VERSION ""

NS_ :

BS_:

BU_: AuxInput VT TECU TC Sprayer GPS

BO_ 2362179326 PD: 8 Vector__XXX
 SG_ ErrorElementNumber m13 : 4|12@1+ (1,0) [0|4095] "" Vector__XXX
 SG_ ErrorDDI m13 : 16|16@1+ (1,0) [0|65535] "" Vector__XXX
 SG_ ErrorCodeProcessData6 m13 : 37|1@1+ (1,0) [0|1] "" Vector__XXX
 SG_ ErrorCodeProcessData5 m13 : 36|1@1+ (1,0) [0|1] "" Vector__XXX
 SG_ ErrorCodeProcessData4 m13 : 35|1@1+ (1,0) [0|1] "" Vector__XXX
 SG_ ErrorCodeProcessData3 m13 : 34|1@1+ (1,0) [0|1] "" Vector__XXX
 SG_ ErrorCodeProcessData2 m13 : 33|1@1+ (1,0) [0|1] "" Vector__XXX
 SG_ ErrorCodeProcessData1 m13 : 32|1@1+ (1,0) [0|1] "" Vector__XXX
 SG_ Status_TotalsActive m15 : 32|1@1+ (1,0) [0|1] "" Vector__XXX
 SG_ ExecutedCommand m14 : 48|8@1+ (1,0) [0|65535] "" Vector__XXX
 SG_ SourceAddressWSM m14 : 40|8@1+ (1,0) [0|65535] "" Vector__XXX
 SG_ StatusBusyExecuting m14 : 35|1@1+ (1,0) [0|1] "" Vector__XXX
 SG_ StatusBusyReading m14 : 34|1@1+ (1,0) [0|1] "" Vector__XXX
 SG_ StatusBusySaving m14 : 33|1@1+ (1,0) [0|1] "" Vector__XXX
 SG_ StatusTotalsActive m14 : 32|1@1+ (1,0) [0|1] "" Vector__XXX
 SG_ ObjectIdChanged m13 : 8|16@1+ (1,0) [0|65535] "" Vector__XXX
 SG_ DesignatorLength m12 : 24|8@1+ (1,0) [0|255] "bytes" Vector__XXX
 SG_ ObjectIdToChange m12 : 8|16@1+ (1,0) [0|65535] "" Vector__XXX
 SG_ ErrorCodeChangeDesignator m13 : 24|8@1+ (1,0) [0|0] "" Vector__XXX
 SG_ ErrorCodeObjectPoolDelete m11 : 8|8@1+ (1,0) [0|0] "" Vector__XXX
 SG_ ErrorCodeObjPool4 m9 : 51|1@1+ (1,0) [0|0] "" Vector__XXX
 SG_ ErrorCodeObjPool3 m9 : 50|1@1+ (1,0) [0|0] "" Vector__XXX
 SG_ ErrorCodeObjPool2 m9 : 49|1@1+ (1,0) [0|0] "" Vector__XXX
 SG_ ErrorCodeObjPool1 m9 : 48|1@1+ (1,0) [0|0] "" Vector__XXX
 SG_ ErrorCodeObjPoolActiveResp3 m9 : 10|1@1+ (1,0) [0|0] "" Vector__XXX
 SG_ ErrorCodeObjPoolActiveResp2 m9 : 9|1@1+ (1,0) [0|0] "" Vector__XXX
 SG_ ErrorCodeObjPoolActiveResp1 m9 : 8|1@1+ (1,0) [0|0] "" Vector__XXX
 SG_ ObjectIdOfFaultyObject m9 : 32|16@1+ (1,0) [0|65535] "" Vector__XXX
 SG_ ParentObjectIdOfFaultyObject m9 : 16|16@1+ (1,0) [0|65535] "" Vector__XXX
 SG_ ReceivedDataSize m7 : 16|32@1+ (1,0) [0|4294967295] "bytes" Vector__XXX
 SG_ ErrorCodeObjPoolTransfer m7 : 8|8@1+ (1,0) [0|3] "" Vector__XXX
 SG_ Status m5 : 8|8@1+ (1,0) [0|1] "" Vector__XXX
 SG_ RequestTransferDataSize m4 : 8|32@1+ (1,0) [0|4294967295] "bytes" Vector__XXX
 SG_ TemperatureUnits m2 : 54|2@1+ (1,0) [0|3] "" Vector__XXX
 SG_ PressureUnits m2 : 52|2@1+ (1,0) [0|3] "" Vector__XXX
 SG_ ForceUnits m2 : 50|2@1+ (1,0) [0|3] "" Vector__XXX
 SG_ UnitsSystem m2 : 48|2@1+ (1,0) [0|3] "" Vector__XXX
 SG_ DistanceUnitCmd m2 : 46|2@1+ (1,0) [0|3] "" Vector__XXX
 SG_ AreaUnitCmd m2 : 44|2@1+ (1,0) [0|3] "" Vector__XXX
 SG_ VolumeUnitCmd m2 : 42|2@1+ (1,0) [0|3] "" Vector__XXX
 SG_ MassUnitCmd m2 : 40|2@1+ (1,0) [0|3] "" Vector__XXX
 SG_ DateFormatCmd m2 : 32|8@1+ (1,0) [0|255] "" Vector__XXX
 SG_ DecimalSymbolCmd m2 : 30|2@1+ (1,0) [0|3] "" Vector__XXX
 SG_ TimeFormatCmd m2 : 28|2@1+ (1,0) [0|3] "" Vector__XXX
 SG_ LanguageCodeCmd m2 : 8|16@1+ (1,0) [0|16383] "" Vector__XXX
 SG_ StructureLabel m1 : 8|56@1+ (1,0) [0|0] "" Vector__XXX
 SG_ DeviceDescriptionMsgType m1M : 4|4@1+ (1,0) [0|15] "" Vector__XXX
 SG_ VersionNumberISO11783Part10 m1 : 8|8@1- (1,0) [0|255] "" Vector__XXX
 SG_ TechnicalDataMsgType m0M : 4|4@1+ (1,0) [0|15] "" Vector__XXX
 SG_ Command M : 0|4@1+ (1,0) [0|15] "" Vector__XXX
 SG_ ElementNumber m2 : 4|12@1+ (1,0) [0|4095] "" Vector__XXX
 SG_ DDI m2M : 16|16@1+ (1,0) [0|65535] "" Vector__XXX
 SG_ MinMassPerAreaAppRate m152 : 32|32@1- (0.01,0) [0|2147480000] "mm³/m³" Vector__XXX
 SG_ DataDictionaryVersion m0 : 32|32@1- (1,0) [0|21474800] "" Vector__XXX
 SG_ RequestDefaultProcessData m57343 : 32|32@1- (1,0) [0|0] "" Vector__XXX
 SG_ AreaPerTimeCapacity m151 : 32|32@1- (1,0) [0|2147483647] "mm²/s" Vector__XXX
 SG_ FuelConsumptionPerArea m150 : 32|32@1- (1,0) [0|2147483647] "mm³/ m²" Vector__XXX
 SG_ FuelConsumptionPerTime m149 : 32|32@1- (1,0) [0|2147483647] "mm³/s" Vector__XXX
 SG_ TotalFuelConsumption m148 : 32|32@1- (1,0) [0|2147483647] "ml" Vector__XXX
 SG_ LogCount m147 : 32|32@1- (1,0) [0|2147483647] "" Vector__XXX
 SG_ PitchAngle m146 : 32|32@1- (0.001,0) [-180|180] "°" Vector__XXX
 SG_ RollAngle m145 : 32|32@1- (0.001,0) [-180|180] "°" Vector__XXX
 SG_ YawAngle m144 : 32|32@1- (0.001,0) [-180|180] "°" Vector__XXX
 SG_ ActualValueTimeLatency m143 : 32|32@1- (1,0) [-2147483647|2147483647] "ms" Vector__XXX
 SG_ SetpointTimeLatency m142 : 32|32@1- (1,0) [-2147483647|2147483647] "ms" Vector__XXX
 SG_ WorkState m141 : 32|32@1- (1,0) [0|3] "" Vector__XXX
 SG_ PercentageAppRateSetpoint m140 : 32|32@1- (1,0) [0|2147483647] "ppm" Vector__XXX
 SG_ DeviceCountCapacity m139 : 32|32@1- (1,0) [0|2147483647] "" Vector__XXX
 SG_ DeviceMassCapacity m138 : 32|32@1- (1,0) [0|2147483647] "g" Vector__XXX
 SG_ DeviceVolumeCapacity m137 : 32|32@1- (1,0) [0|2147483647] "ml" Vector__XXX
 SG_ DeviceElementOffsetZ m136 : 32|32@1- (1,0) [-2147483647|2147483647] "mm" Vector__XXX
 SG_ DeviceElementOffsetY m135 : 32|32@1- (1,0) [-2147483647|2147483647] "mm" Vector__XXX
 SG_ DeviceElementOffsetX m134 : 32|32@1- (1,0) [-2147483647|2147483647] "mm" Vector__XXX
 SG_ AuxiliaryValveInvertPorts m133 : 32|32@1- (1,0) [-2147480000|2147480000] "" Vector__XXX
 SG_ AuxiliaryValveProgressivRetract m132 : 32|32@1- (1,0) [-2147480000|2147480000] "" Vector__XXX
 SG_ AuxiliaryValveProgressivExtend m131 : 32|32@1- (1,0) [-2147483647|2147483647] "" Vector__XXX
 SG_ AuxiliaryValveFloatThreshold m130 : 32|32@1- (0.1,0) [-214748367.9|214748367.9] "%" Vector__XXX
 SG_ AuxiliaryValveRampRetractDown m129 : 32|32@1- (1,0) [-2147483647|2147483647] "ms" Vector__XXX
 SG_ AuxiliaryValveRampRetractUp m128 : 32|32@1- (1,0) [-2147483647|2147483647] "ms" Vector__XXX
 SG_ AuxiliaryValveRampExtendDown m127 : 32|32@1- (1,0) [-2147483647|2147483647] "ms" Vector__XXX
 SG_ AuxiliaryValveScalingRetract m125 : 32|32@1- (0.1,0) [-214748367.9|214748367.9] "%" Vector__XXX
 SG_ AuxiliaryValveScalingExtend m124 : 32|32@1- (0.1,0) [-214748367.9|214748367.9] "%" Vector__XXX
 SG_ AuxiliaryRampExtendUp m126 : 32|32@1- (1,0) [-2147483647|2147483647] "ms" Vector__XXX
 SG_ AppRateVolumePerArea_Set m1 : 32|32@1- (0.01,0) [0|21474836.47] "mm³/m²" Vector__XXX
 SG_ AppRateVolumePerArea_Act m2 : 32|32@1- (0.01,0) [0|21474836.47] "mm³/m²" Vector__XXX
 SG_ AppRateVolumePerArea_Def m3 : 32|32@1- (0.01,0) [0|21474836.47] "mm³/m²" Vector__XXX
 SG_ AppRateVolumePerArea_Min m4 : 32|32@1- (0.01,0) [0|21474836.47] "mm³/m²" Vector__XXX
 SG_ AppRateVolumePerArea_Max m5 : 32|32@1- (0.01,0) [0|21474836.47] "mm³/m²" Vector__XXX
 SG_ AppRateMassPerArea_Set m6 : 32|32@1- (1,0) [0|2147483647] "mg/m²" Vector__XXX
 SG_ AppRateMassPerArea_Act m7 : 32|32@1- (1,0) [0|2147483647] "mg/m²" Vector__XXX
 SG_ AppRateMassPerArea_Def m8 : 32|32@1- (1,0) [0|2147483647] "mg/m²" Vector__XXX
 SG_ AppRateMassPerArea_Min m9 : 32|32@1- (1,0) [0|2147483647] "mg/m²" Vector__XXX
 SG_ AppRateMassPerArea_Max m10 : 32|32@1- (1,0) [0|2147483647] "mg/m²" Vector__XXX
 SG_ AppRateCountPerArea_Set m11 : 32|32@1- (0.001,0) [0|2147483.647] "1/m²" Vector__XXX
 SG_ AppRateCountPerArea_Act m12 : 32|32@1- (0.001,0) [0|2147483.647] "1/m²" Vector__XXX
 SG_ AppRateCountPerArea_Def m13 : 32|32@1- (0.001,0) [0|2147483.647] "1/m²" Vector__XXX
 SG_ AppRateCountPerArea_Min m14 : 32|32@1- (0.001,0) [0|2147483.647] "1/m²" Vector__XXX
 SG_ AppRateCountPerArea_Max m15 : 32|32@1- (0.001,0) [0|2147483.647] "1/m²" Vector__XXX
 SG_ SetAppRateDistance_Set m16 : 32|32@1- (1,0) [0|2147483647] "mm" Vector__XXX
 SG_ AppRateDistance_Act m17 : 32|32@1- (1,0) [0|2147483647] "mm" Vector__XXX
 SG_ AppRateDistance_Def m18 : 32|32@1- (1,0) [0|2147483647] "mm" Vector__XXX
 SG_ AppRateDistance_Min m19 : 32|32@1- (1,0) [0|2147483647] "mm" Vector__XXX
 SG_ AppRateDistance_Max m20 : 32|32@1- (1,0) [0|2147483647] "mm" Vector__XXX
 SG_ AppRateVolumePerVolume_Set m21 : 32|32@1- (1,0) [0|2147483647] "mm³/m³" Vector__XXX
 SG_ AppRateVolumePerVolume_Act m22 : 32|32@1- (1,0) [0|2147483647] "mm³/m³" Vector__XXX
 SG_ AppRateVolumePerVolume_Def m23 : 32|32@1- (1,0) [0|2147483647] "mm³/m³" Vector__XXX
 SG_ AppRateVolumePerVolume_Min m24 : 32|32@1- (1,0) [0|2147483647] "mm³/m³" Vector__XXX
 SG_ AppRateVolumePerVolume_Max m25 : 32|32@1- (1,0) [0|2147483647] "mm³/m³" Vector__XXX
 SG_ AppRateMassPerMass_Set m26 : 32|32@1- (1,0) [0|2147483647] "mg/kg" Vector__XXX
 SG_ AppRateMassPerMass_Act m27 : 32|32@1- (1,0) [0|2147483647] "mg/kg" Vector__XXX
 SG_ AppRateMassPerMass_Def m28 : 32|32@1- (1,0) [0|2147483647] "mg/kg" Vector__XXX
 SG_ AppRateMassPerMass_Min m29 : 32|32@1- (1,0) [0|2147483647] "mg/kg" Vector__XXX
 SG_ AppRateMassPerMass_Max m30 : 32|32@1- (1,0) [0|2147483647] "mg/kg" Vector__XXX
 SG_ AppRateVolumePerMass_Set m31 : 32|32@1- (1,0) [0|2147483647] "mm³/kg" Vector__XXX
 SG_ AppRateVolumePerMass_Act m32 : 32|32@1- (1,0) [0|2147483647] "mm³/kg" Vector__XXX
 SG_ AppRateVolumePerMass_Def m33 : 32|32@1- (1,0) [0|2147483647] "mm³/kg" Vector__XXX
 SG_ AppRateVolumePerMass_Min m34 : 32|32@1- (1,0) [0|2147483647] "mm³/kg" Vector__XXX
 SG_ AppRateVolumePerMass_Max m35 : 32|32@1- (1,0) [0|2147483647] "mm³/kg" Vector__XXX
 SG_ AppRateVolumePerTime_Set m36 : 32|32@1- (1,0) [0|2147483647] "mm³/s" Vector__XXX
 SG_ AppRateVolumePerTime_Act m37 : 32|32@1- (1,0) [0|2147483647] "mm³/s" Vector__XXX
 SG_ AppRateVolumePerTime_Def m38 : 32|32@1- (1,0) [0|2147483647] "mm³/s" Vector__XXX
 SG_ AppRateVolumePerTime_Min m39 : 32|32@1- (1,0) [0|2147483647] "mm³/s" Vector__XXX
 SG_ AppRateVolumePerTime_Max m40 : 32|32@1- (1,0) [0|2147483647] "mm³/s" Vector__XXX
 SG_ AppRateMassPerTime_Set m41 : 32|32@1- (1,0) [0|2147483647] "mg/s" Vector__XXX
 SG_ AppRateMassPerTime_Act m42 : 32|32@1- (1,0) [0|2147483647] "mg/s" Vector__XXX
 SG_ AppRateMassPerTime_Def m43 : 32|32@1- (1,0) [0|2147483647] "mg/s" Vector__XXX
 SG_ AppRateMassPerTime_Min m44 : 32|32@1- (1,0) [0|2147483647] "mg/s" Vector__XXX
 SG_ AppRateMassPerTime_Max m45 : 32|32@1- (1,0) [0|2147483647] "mg/s" Vector__XXX
 SG_ AppRateCountPerTime_Set m46 : 32|32@1- (0.001,0) [0|2147483.647] "1/s" Vector__XXX
 SG_ AppRateCountPerTime_Act m47 : 32|32@1- (0.001,0) [0|2147483.647] "1/s" Vector__XXX
 SG_ AppRateCountPerTime_Def m48 : 32|32@1- (0.001,0) [0|2147483.647] "1/s" Vector__XXX
 SG_ AppRateCountPerTime_Min m49 : 32|32@1- (0.001,0) [0|2147483.647] "1/s" Vector__XXX
 SG_ AppRateCountPerTime_Max m50 : 32|32@1- (0.001,0) [0|2147483.647] "1/s" Vector__XXX
 SG_ SetTillageDepth_Set m51 : 32|32@1- (1,0) [0|2147483647] "mm" Vector__XXX
 SG_ TillageDepth_Act m52 : 32|32@1- (1,0) [0|2147483647] "mm" Vector__XXX
 SG_ TillageDepth_Def m53 : 32|32@1- (1,0) [0|2147483647] "mm" Vector__XXX
 SG_ TillageDepth_Min m54 : 32|32@1- (1,0) [0|2147483647] "mm" Vector__XXX
 SG_ TillageDepth_Max m55 : 32|32@1- (1,0) [0|2147483647] "mm" Vector__XXX
 SG_ SeedingDeph_Set m56 : 32|32@1- (1,0) [0|2147483647] "mm" Vector__XXX
 SG_ SeedingDeph_Act m57 : 32|32@1- (1,0) [0|2147483647] "mm" Vector__XXX
 SG_ SeedingDeph_Def m58 : 32|32@1- (1,0) [0|2147483647] "mm" Vector__XXX
 SG_ SeedingDeph_Min m59 : 32|32@1- (1,0) [0|2147483647] "mm" Vector__XXX
 SG_ SeedingDeph_Max m60 : 32|32@1- (1,0) [0|2147483647] "mm" Vector__XXX
 SG_ WorkingHeight_Set m61 : 32|32@1- (1,0) [0|2147483647] "mm" Vector__XXX
 SG_ WorkingHeight_Act m62 : 32|32@1- (1,0) [0|2147483647] "mm" Vector__XXX
 SG_ WorkingHeight_Def m63 : 32|32@1- (1,0) [0|2147483647] "mm" Vector__XXX
 SG_ WorkingHeight_Min m64 : 32|32@1- (1,0) [0|2147483647] "mm" Vector__XXX
 SG_ WorkingHeight_Max m65 : 32|32@1- (1,0) [0|2147483647] "mm" Vector__XXX
 SG_ WorkingWidth_Set m66 : 32|32@1- (1,0) [0|2147483647] "mm" Vector__XXX
 SG_ WorkingWidth_Act m67 : 32|32@1- (1,0) [0|2147483647] "mm" Vector__XXX
 SG_ WorkingWidth_Def m68 : 32|32@1- (1,0) [0|2147483647] "mm" Vector__XXX
 SG_ WorkingWidth_Min m69 : 32|32@1- (1,0) [0|2147483647] "mm" Vector__XXX
 SG_ WorkingWidth_Max m70 : 32|32@1- (1,0) [0|2147483647] "mm" Vector__XXX
 SG_ ContentAsVolume_Set m71 : 32|32@1- (1,0) [0|2147483647] "ml" Vector__XXX
 SG_ ContentAsVolume_Act m72 : 32|32@1- (1,0) [0|2147483647] "ml" Vector__XXX
 SG_ ContentAsVolume_Max m73 : 32|32@1- (1,0) [0|2147483647] "ml" Vector__XXX
 SG_ ContentAsMass_Set m74 : 32|32@1- (1,0) [0|2147483647] "g" Vector__XXX
 SG_ ContentAsMass_Act m75 : 32|32@1- (1,0) [0|2147483647] "g" Vector__XXX
 SG_ ContentAsMass_Max m76 : 32|32@1- (1,0) [0|2147483647] "g" Vector__XXX
 SG_ ContentAsCount_Set m77 : 32|32@1- (1,0) [0|2147483647] "" Vector__XXX
 SG_ ContentAsCount_Act m78 : 32|32@1- (1,0) [0|2147483647] "" Vector__XXX
 SG_ ContentAsCount_Max m79 : 32|32@1- (1,0) [0|2147483647] "" Vector__XXX
 SG_ AccumulatedAppAsVolume m80 : 32|32@1- (1,0) [0|2147483647] "l" Vector__XXX
 SG_ AccumulatedAppAsMass m81 : 32|32@1- (1,0) [0|2147483647] "kg" Vector__XXX
 SG_ AccumulatedAppAsCount m82 : 32|32@1- (1,0) [0|2147483647] "" Vector__XXX
 SG_ YieldVolumePerArea m83 : 32|32@1- (1,0) [0|2147483647] "ml/m²" Vector__XXX
 SG_ YieldMassPerArea m84 : 32|32@1- (1,0) [0|2147483647] "mg/m²" Vector__XXX
 SG_ YieldCountPerArea m85 : 32|32@1- (0.001,0) [0|2147483.647] "1/m²" Vector__XXX
 SG_ YieldVolumePerTime m86 : 32|32@1- (1,0) [0|2147483647] "ml/s" Vector__XXX
 SG_ YieldMassPerTime m87 : 32|32@1- (1,0) [0|2147483647] "mg/s" Vector__XXX
 SG_ YieldCountPerTime m88 : 32|32@1- (0.001,0) [0|2147483.647] "1/s" Vector__XXX
 SG_ AccumulatedYieldAsVolume m89 : 32|32@1- (1,0) [0|2147483647] "ml" Vector__XXX
 SG_ AccumulatedYieldAsMass m90 : 32|32@1- (1,0) [0|2147483647] "g" Vector__XXX
 SG_ AccumulatedYieldAsCount m91 : 32|32@1- (1,0) [0|2147483647] "" Vector__XXX
 SG_ CropYieldLossVolumePerArea m92 : 32|32@1- (1,0) [0|2147483647] "ml/m²" Vector__XXX
 SG_ CropYieldLossMassPerArea m93 : 32|32@1- (1,0) [0|2147483647] "mg/m²" Vector__XXX
 SG_ CropYieldLossCountPerArea m94 : 32|32@1- (0.001,0) [0|2147483.647] "1/m²" Vector__XXX
 SG_ CropYieldLossVolumePerTime m95 : 32|32@1- (1,0) [0|2147483647] "ml/s" Vector__XXX
 SG_ CropYieldLossMassPerTime m96 : 32|32@1- (1,0) [0|2147483647] "mg/s" Vector__XXX
 SG_ CropYieldLossCountPerTime m97 : 32|32@1- (0.001,0) [0|2147483.647] "1/s" Vector__XXX
 SG_ CropYieldLoss m98 : 32|32@1- (1,0) [0|2147483647] "ppm" Vector__XXX
 SG_ MoistureInCropYield m99 : 32|32@1- (1,0) [0|2147483647] "ppm" Vector__XXX
 SG_ DirtMaterialInCropYield m100 : 32|32@1- (1,0) [0|2147483647] "ppm" Vector__XXX
 SG_ BaleWidth_Set m101 : 32|32@1- (1,0) [0|2147483647] "mm" Vector__XXX
 SG_ BaleWidth_Act m102 : 32|32@1- (1,0) [0|2147483647] "mm" Vector__XXX
 SG_ BaleWidth_Def m103 : 32|32@1- (1,0) [0|2147483647] "mm" Vector__XXX
 SG_ BaleWidth_Min m104 : 32|32@1- (1,0) [0|2147483647] "mm" Vector__XXX
 SG_ BaleWidth_Max m105 : 32|32@1- (1,0) [0|2147483647] "mm" Vector__XXX
 SG_ BaleHeight_Set m106 : 32|32@1- (1,0) [0|2147483647] "mm" Vector__XXX
 SG_ BaleHeight_Act m107 : 32|32@1- (1,0) [0|2147483647] "mm" Vector__XXX
 SG_ BaleHeight_Def m108 : 32|32@1- (1,0) [0|2147483647] "mm" Vector__XXX
 SG_ BaleHeight_Min m109 : 32|32@1- (1,0) [0|2147483647] "mm" Vector__XXX
 SG_ BaleHeight_Max m110 : 32|32@1- (1,0) [0|2147483647] "mm" Vector__XXX
 SG_ BaleSize_Set m111 : 32|32@1- (1,0) [0|2147483647] "mm" Vector__XXX
 SG_ BaleSize_Act m112 : 32|32@1- (1,0) [0|2147483647] "mm" Vector__XXX
 SG_ BaleSize_Def m113 : 32|32@1- (1,0) [0|2147483647] "mm" Vector__XXX
 SG_ BaleSize_Min m114 : 32|32@1- (1,0) [0|2147483647] "mm" Vector__XXX
 SG_ BaleSize_Max m115 : 32|32@1- (1,0) [0|2147483647] "mm" Vector__XXX
 SG_ AccumulatedArea m116 : 32|32@1- (1,0) [0|2147483647] "m²" Vector__XXX
 SG_ AccumulatedDistanceInWork m117 : 32|32@1- (1,0) [0|2147483647] "mm" Vector__XXX
 SG_ AccumulatedDistanceOutWork m118 : 32|32@1- (1,0) [0|2147483647] "mm" Vector__XXX
 SG_ AccumulatedTimeInWork m119 : 32|32@1- (1,0) [0|2147483647] "s" Vector__XXX
 SG_ AccumulatedTimeOutWork m120 : 32|32@1- (1,0) [0|2147483647] "s" Vector__XXX
 SG_ PrdoucDensityMassPerArea m121 : 32|32@1- (1,0) [0|2147483647] "g/l" Vector__XXX
 SG_ PrdoucDensityMassPerCount m122 : 32|32@1- (1,0) [0|2147483647] "mg/1000" Vector__XXX
 SG_ PrdoucDensityVolumePerCount m123 : 32|32@1- (1,0) [0|2147483647] "ml/1000" Vector__XXX

BO_ 2565406462 ACKM: 8 Vector__XXX
 SG_ ParameterGroupNumber : 40|24@1+ (1,0) [0|0] "" Vector__XXX
 SG_ AddressBusy m3 : 32|8@1+ (1,0) [0|0] "" Vector__XXX
 SG_ AddressAccessDenied m2 : 32|8@1+ (1,0) [0|0] "" Vector__XXX
 SG_ AddressNegativeAcknowledgement m1 : 32|8@1+ (1,0) [0|0] "" Vector__XXX
 SG_ AddressAcknowledged m0 : 32|8@1+ (1,0) [0|0] "" Vector__XXX
 SG_ GroupFunctionValue : 8|8@1+ (1,0) [0|0] "" Vector__XXX
 SG_ ControlByte M : 0|8@1+ (1,0) [0|0] "" Vector__XXX

BO_ 2147483648 CAPL_IDS: 1785 Vector__XXX

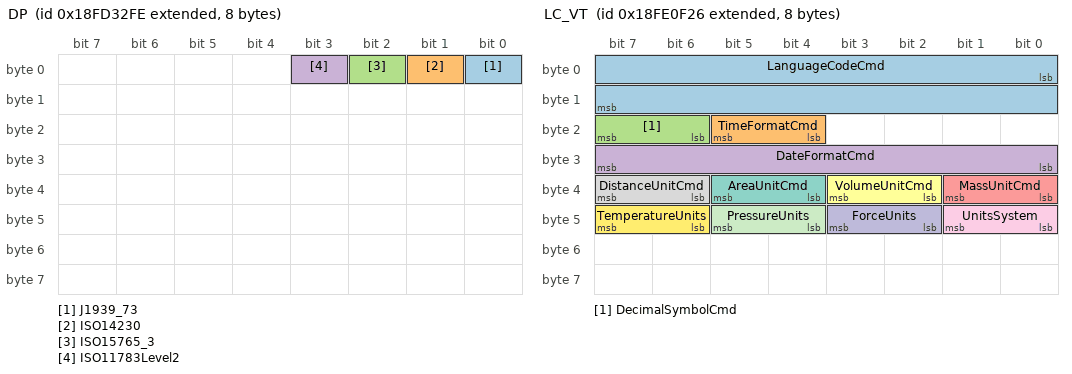
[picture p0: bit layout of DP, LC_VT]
BO_ 2566730494 DP: 8 Vector__XXX
 SG_ J1939_73 : 0|1@1+ (1,0) [0|1] "" Vector__XXX
 SG_ ISO14230 : 1|1@1+ (1,0) [0|1] "" Vector__XXX
 SG_ ISO15765_3 : 2|1@1+ (1,0) [0|1] "" Vector__XXX
 SG_ ISO11783Level2 : 3|1@1+ (1,0) [0|1] "" Vector__XXX

BO_ 2566734590 ICC: 8 Vector__XXX
 SG_ CertLaboratoryType_FirstDef m0 : 9|3@1+ (1,0) [0|7] "" Vector__XXX
 SG_ TestProtocolRevision_MSBits m1 : 11|2@1+ (1,0) [0|0] "" Vector__XXX
 SG_ MessageRevision M : 47|1@1+ (1,0) [0|0] "" Vector__XXX
 SG_ CertLaboratoryType_SecondDef m1 : 9|2@1+ (1,0) [0|3] "" Vector__XXX
 SG_ TestProtocolRevision : 6|3@1+ (1,0) [0|7] "" Vector__XXX
 SG_ TestProtocolPublicationYear : 0|6@1+ (1,2000) [2000|2061] "year" Vector__XXX
 SG_ CertificationLaboratoryID : 13|11@1+ (1,0) [0|2047] "" Vector__XXX
 SG_ CertTypeVTWorkingSetMember m0 : 24|1@1+ (1,0) [0|1] "" Vector__XXX
 SG_ CertTypeVTWorkingSetMaster m0 : 25|1@1+ (1,0) [0|1] "" Vector__XXX
 SG_ CertTypeVirtualTerminal m0 : 26|1@1+ (1,0) [0|1] "" Vector__XXX
 SG_ CertTypeClass3ECU m0 : 27|1@1+ (1,0) [0|1] "" Vector__XXX
 SG_ CertTypeTECUClass3 m0 : 28|1@1+ (1,0) [0|1] "" Vector__XXX
 SG_ CertTypeTECUClass2 m0 : 29|1@1+ (1,0) [0|1] "" Vector__XXX
 SG_ CertTypeTECUClass1 m0 : 30|1@1+ (1,0) [0|1] "" Vector__XXX
 SG_ CertTypeMinimumECU m0 : 31|1@1+ (1,0) [0|1] "" Vector__XXX
 SG_ CertTypeGPSReceiver m0 : 35|1@1+ (1,0) [0|1] "" Vector__XXX
 SG_ CertTypeFileServer m0 : 36|1@1+ (1,0) [0|1] "" Vector__XXX
 SG_ CertTypeTCWorkingSetMember m0 : 37|1@1+ (1,0) [0|1] "" Vector__XXX
 SG_ CertTypeTCWorkingSetMaster m0 : 38|1@1+ (1,0) [0|1] "" Vector__XXX
 SG_ CertTypeTaskController m0 : 39|1@1+ (1,0) [0|1] "" Vector__XXX
 SG_ CertificationReferenceNumber : 48|16@1+ (1,0) [0|65535] "" Vector__XXX

BO_ 2566835454 DM3: 0 Vector__XXX

BO_ 2633895296 WSMSTR_Sprayer: 8 Sprayer
 SG_ NumberOfMembersInWorkingSet : 0|8@1+ (1,0) [1|250] "" Vector__XXX

BO_ 2566786854 LC_VT: 8 VT
 SG_ LanguageCodeCmd : 0|16@1+ (1,0) [0|16383] ""  Sprayer
 SG_ TimeFormatCmd : 20|2@1+ (1,0) [0|3] "" Vector__XXX
 SG_ DecimalSymbolCmd : 22|2@1+ (1,0) [0|3] "" Vector__XXX
 SG_ DateFormatCmd : 24|8@1+ (1,0) [0|255] "" Vector__XXX
 SG_ MassUnitCmd : 32|2@1+ (1,0) [0|3] "" Vector__XXX
 SG_ VolumeUnitCmd : 34|2@1+ (1,0) [0|3] "" Vector__XXX
 SG_ AreaUnitCmd : 36|2@1+ (1,0) [0|3] "" Vector__XXX
 SG_ DistanceUnitCmd : 38|2@1+ (1,0) [0|3] "" Vector__XXX
 SG_ UnitsSystem : 40|2@1+ (1,0) [0|3] "" Vector__XXX
 SG_ ForceUnits : 42|2@1+ (1,0) [0|3] "" Vector__XXX
 SG_ PressureUnits : 44|2@1+ (1,0) [0|3] "" Vector__XXX
 SG_ TemperatureUnits : 46|2@1+ (1,0) [0|3] "" Vector__XXX

BO_ 2565799462 ACL_VT: 8 VT
 SG_ ArbitraryAddressCapable : 63|1@1+ (1,0) [0|1] "" Vector__XXX
 SG_ IndustryGroup M : 60|3@1+ (1,0) [0|7] "" Vector__XXX
 SG_ VehicleSystemInstance : 56|4@1+ (1,0) [0|15] "" Vector__XXX
 SG_ Function : 40|8@1+ (1,0) [0|255] "" Vector__XXX
 SG_ FunctionInstance : 35|5@1+ (1,0) [0|31] "" Vector__XXX
 SG_ ECUInstance : 32|3@1+ (1,0) [0|7] "" Vector__XXX
 SG_ ManufacturerCode : 21|11@1+ (1,0) [0|2047] "" Vector__XXX
 SG_ IdentityNumber : 0|21@1+ (1,0) [0|2097150] "" Vector__XXX
 SG_ VehicleSystem m0 : 49|7@1+ (1,0) [0|127] "" Vector__XXX
 SG_ VehicleSystem5 m5 : 49|7@1+ (1,0) [0|127] "" Vector__XXX
 SG_ VehicleSystem4 m4 : 49|7@1+ (1,0) [0|127] "" Vector__XXX
 SG_ VehicleSystem3 m3 : 49|7@1+ (1,0) [0|127] "" Vector__XXX
 SG_ VehicleSystem2 m2 : 49|7@1+ (1,0) [0|127] "" Vector__XXX
 SG_ VehicleSystem1 m1 : 49|7@1+ (1,0) [0|127] "" Vector__XXX

BO_ 2565799664 ACL_TECU: 8 TECU
 SG_ ArbitraryAddressCapable : 63|1@1+ (1,0) [0|1] "" Vector__XXX
 SG_ IndustryGroup M : 60|3@1+ (1,0) [0|7] "" Vector__XXX
 SG_ VehicleSystemInstance : 56|4@1+ (1,0) [0|15] "" Vector__XXX
 SG_ Function : 40|8@1+ (1,0) [0|255] "" Vector__XXX
 SG_ FunctionInstance : 35|5@1+ (1,0) [0|31] "" Vector__XXX
 SG_ ECUInstance : 32|3@1+ (1,0) [0|7] "" Vector__XXX
 SG_ ManufacturerCode : 21|11@1+ (1,0) [0|2047] "" Vector__XXX
 SG_ IdentityNumber : 0|21@1+ (1,0) [0|2097150] "" Vector__XXX
 SG_ VehicleSystem m0 : 49|7@1+ (1,0) [0|127] "" Vector__XXX
 SG_ VehicleSystem5 m5 : 49|7@1+ (1,0) [0|127] "" Vector__XXX
 SG_ VehicleSystem4 m4 : 49|7@1+ (1,0) [0|127] "" Vector__XXX
 SG_ VehicleSystem3 m3 : 49|7@1+ (1,0) [0|127] "" Vector__XXX
 SG_ VehicleSystem2 m2 : 49|7@1+ (1,0) [0|127] "" Vector__XXX
 SG_ VehicleSystem1 m1 : 49|7@1+ (1,0) [0|127] "" Vector__XXX

BO_ 2565799671 ACL_TC: 8 TC
 SG_ ArbitraryAddressCapable : 63|1@1+ (1,0) [0|1] "" Vector__XXX
 SG_ IndustryGroup M : 60|3@1+ (1,0) [0|7] "" Vector__XXX
 SG_ VehicleSystemInstance : 56|4@1+ (1,0) [0|15] "" Vector__XXX
 SG_ Function : 40|8@1+ (1,0) [0|255] "" Vector__XXX
 SG_ FunctionInstance : 35|5@1+ (1,0) [0|31] "" Vector__XXX
 SG_ ECUInstance : 32|3@1+ (1,0) [0|7] "" Vector__XXX
 SG_ ManufacturerCode : 21|11@1+ (1,0) [0|2047] "" Vector__XXX
 SG_ IdentityNumber : 0|21@1+ (1,0) [0|2097150] "" Vector__XXX
 SG_ VehicleSystem m0 : 49|7@1+ (1,0) [0|127] "" Vector__XXX
 SG_ VehicleSystem5 m5 : 49|7@1+ (1,0) [0|127] "" Vector__XXX
 SG_ VehicleSystem4 m4 : 49|7@1+ (1,0) [0|127] "" Vector__XXX
 SG_ VehicleSystem3 m3 : 49|7@1+ (1,0) [0|127] "" Vector__XXX
 SG_ VehicleSystem2 m2 : 49|7@1+ (1,0) [0|127] "" Vector__XXX
 SG_ VehicleSystem1 m1 : 49|7@1+ (1,0) [0|127] "" Vector__XXX

BO_ 2565799552 ACL_Sprayer: 8 Sprayer
 SG_ ArbitraryAddressCapable : 63|1@1+ (1,0) [0|1] "" Vector__XXX
 SG_ IndustryGroup M : 60|3@1+ (1,0) [0|7] "" Vector__XXX
 SG_ VehicleSystemInstance : 56|4@1+ (1,0) [0|15] "" Vector__XXX
 SG_ Function : 40|8@1+ (1,0) [0|255] "" Vector__XXX
 SG_ FunctionInstance : 35|5@1+ (1,0) [0|31] "" Vector__XXX
 SG_ ECUInstance : 32|3@1+ (1,0) [0|7] "" Vector__XXX
 SG_ ManufacturerCode : 21|11@1+ (1,0) [0|2047] "" Vector__XXX
 SG_ IdentityNumber : 0|21@1+ (1,0) [0|2097150] "" Vector__XXX
 SG_ VehicleSystem m0 : 49|7@1+ (1,0) [0|127] "" Vector__XXX
 SG_ VehicleSystem5 m5 : 49|7@1+ (1,0) [0|127] "" Vector__XXX
 SG_ VehicleSystem4 m4 : 49|7@1+ (1,0) [0|127] "" Vector__XXX
 SG_ VehicleSystem3 m3 : 49|7@1+ (1,0) [0|127] "" Vector__XXX
 SG_ VehicleSystem2 m2 : 49|7@1+ (1,0) [0|127] "" Vector__XXX
 SG_ VehicleSystem1 m1 : 49|7@1+ (1,0) [0|127] "" Vector__XXX

BO_ 2565799452 ACL_GPS: 8 GPS
 SG_ ArbitraryAddressCapable : 63|1@1+ (1,0) [0|1] "" Vector__XXX
 SG_ IndustryGroup M : 60|3@1+ (1,0) [0|7] "" Vector__XXX
 SG_ VehicleSystemInstance : 56|4@1+ (1,0) [0|15] "" Vector__XXX
 SG_ Function : 40|8@1+ (1,0) [0|255] "" Vector__XXX
 SG_ FunctionInstance : 35|5@1+ (1,0) [0|31] "" Vector__XXX
 SG_ ECUInstance : 32|3@1+ (1,0) [0|7] "" Vector__XXX
 SG_ ManufacturerCode : 21|11@1+ (1,0) [0|2047] "" Vector__XXX
 SG_ IdentityNumber : 0|21@1+ (1,0) [0|2097150] "" Vector__XXX
 SG_ VehicleSystem m0 : 49|7@1+ (1,0) [0|127] "" Vector__XXX
 SG_ VehicleSystem5 m5 : 49|7@1+ (1,0) [0|127] "" Vector__XXX
 SG_ VehicleSystem4 m4 : 49|7@1+ (1,0) [0|127] "" Vector__XXX
 SG_ VehicleSystem3 m3 : 49|7@1+ (1,0) [0|127] "" Vector__XXX
 SG_ VehicleSystem2 m2 : 49|7@1+ (1,0) [0|127] "" Vector__XXX
 SG_ VehicleSystem1 m1 : 49|7@1+ (1,0) [0|127] "" Vector__XXX

BO_ 2566835198 DM2: 22 Vector__XXX
 SG_ DTC5 : 144|32@1+ (1,0) [0|4294967295] "" Vector__XXX
 SG_ DTC4 : 112|32@1+ (1,0) [0|4294967295] "" Vector__XXX
 SG_ DTC3 : 80|32@1+ (1,0) [0|4294967295] "" Vector__XXX
 SG_ DTC2 : 48|32@1+ (1,0) [0|4294967295] "" Vector__XXX
 SG_ DTC1 : 16|32@1+ (1,0) [0|4294967295] "" Vector__XXX
 SG_ MalfunctionIndicatorLampStatus : 6|2@1+ (1,0) [0|3] "" Vector__XXX
 SG_ RedStopLampState : 4|2@1+ (1,0) [0|3] "" Vector__XXX
 SG_ AmberWarningLampStatus : 2|2@1+ (1,0) [0|3] "" Vector__XXX
 SG_ ProtectLampStatus : 0|2@1+ (1,0) [0|3] "" Vector__XXX
 SG_ FlashRedStopLamp : 12|2@1+ (1,0) [0|3] "" Vector__XXX
 SG_ FlashProtectLamp : 8|2@1+ (1,0) [0|3] "" Vector__XXX
 SG_ FlashMalfuncIndicatorLamp : 14|2@1+ (1,0) [0|3] "" Vector__XXX
 SG_ FlashAmberWarningLamp : 10|2@1+ (1,0) [0|3] "" Vector__XXX

BO_ 2566834942 DM1: 22 Vector__XXX
 SG_ DTC5 : 144|32@1+ (1,0) [0|4294967295] "" Vector__XXX
 SG_ DTC4 : 112|32@1+ (1,0) [0|4294967295] "" Vector__XXX
 SG_ DTC3 : 80|32@1+ (1,0) [0|4294967295] "" Vector__XXX
 SG_ DTC2 : 48|32@1+ (1,0) [0|4294967295] "" Vector__XXX
 SG_ DTC1 : 16|32@1+ (1,0) [0|4294967295] "" Vector__XXX
 SG_ FlashRedStopLamp : 12|2@1+ (1,0) [0|3] "" Vector__XXX
 SG_ FlashProtectLamp : 8|2@1+ (1,0) [0|3] "" Vector__XXX
 SG_ FlashMalfuncIndicatorLamp : 14|2@1+ (1,0) [0|3] "" Vector__XXX
 SG_ FlashAmberWarningLamp : 10|2@1+ (1,0) [0|3] "" Vector__XXX
 SG_ MalfunctionIndicatorLampStatus : 6|2@1+ (1,0) [0|3] "" Vector__XXX
 SG_ AmberWarningLampStatus : 2|2@1+ (1,0) [0|3] "" Vector__XXX
 SG_ RedStopLampState : 4|2@1+ (1,0) [0|3] "" Vector__XXX
 SG_ ProtectLampStatus : 0|2@1+ (1,0) [0|3] "" Vector__XXX

BO_ 2566839038 SOFT: 1700 Vector__XXX
 SG_ SoftwareID3 : 24|8@1+ (1,0) [0|255] "" Vector__XXX
 SG_ SoftwareID2 : 16|8@1+ (1,0) [0|255] "" Vector__XXX
 SG_ SoftwareID1 : 8|8@1+ (1,0) [0|255] "" Vector__XXX
 SG_ NmbrOfSftwrIdentificationFields : 0|8@1+ (1,0) [0|250] "steps" Vector__XXX

BO_ 2566768126 ECUID: 1024 Vector__XXX
 SG_ ECUHardwareID : 40|8@1+ (1,0) [0|255] "" Vector__XXX
 SG_ ECUManufacturerName : 32|8@1+ (1,0) [0|255] "" Vector__XXX
 SG_ ECUType : 24|8@1+ (1,0) [0|255] "" Vector__XXX
 SG_ ECULocation : 16|8@1+ (1,0) [0|255] "" Vector__XXX
 SG_ ECUSerialNumber : 8|8@1+ (1,0) [0|255] "" Vector__XXX
 SG_ ECUPartNumber : 0|8@1+ (1,0) [0|255] "" Vector__XXX

BO_ 2566838526 CA: 9 Vector__XXX
 SG_ AddressAssignment : 64|8@1+ (1,0) [0|255] "" Vector__XXX
 SG_ ArbitraryAddressCapable : 63|1@1+ (1,0) [0|1] "" Vector__XXX
 SG_ IndustryGroup M : 60|3@1+ (1,0) [0|7] "" Vector__XXX
 SG_ VehicleSystemInstance : 56|4@1+ (1,0) [0|15] "" Vector__XXX
 SG_ Function : 40|8@1+ (1,0) [0|255] "" Vector__XXX
 SG_ VehicleSystem m0 : 49|7@1+ (1,0) [0|127] "" Vector__XXX
 SG_ FunctionInstance : 35|5@1+ (1,0) [0|31] "" Vector__XXX
 SG_ ECUInstance : 32|3@1+ (1,0) [0|7] "" Vector__XXX
 SG_ ManufacturerCode : 21|11@1+ (1,0) [0|2047] "" Vector__XXX
 SG_ IdentityNumber : 0|21@1+ (1,0) [0|2097150] "" Vector__XXX
 SG_ VehicleSystem5 m5 : 49|7@1+ (1,0) [0|127] "" Vector__XXX
 SG_ VehicleSystem4 m4 : 49|7@1+ (1,0) [0|127] "" Vector__XXX
 SG_ VehicleSystem3 m3 : 49|7@1+ (1,0) [0|127] "" Vector__XXX
 SG_ VehicleSystem2 m2 : 49|7@1+ (1,0) [0|127] "" Vector__XXX
 SG_ VehicleSystem1 m1 : 49|7@1+ (1,0) [0|127] "" Vector__XXX

BO_ 2565799678 ACL: 8 Vector__XXX
 SG_ ArbitraryAddressCapable : 63|1@1+ (1,0) [0|1] "" Vector__XXX
 SG_ IndustryGroup M : 60|3@1+ (1,0) [0|7] "" Vector__XXX
 SG_ VehicleSystemInstance : 56|4@1+ (1,0) [0|15] "" Vector__XXX
 SG_ Function : 40|8@1+ (1,0) [0|255] "" Vector__XXX
 SG_ FunctionInstance : 35|5@1+ (1,0) [0|31] "" Vector__XXX
 SG_ ECUInstance : 32|3@1+ (1,0) [0|7] "" Vector__XXX
 SG_ ManufacturerCode : 21|11@1+ (1,0) [0|2047] "" Vector__XXX
 SG_ IdentityNumber : 0|21@1+ (1,0) [0|2097150] "" Vector__XXX
 SG_ VehicleSystem m0 : 49|7@1+ (1,0) [0|127] "" Vector__XXX
 SG_ VehicleSystem5 m5 : 49|7@1+ (1,0) [0|127] "" Vector__XXX
 SG_ VehicleSystem4 m4 : 49|7@1+ (1,0) [0|127] "" Vector__XXX
 SG_ VehicleSystem3 m3 : 49|7@1+ (1,0) [0|127] "" Vector__XXX
 SG_ VehicleSystem2 m2 : 49|7@1+ (1,0) [0|127] "" Vector__XXX
 SG_ VehicleSystem1 m1 : 49|7@1+ (1,0) [0|127] "" Vector__XXX

CM_ BO_ 2362179326 "Request for Repetition Rates";
CM_ SG_ 2362179326 ErrorElementNumber "Device Element Number";
CM_ SG_ 2362179326 ErrorDDI "Data Dictionary Identifier";
CM_ SG_ 2362179326 Command "Process Data Command";
CM_ SG_ 2362179326 ElementNumber "Device Element Number";
CM_ SG_ 2362179326 DDI "Data Dictionary Identifier";
CM_ SG_ 2362179326 MinMassPerAreaAppRate "Minimum Application Rate specified as mass per area";
CM_ SG_ 2362179326 DataDictionaryVersion "This DDE is used to specify which version of the Data Dictionary is being used.";
CM_ SG_ 2362179326 RequestDefaultProcessData "Request Default Process Data.";
CM_ SG_ 2362179326 AreaPerTimeCapacity "Area per time capacity";
CM_ SG_ 2362179326 FuelConsumptionPerArea "Fuel consumption per area";
CM_ SG_ 2362179326 FuelConsumptionPerTime "Fuel consumption per time";
CM_ SG_ 2362179326 TotalFuelConsumption "Accumulated Fuel Consumption as Counter";
CM_ SG_ 2362179326 LogCount "Log Counter, may be used to control data log record generation on a
Task Controller";
CM_ SG_ 2362179326 PitchAngle "Pitch Angle of a DeviceElement";
CM_ SG_ 2362179326 RollAngle "Roll Angle of a DeviceElement";
CM_ SG_ 2362179326 YawAngle "Pivot / Yaw Angle of a DeviceElement";
CM_ SG_ 2362179326 ActualValueTimeLatency "Temporal Latency valid for the actual value of a Device Element";
CM_ SG_ 2362179326 SetpointTimeLatency "Temporal Latency valid for the setpoint values of a Device Element";
CM_ SG_ 2362179326 PercentageAppRateSetpoint "Application Rate expressed as percentage";
CM_ SG_ 2362179326 DeviceCountCapacity "DeviceElement Count Capacity, dimension of a DeviceElement";
CM_ SG_ 2362179326 DeviceMassCapacity "DeviceElement Mass Capacity, dimension of a DeviceElement.";
CM_ SG_ 2362179326 DeviceVolumeCapacity "DeviceElement Volume Capacity, dimension of a DeviceElement.";
CM_ SG_ 2362179326 DeviceElementOffsetZ "Z direction offset of a DeviceElement relative to  Device.";
CM_ SG_ 2362179326 DeviceElementOffsetY "Y direction offset of a DeviceElement relative to  Device.";
CM_ SG_ 2362179326 DeviceElementOffsetX "X direction offset of a DeviceElement relative to a Device.";
CM_ SG_ 2362179326 AuxiliaryValveInvertPorts "Command valve to swap extend and retract ports, easier than redoing
plumbing on valve.";
CM_ SG_ 2362179326 AuxiliaryValveProgressivRetract "Define non-linear releationship between command and flow by 2nd
degree polynomium.";
CM_ SG_ 2362179326 AuxiliaryValveProgressivExtend "Define non-linear releationship between command and flow by 2nd
degree polynomium.";
CM_ SG_ 2362179326 AuxiliaryValveFloatThreshold "Safety function. Current output of valve must be above threshold before
float command is allowed.";
CM_ SG_ 2362179326 AuxiliaryValveRampRetractDown "The valve will apply a ramp to the Auxiliary ValveCommand
PortFlowCommand, to limit the acceleration or deceleration of flow.";
CM_ SG_ 2362179326 AuxiliaryValveRampRetractUp "The valve will apply a ramp to theAuxiliary ValveCommand
PortFlowCommand, to limit the acceleration or deceleration of flow.";
CM_ SG_ 2362179326 AuxiliaryValveRampExtendDown "The valve will apply a ramp to the Auxiliary ValveCommand
PortFlowCommand, to limit the acceleration or deceleration of flow.";
CM_ SG_ 2362179326 AuxiliaryValveScalingRetract "Factor to apply to AuxValveCommand PortFlowCommand.";
CM_ SG_ 2362179326 AuxiliaryValveScalingExtend "Factor to apply to AuxValveCommand PortFlowCommand.";
CM_ SG_ 2362179326 AuxiliaryRampExtendUp "The valve will apply a ramp to the Auxiliary ValveCommand
PortFlowCommand, to limit the acceleration or deceleration of flow.";
CM_ SG_ 2362179326 AppRateVolumePerArea_Set "Setpoint Application Rate specified as volume per area";
CM_ SG_ 2362179326 AppRateVolumePerArea_Act "Actual Application Rate specified as volume per area";
CM_ SG_ 2362179326 AppRateVolumePerArea_Def "Default Application Rate specified as volume per area";
CM_ SG_ 2362179326 AppRateVolumePerArea_Min "Minimum Application Rate specified as volume per area";
CM_ SG_ 2362179326 AppRateVolumePerArea_Max "Maximum Application Rate specified as volume per area";
CM_ SG_ 2362179326 AppRateMassPerArea_Set "Setpoint Application Rate specified as mass per area";
CM_ SG_ 2362179326 AppRateMassPerArea_Act "Actual Application Rate specified as mass per area";
CM_ SG_ 2362179326 AppRateMassPerArea_Def "Default Application Rate specified as mass per area";
CM_ SG_ 2362179326 AppRateMassPerArea_Min "Minimum Application Rate specified as mass per area";
CM_ SG_ 2362179326 AppRateMassPerArea_Max "Maximum Application Rate specified as mass per area";
CM_ SG_ 2362179326 AppRateCountPerArea_Set "Setpoint Application Rate specified as count per area";
CM_ SG_ 2362179326 AppRateCountPerArea_Act "Actual Application Rate specified as count per area";
CM_ SG_ 2362179326 AppRateCountPerArea_Def "Default Application Rate specified as count per area";
CM_ SG_ 2362179326 AppRateCountPerArea_Min "Minimum Application Rate specified as count per area";
CM_ SG_ 2362179326 AppRateCountPerArea_Max "Maximum Application Rate specified as count per area";
CM_ SG_ 2362179326 SetAppRateDistance_Set "Setpoint Application Rate specified as distance";
CM_ SG_ 2362179326 AppRateDistance_Act "Actual Application Rate specified as distance";
CM_ SG_ 2362179326 AppRateDistance_Def "Default Application Rate specified as distance";
CM_ SG_ 2362179326 AppRateDistance_Min "Minimum Application Rate specified as distance";
CM_ SG_ 2362179326 AppRateDistance_Max "Maximum Application Rate specified as distance";
CM_ SG_ 2362179326 AppRateVolumePerVolume_Set "Setpoint Application Rate specified as volume per volume";
CM_ SG_ 2362179326 AppRateVolumePerVolume_Act "Actual Application Rate specified as volume per volume";
CM_ SG_ 2362179326 AppRateVolumePerVolume_Def "Default Application Rate specified as volume per volume";
CM_ SG_ 2362179326 AppRateVolumePerVolume_Min "Minimum Application Rate specified as volume per volume";
CM_ SG_ 2362179326 AppRateVolumePerVolume_Max "Maximum Application Rate specified as volume per volume";
CM_ SG_ 2362179326 AppRateMassPerMass_Set "Setpoint Application Rate specified as mass per mass";
CM_ SG_ 2362179326 AppRateMassPerMass_Act "Actual Application Rate specified as mass per mass";
CM_ SG_ 2362179326 AppRateMassPerMass_Def "Default Application Rate specified as mass per mass";
CM_ SG_ 2362179326 AppRateMassPerMass_Min "Minimum Application Rate specified as mass per mass";
CM_ SG_ 2362179326 AppRateMassPerMass_Max "Maximum Application Rate specified as mass per mass";
CM_ SG_ 2362179326 AppRateVolumePerMass_Set "Setpoint Application Rate specified as volume per mass";
CM_ SG_ 2362179326 AppRateVolumePerMass_Act "Actual Application Rate specified as volume per mass";
CM_ SG_ 2362179326 AppRateVolumePerMass_Def "Default Application Rate specified as volume per mass";
CM_ SG_ 2362179326 AppRateVolumePerMass_Min "Minimum Application Rate specified as volume per mass";
CM_ SG_ 2362179326 AppRateVolumePerMass_Max "Maximum Application Rate specified as volume per mass";
CM_ SG_ 2362179326 AppRateVolumePerTime_Set "Setpoint Application Rate specified as volume per time";
CM_ SG_ 2362179326 AppRateVolumePerTime_Act "Actual Application Rate specified as volume per time";
CM_ SG_ 2362179326 AppRateVolumePerTime_Def "Default Application Rate specified as volume per time";
CM_ SG_ 2362179326 AppRateVolumePerTime_Min "Minimum Application Rate specified as volume per time";
CM_ SG_ 2362179326 AppRateVolumePerTime_Max "Maximum Application Rate specified as volume per time";
CM_ SG_ 2362179326 AppRateMassPerTime_Set "Setpoint Application Rate specified as mass per time";
CM_ SG_ 2362179326 AppRateMassPerTime_Act "Actual Application Rate specified as mass per time";
CM_ SG_ 2362179326 AppRateMassPerTime_Def "Defaut Application Rate specified as mass per time";
CM_ SG_ 2362179326 AppRateMassPerTime_Min "Minimum Application Rate specified as mass per time";
CM_ SG_ 2362179326 AppRateMassPerTime_Max "Maximum Application Rate specified as mass per time";
CM_ SG_ 2362179326 AppRateCountPerTime_Set "Setpoint Application Rate specified as count per time";
CM_ SG_ 2362179326 AppRateCountPerTime_Act "Actual Application Rate specified as count per time";
CM_ SG_ 2362179326 AppRateCountPerTime_Def "Default Application Rate specified as count per time";
CM_ SG_ 2362179326 AppRateCountPerTime_Min "Minimum Application Rate specified as count per time";
CM_ SG_ 2362179326 AppRateCountPerTime_Max "Maximum Application Rate specified as count per time";
CM_ SG_ 2362179326 SetTillageDepth_Set "Setpoint Tillage Depth of Machine Element below soil surface, value increases with depth";
CM_ SG_ 2362179326 TillageDepth_Act "Actual Tillage Depth of Machine Element below soil surface, value increases with depth";
CM_ SG_ 2362179326 TillageDepth_Def "Default Tillage Depth of Machine Element below soil surface, value increases with depth";
CM_ SG_ 2362179326 TillageDepth_Min "Minimum Tillage Depth of Machine Element below soil surface, value increases with depth";
CM_ SG_ 2362179326 TillageDepth_Max "Maximum Tillage Depth of Machine Element below soil surface, value increases with depth";
CM_ SG_ 2362179326 SeedingDeph_Set "Setpoint Seeding Depth of Machine Element below soil surface, value increases with depth";
CM_ SG_ 2362179326 SeedingDeph_Act "Setpoint Seeding Depth of Machine Element below soil surface, value increases with depth";
CM_ SG_ 2362179326 SeedingDeph_Def "Setpoint Seeding Depth of Machine Element below soil surface, value increases with depth";
CM_ SG_ 2362179326 SeedingDeph_Min "Setpoint Seeding Depth of Machine Element below soil surface, value increases with depth";
CM_ SG_ 2362179326 SeedingDeph_Max "Setpoint Seeding Depth of Machine Element below soil surface, value increases with depth";
CM_ SG_ 2362179326 WorkingHeight_Set "Setpoint Working Height of Machine Element above crop or soil";
CM_ SG_ 2362179326 WorkingHeight_Act "Actual Working Height of Machine Element above crop or soil";
CM_ SG_ 2362179326 WorkingHeight_Def "Default Working Height of Machine Element above crop or soil";
CM_ SG_ 2362179326 WorkingHeight_Min "Minimum Working Height of Machine Element above crop or soil";
CM_ SG_ 2362179326 WorkingHeight_Max "Maximum Working Height of Machine Element above crop or soil";
CM_ SG_ 2362179326 WorkingWidth_Set "Setpoint Working Width of Machine Element";
CM_ SG_ 2362179326 WorkingWidth_Act "Actual Working Width of Machine Element";
CM_ SG_ 2362179326 WorkingWidth_Def "Default Working Width of Machine Element";
CM_ SG_ 2362179326 WorkingWidth_Min "Minimum Working Width of Machine Element";
CM_ SG_ 2362179326 WorkingWidth_Max "Maximum Working Width of Machine Element";
CM_ SG_ 2362179326 ContentAsVolume_Set "Setpoint Machine Element Content specified as volume";
CM_ SG_ 2362179326 ContentAsVolume_Act "Actual Machine Element Content specified as volume";
CM_ SG_ 2362179326 ContentAsVolume_Max "Maximum Machine Element Content specified as volume";
CM_ SG_ 2362179326 ContentAsMass_Set "Setpoint Machine Element Content specified as mass";
CM_ SG_ 2362179326 ContentAsMass_Act "Actual Machine Element Content specified as mass";
CM_ SG_ 2362179326 ContentAsMass_Max "Maximum Machine Element Content specified as mass";
CM_ SG_ 2362179326 ContentAsCount_Set "Setpoint Machine Element Content specified as count";
CM_ SG_ 2362179326 ContentAsCount_Act "Actual Machine Element Content specified as count";
CM_ SG_ 2362179326 ContentAsCount_Max "Maximum Machine Element Content specified as count";
CM_ SG_ 2362179326 AccumulatedAppAsVolume "Accumulated Application specified as volume";
CM_ SG_ 2362179326 AccumulatedAppAsMass "Accumulated Application specified as mass";
CM_ SG_ 2362179326 AccumulatedAppAsCount "Accumulated Application specified as count";
CM_ SG_ 2362179326 YieldVolumePerArea "Yield as volume per area";
CM_ SG_ 2362179326 YieldMassPerArea "Yield as mass per area";
CM_ SG_ 2362179326 YieldCountPerArea "Yield as count per area";
CM_ SG_ 2362179326 YieldVolumePerTime "Yield as volume per area";
CM_ SG_ 2362179326 YieldMassPerTime "Yield as mass per area";
CM_ SG_ 2362179326 YieldCountPerTime "Yield as count per area";
CM_ SG_ 2362179326 AccumulatedYieldAsVolume "Accumulated Yield specified as volume";
CM_ SG_ 2362179326 AccumulatedYieldAsMass "Accumulated Yield specified as mass";
CM_ SG_ 2362179326 AccumulatedYieldAsCount "Accumulated Yield specified as count";
CM_ SG_ 2362179326 CropYieldLossVolumePerArea "Crop yield loss as volume per area";
CM_ SG_ 2362179326 CropYieldLossMassPerArea "Crop yield loss as mass per area";
CM_ SG_ 2362179326 CropYieldLossCountPerArea "Crop yield loss as count per area";
CM_ SG_ 2362179326 CropYieldLossVolumePerTime "Crop yield loss as volume per time";
CM_ SG_ 2362179326 CropYieldLossMassPerTime "Crop yield loss as mass per time";
CM_ SG_ 2362179326 CropYieldLossCountPerTime "Crop yield loss as count per time";
CM_ SG_ 2362179326 CropYieldLoss "Crop yield loss";
CM_ SG_ 2362179326 MoistureInCropYield "Moisture in crop yield";
CM_ SG_ 2362179326 DirtMaterialInCropYield "Dirt or foreign material in crop yield";
CM_ SG_ 2362179326 BaleWidth_Set "Setpoint Bale Width for square baler or round baler";
CM_ SG_ 2362179326 BaleWidth_Act "Actual Bale Width for square baler or round baler";
CM_ SG_ 2362179326 BaleWidth_Def "Default Bale Width for square baler or round baler";
CM_ SG_ 2362179326 BaleWidth_Min "Minimum Bale Width for square baler or round baler";
CM_ SG_ 2362179326 BaleWidth_Max "Maximum Bale Width for square baler or round baler";
CM_ SG_ 2362179326 BaleHeight_Set "Setpoint Bale Height is only applicable to square baler";
CM_ SG_ 2362179326 BaleHeight_Act "Actual Bale Height is only applicable to square baler";
CM_ SG_ 2362179326 BaleHeight_Def "Default Bale Height is only applicable to square baler";
CM_ SG_ 2362179326 BaleHeight_Min "Minimum Bale Height is only applicable to square baler";
CM_ SG_ 2362179326 BaleHeight_Max "Maximum Bale Height is only applicable to square baler";
CM_ SG_ 2362179326 BaleSize_Set "Setpoint Bale Size as length for a square baler or diameter for a round baler";
CM_ SG_ 2362179326 BaleSize_Act "Actual Bale Size as length for a square baler or diameter for a round baler";
CM_ SG_ 2362179326 BaleSize_Def "Default Bale Size as length for a square baler or diameter for a round baler";
CM_ SG_ 2362179326 BaleSize_Min "Minimum Bale Size as length for a square baler or diameter for a round baler";
CM_ SG_ 2362179326 BaleSize_Max "Maximum Bale Size as length for a square baler or diameter for a round baler";
CM_ SG_ 2362179326 AccumulatedArea "Accumulated Area";
CM_ SG_ 2362179326 AccumulatedDistanceInWork "Accumulated Distance in working position";
CM_ SG_ 2362179326 AccumulatedDistanceOutWork "Accumulated Distance out of working position";
CM_ SG_ 2362179326 AccumulatedTimeInWork "Accumulated Time in working position";
CM_ SG_ 2362179326 AccumulatedTimeOutWork "Accumulated Time out of working position";
CM_ SG_ 2362179326 PrdoucDensityMassPerArea "Product Density as mass per volume";
CM_ SG_ 2362179326 PrdoucDensityMassPerCount "Product Density as mass per count";
CM_ SG_ 2362179326 PrdoucDensityVolumePerCount "Product Density as volume per count";
CM_ BO_ 2565406462 "Acknowledge";
CM_ BO_ 2147483648 "dummy message for internal use in ISO11783_12.cin";
CM_ BO_ 2566730494 "ECU diagnostic protocol";
CM_ SG_ 2566730494 J1939_73 "J1939-73";
CM_ SG_ 2566730494 ISO14230 "ISO 14230 (KWP 2000 over K line)";
CM_ SG_ 2566730494 ISO15765_3 "ISO 15765-3 (UDS on CAN)";
CM_ SG_ 2566730494 ISO11783Level2 "ISO 11783 Level 2";
CM_ BO_ 2566734590 "ISOBUS compliance certification";
CM_ SG_ 2566734590 CertLaboratoryType_FirstDef "Approving body for the certification laboratory.";
CM_ SG_ 2566734590 MessageRevision "This parameter distinguishes the format of the ISOBUS Compliance Certification message in the second 
edition from the format in the third and later editions.";
CM_ SG_ 2566734590 CertLaboratoryType_SecondDef "Approving body for the certification laboratory.";
CM_ SG_ 2566734590 TestProtocolRevision "ISOBUS compliance certificate revision";
CM_ SG_ 2566734590 TestProtocolPublicationYear "ISOBUS compliance certification year";
CM_ SG_ 2566734590 CertificationLaboratoryID "ISOBUS Compliance certification laboratory ID";
CM_ SG_ 2566734590 CertTypeVTWorkingSetMember "ISOBUS Compliance certification type - VT working set member";
CM_ SG_ 2566734590 CertTypeVTWorkingSetMaster "ISOBUS Compliance certification type - VT working set master";
CM_ SG_ 2566734590 CertTypeVirtualTerminal "ISOBUS Compliance certification type - Virtual terminal";
CM_ SG_ 2566734590 CertTypeClass3ECU "ISOBUS Compliance certification type - Class 3 ECU";
CM_ SG_ 2566734590 CertTypeTECUClass3 "ISOBUS Compliance certification type - TECU Class 3";
CM_ SG_ 2566734590 CertTypeTECUClass2 "ISOBUS Compliance certification type - TECU Class 2";
CM_ SG_ 2566734590 CertTypeTECUClass1 "ISOBUS Compliance certification type - TECU Class 1";
CM_ SG_ 2566734590 CertTypeMinimumECU "ISOBUS Compliance certification type - Minimum ECU";
CM_ SG_ 2566734590 CertTypeGPSReceiver "ISOBUS Compliance certification type - GPS receiver";
CM_ SG_ 2566734590 CertTypeFileServer "ISOBUS Compliance certification type - File server";
CM_ SG_ 2566734590 CertTypeTCWorkingSetMember "ISOBUS Compliance certification type - TC working set member";
CM_ SG_ 2566734590 CertTypeTCWorkingSetMaster "ISOBUS Compliance certification type - TC working set master";
CM_ SG_ 2566734590 CertTypeTaskController "ISOBUS Compliance certification type - Task Controller";
CM_ SG_ 2566734590 CertificationReferenceNumber "ISOBUS Compliance certification reference number";
CM_ BO_ 2566835454 "Diagnostic data clear/reset of previously active DTCs.";
CM_ BO_ 2633895296 "Working Set Master";
CM_ BO_ 2566786854 "Language Command";
CM_ BO_ 2565799462 "Address Claimed";
CM_ BO_ 2565799664 "Address Claimed";
CM_ BO_ 2565799671 "Address Claimed";
CM_ BO_ 2565799552 "Address Claimed";
CM_ BO_ 2565799452 "Address Claimed";
CM_ BO_ 2566835198 "Previously active diagnostic trouble codes";
CM_ SG_ 2566835198 DTC5 "Diagnostic Trouble Code";
CM_ SG_ 2566835198 DTC4 "Diagnostic Trouble Code";
CM_ SG_ 2566835198 DTC3 "Diagnostic Trouble Code";
CM_ SG_ 2566835198 DTC2 "Diagnostic Trouble Code";
CM_ SG_ 2566835198 DTC1 "Diagnostic Trouble Code";
CM_ SG_ 2566835198 MalfunctionIndicatorLampStatus "A lamp used to relay only emissions-related trouble code information.";
CM_ SG_ 2566835198 RedStopLampState "This lamp is uesed to relay trouble code information that is of a severe enought condition that it warrants stopping the vehicle.";
CM_ SG_ 2566835198 AmberWarningLampStatus "This lamp is used to relay trouble code information that is reporting a problem with the vehicle system but the vehicle need
not be immediately stopped.";
CM_ SG_ 2566835198 ProtectLampStatus "This lamp is used to relay trouble code informatio that is reporting a problem with a vehicle system that is most
probably not electronic subsystem related.";
CM_ SG_ 2566835198 FlashRedStopLamp "This parameter provides the capability to flash the RSL (SPN 3039).";
CM_ SG_ 2566835198 FlashProtectLamp "This parameter provides the capability to flash the engine protect lamp (SPN 3041).";
CM_ SG_ 2566835198 FlashMalfuncIndicatorLamp "This parameter provides the capability to flash the MIL (SPN 3038).";
CM_ SG_ 2566835198 FlashAmberWarningLamp "This parameter provides the capability to flash the AWL (SPN 3040). ";
CM_ BO_ 2566834942 "Active diagnostic trouble codes";
CM_ SG_ 2566834942 DTC5 "Diagnostic Trouble Code";
CM_ SG_ 2566834942 DTC4 "Diagnostic Trouble Code";
CM_ SG_ 2566834942 DTC3 "Diagnostic Trouble Code";
CM_ SG_ 2566834942 DTC2 "Diagnostic Trouble Code";
CM_ SG_ 2566834942 DTC1 "Diagnostic Trouble Code";
CM_ SG_ 2566834942 FlashRedStopLamp "This parameter provides the capability to flash the RSL (SPN 3039).";
CM_ SG_ 2566834942 FlashProtectLamp "This parameter provides the capability to flash the engine protect lamp (SPN 3041).";
CM_ SG_ 2566834942 FlashMalfuncIndicatorLamp "This parameter provides the capability to flash the MIL (SPN 3038).";
CM_ SG_ 2566834942 FlashAmberWarningLamp "This parameter provides the capability to flash the AWL (SPN 3040). ";
CM_ SG_ 2566834942 MalfunctionIndicatorLampStatus "A lamp used to relay only emissions-related trouble code information.";
CM_ SG_ 2566834942 AmberWarningLampStatus "This lamp is used to relay trouble code information that is reporting a problem with the vehicle system but the vehicle need
not be immediately stopped.";
CM_ SG_ 2566834942 RedStopLampState "This lamp is uesed to relay trouble code information that is of a severe enought condition that it warrants stopping the vehicle.";
CM_ SG_ 2566834942 ProtectLampStatus "This lamp is used to relay trouble code informatio that is reporting a problem with a vehicle system that is most
probably not electronic subsystem related.";
CM_ BO_ 2566839038 "Software Identification";
CM_ SG_ 2566839038 SoftwareID3 "Software ID";
CM_ SG_ 2566839038 SoftwareID2 "Software ID";
CM_ SG_ 2566839038 SoftwareID1 "Software ID";
CM_ SG_ 2566839038 NmbrOfSftwrIdentificationFields "Number of software identification designators represented in the software identification parameter group.";
CM_ BO_ 2566768126 "ECU Identification Information";
CM_ BO_ 2566838526 "Commanded Address";
CM_ SG_ 2566838526 AddressAssignment "The source address that is to be assigned to the CA that has the NAME corresponding to the one conveyed in the first eight bytes of this Commanded Address message.";
CM_ BO_ 2565799678 "Address Claimed";
BA_DEF_ SG_  "GenSigStartValue" INT -2147483648 2147483647;
BA_DEF_ SG_  "GenSigSendType" ENUM  "Cyclic","OnWrite","OnWriteWithRepetition","OnChange","OnChangeWithRepetition","IfActive","IfActiveWithRepetition","NoSigSendType";
BA_DEF_ SG_  "SigType" ENUM  "Default","Range","RangeSigned","ASCII","Discrete","Control","ReferencePGN","DTC","StringDelimiter","StringLength","StringLengthControl";
BA_DEF_ SG_  "SPN" INT 0 524287;
BA_DEF_ BO_  "GenMsgRequestable" INT 0 1;
BA_DEF_ BO_  "GenMsgCycleTime" INT 0 3600000;
BA_DEF_ BO_  "GenMsgSendType" ENUM  "cyclic","reserved","cyclicIfActive","reserved","reserved","reserved","reserved","reserved","noMsgSendType","vector_leerstring";
BA_DEF_ BO_  "VFrameFormat" ENUM  "StandardCAN","ExtendedCAN","reserved","J1939PG","vector_leerstring";
BA_DEF_ BO_  "SingleFrame" INT 0 1;
BA_DEF_ SG_  "DDI" INT 0 65535;
BA_DEF_ SG_  "SystemSignalLongSymbol" STRING ;
BA_DEF_DEF_  "GenSigStartValue" 0;
BA_DEF_DEF_  "GenSigSendType" "NoSigSendType";
BA_DEF_DEF_  "SigType" "Default";
BA_DEF_DEF_  "SPN" 0;
BA_DEF_DEF_  "GenMsgRequestable" 1;
BA_DEF_DEF_  "GenMsgCycleTime" 0;
BA_DEF_DEF_  "GenMsgSendType" "noMsgSendType";
BA_DEF_DEF_  "VFrameFormat" "J1939PG";
BA_DEF_DEF_  "SingleFrame" 1;
BA_DEF_DEF_  "DDI" 0;
BA_DEF_DEF_  "SystemSignalLongSymbol" "";
BA_ "GenMsgCycleTime" BO_ 2566786854 100;
BA_ "SigType" SG_ 2362179326 ObjectIdOfFaultyObject 1;
BA_ "SigType" SG_ 2362179326 ParentObjectIdOfFaultyObject 1;
BA_ "SigType" SG_ 2362179326 TemperatureUnits 4;
BA_ "SigType" SG_ 2362179326 PressureUnits 4;
BA_ "SigType" SG_ 2362179326 ForceUnits 4;
BA_ "SigType" SG_ 2362179326 UnitsSystem 4;
BA_ "SigType" SG_ 2362179326 DistanceUnitCmd 4;
BA_ "SPN" SG_ 2362179326 DistanceUnitCmd 2414;
BA_ "SigType" SG_ 2362179326 AreaUnitCmd 4;
BA_ "SPN" SG_ 2362179326 AreaUnitCmd 2415;
BA_ "SigType" SG_ 2362179326 VolumeUnitCmd 4;
BA_ "SPN" SG_ 2362179326 VolumeUnitCmd 2416;
BA_ "SigType" SG_ 2362179326 MassUnitCmd 4;
BA_ "SPN" SG_ 2362179326 MassUnitCmd 2417;
BA_ "SigType" SG_ 2362179326 DateFormatCmd 1;
BA_ "SPN" SG_ 2362179326 DateFormatCmd 2412;
BA_ "SigType" SG_ 2362179326 DecimalSymbolCmd 4;
BA_ "SPN" SG_ 2362179326 DecimalSymbolCmd 2411;
BA_ "SigType" SG_ 2362179326 TimeFormatCmd 4;
BA_ "SPN" SG_ 2362179326 TimeFormatCmd 2413;
BA_ "SigType" SG_ 2362179326 LanguageCodeCmd 3;
BA_ "SPN" SG_ 2362179326 LanguageCodeCmd 2410;
BA_ "DDI" SG_ 2362179326 MinMassPerAreaAppRate 152;
BA_ "DDI" SG_ 2362179326 RequestDefaultProcessData 57343;
BA_ "DDI" SG_ 2362179326 AreaPerTimeCapacity 151;
BA_ "DDI" SG_ 2362179326 FuelConsumptionPerArea 150;
BA_ "DDI" SG_ 2362179326 FuelConsumptionPerTime 149;
BA_ "DDI" SG_ 2362179326 TotalFuelConsumption 148;
BA_ "DDI" SG_ 2362179326 LogCount 147;
BA_ "DDI" SG_ 2362179326 PitchAngle 146;
BA_ "DDI" SG_ 2362179326 RollAngle 145;
BA_ "DDI" SG_ 2362179326 YawAngle 144;
BA_ "DDI" SG_ 2362179326 ActualValueTimeLatency 143;
BA_ "DDI" SG_ 2362179326 SetpointTimeLatency 142;
BA_ "DDI" SG_ 2362179326 WorkState 141;
BA_ "DDI" SG_ 2362179326 PercentageAppRateSetpoint 140;
BA_ "DDI" SG_ 2362179326 DeviceCountCapacity 139;
BA_ "DDI" SG_ 2362179326 DeviceMassCapacity 138;
BA_ "DDI" SG_ 2362179326 DeviceVolumeCapacity 137;
BA_ "DDI" SG_ 2362179326 DeviceElementOffsetZ 136;
BA_ "DDI" SG_ 2362179326 DeviceElementOffsetY 135;
BA_ "DDI" SG_ 2362179326 DeviceElementOffsetX 134;
BA_ "DDI" SG_ 2362179326 AuxiliaryValveInvertPorts 133;
BA_ "DDI" SG_ 2362179326 AuxiliaryValveProgressivRetract 132;
BA_ "DDI" SG_ 2362179326 AuxiliaryValveProgressivExtend 131;
BA_ "DDI" SG_ 2362179326 AuxiliaryValveFloatThreshold 130;
BA_ "DDI" SG_ 2362179326 AuxiliaryValveRampRetractDown 129;
BA_ "DDI" SG_ 2362179326 AuxiliaryValveRampRetractUp 128;
BA_ "DDI" SG_ 2362179326 AuxiliaryValveRampExtendDown 127;
BA_ "DDI" SG_ 2362179326 AuxiliaryValveScalingRetract 125;
BA_ "DDI" SG_ 2362179326 AuxiliaryValveScalingExtend 124;
BA_ "DDI" SG_ 2362179326 AuxiliaryRampExtendUp 126;
BA_ "DDI" SG_ 2362179326 AppRateVolumePerArea_Set 1;
BA_ "DDI" SG_ 2362179326 AppRateVolumePerArea_Act 2;
BA_ "DDI" SG_ 2362179326 AppRateVolumePerArea_Def 3;
BA_ "DDI" SG_ 2362179326 AppRateVolumePerArea_Min 4;
BA_ "DDI" SG_ 2362179326 AppRateVolumePerArea_Max 5;
BA_ "DDI" SG_ 2362179326 AppRateMassPerArea_Set 6;
BA_ "DDI" SG_ 2362179326 AppRateMassPerArea_Act 7;
BA_ "DDI" SG_ 2362179326 AppRateMassPerArea_Def 8;
BA_ "DDI" SG_ 2362179326 AppRateMassPerArea_Min 9;
BA_ "DDI" SG_ 2362179326 AppRateMassPerArea_Max 10;
BA_ "DDI" SG_ 2362179326 AppRateCountPerArea_Set 11;
BA_ "DDI" SG_ 2362179326 AppRateCountPerArea_Act 12;
BA_ "DDI" SG_ 2362179326 AppRateCountPerArea_Def 13;
BA_ "DDI" SG_ 2362179326 AppRateCountPerArea_Min 14;
BA_ "DDI" SG_ 2362179326 AppRateCountPerArea_Max 15;
BA_ "DDI" SG_ 2362179326 SetAppRateDistance_Set 16;
BA_ "DDI" SG_ 2362179326 AppRateDistance_Act 17;
BA_ "DDI" SG_ 2362179326 AppRateDistance_Def 18;
BA_ "DDI" SG_ 2362179326 AppRateDistance_Min 19;
BA_ "DDI" SG_ 2362179326 AppRateDistance_Max 20;
BA_ "DDI" SG_ 2362179326 AppRateVolumePerVolume_Set 21;
BA_ "DDI" SG_ 2362179326 AppRateVolumePerVolume_Act 22;
BA_ "DDI" SG_ 2362179326 AppRateVolumePerVolume_Def 23;
BA_ "DDI" SG_ 2362179326 AppRateVolumePerVolume_Min 24;
BA_ "DDI" SG_ 2362179326 AppRateVolumePerVolume_Max 25;
BA_ "DDI" SG_ 2362179326 AppRateMassPerMass_Set 26;
BA_ "DDI" SG_ 2362179326 AppRateMassPerMass_Act 27;
BA_ "DDI" SG_ 2362179326 AppRateMassPerMass_Def 28;
BA_ "DDI" SG_ 2362179326 AppRateMassPerMass_Min 29;
BA_ "DDI" SG_ 2362179326 AppRateMassPerMass_Max 30;
BA_ "DDI" SG_ 2362179326 AppRateVolumePerMass_Set 31;
BA_ "DDI" SG_ 2362179326 AppRateVolumePerMass_Act 32;
BA_ "DDI" SG_ 2362179326 AppRateVolumePerMass_Def 33;
BA_ "DDI" SG_ 2362179326 AppRateVolumePerMass_Min 34;
BA_ "DDI" SG_ 2362179326 AppRateVolumePerMass_Max 35;
BA_ "DDI" SG_ 2362179326 AppRateVolumePerTime_Set 36;
BA_ "DDI" SG_ 2362179326 AppRateVolumePerTime_Act 37;
BA_ "DDI" SG_ 2362179326 AppRateVolumePerTime_Def 38;
BA_ "DDI" SG_ 2362179326 AppRateVolumePerTime_Min 39;
BA_ "DDI" SG_ 2362179326 AppRateVolumePerTime_Max 40;
BA_ "DDI" SG_ 2362179326 AppRateMassPerTime_Set 41;
BA_ "DDI" SG_ 2362179326 AppRateMassPerTime_Act 42;
BA_ "DDI" SG_ 2362179326 AppRateMassPerTime_Def 43;
BA_ "DDI" SG_ 2362179326 AppRateMassPerTime_Min 44;
BA_ "DDI" SG_ 2362179326 AppRateMassPerTime_Max 45;
BA_ "DDI" SG_ 2362179326 AppRateCountPerTime_Set 46;
BA_ "DDI" SG_ 2362179326 AppRateCountPerTime_Act 47;
BA_ "DDI" SG_ 2362179326 AppRateCountPerTime_Def 48;
BA_ "DDI" SG_ 2362179326 AppRateCountPerTime_Min 49;
BA_ "DDI" SG_ 2362179326 AppRateCountPerTime_Max 50;
BA_ "DDI" SG_ 2362179326 SetTillageDepth_Set 51;
BA_ "DDI" SG_ 2362179326 TillageDepth_Act 52;
BA_ "DDI" SG_ 2362179326 TillageDepth_Def 53;
BA_ "DDI" SG_ 2362179326 TillageDepth_Min 54;
BA_ "DDI" SG_ 2362179326 TillageDepth_Max 55;
BA_ "DDI" SG_ 2362179326 SeedingDeph_Set 56;
BA_ "DDI" SG_ 2362179326 SeedingDeph_Act 57;
BA_ "DDI" SG_ 2362179326 SeedingDeph_Def 58;
BA_ "DDI" SG_ 2362179326 SeedingDeph_Min 59;
BA_ "DDI" SG_ 2362179326 SeedingDeph_Max 60;
BA_ "DDI" SG_ 2362179326 WorkingHeight_Set 61;
BA_ "DDI" SG_ 2362179326 WorkingHeight_Act 62;
BA_ "DDI" SG_ 2362179326 WorkingHeight_Def 63;
BA_ "DDI" SG_ 2362179326 WorkingHeight_Min 64;
BA_ "DDI" SG_ 2362179326 WorkingHeight_Max 65;
BA_ "DDI" SG_ 2362179326 WorkingWidth_Set 66;
BA_ "DDI" SG_ 2362179326 WorkingWidth_Act 67;
BA_ "DDI" SG_ 2362179326 WorkingWidth_Def 68;
BA_ "DDI" SG_ 2362179326 WorkingWidth_Min 69;
BA_ "DDI" SG_ 2362179326 WorkingWidth_Max 70;
BA_ "DDI" SG_ 2362179326 ContentAsVolume_Set 71;
BA_ "DDI" SG_ 2362179326 ContentAsVolume_Act 72;
BA_ "DDI" SG_ 2362179326 ContentAsVolume_Max 73;
BA_ "DDI" SG_ 2362179326 ContentAsMass_Set 74;
BA_ "DDI" SG_ 2362179326 ContentAsMass_Act 75;
BA_ "DDI" SG_ 2362179326 ContentAsMass_Max 76;
BA_ "DDI" SG_ 2362179326 ContentAsCount_Set 77;
BA_ "DDI" SG_ 2362179326 ContentAsCount_Act 78;
BA_ "DDI" SG_ 2362179326 ContentAsCount_Max 79;
BA_ "DDI" SG_ 2362179326 AccumulatedAppAsVolume 80;
BA_ "DDI" SG_ 2362179326 AccumulatedAppAsMass 81;
BA_ "DDI" SG_ 2362179326 AccumulatedAppAsCount 82;
BA_ "DDI" SG_ 2362179326 YieldVolumePerArea 83;
BA_ "DDI" SG_ 2362179326 YieldMassPerArea 84;
BA_ "DDI" SG_ 2362179326 YieldCountPerArea 85;
BA_ "DDI" SG_ 2362179326 YieldVolumePerTime 86;
BA_ "DDI" SG_ 2362179326 YieldMassPerTime 87;
BA_ "DDI" SG_ 2362179326 YieldCountPerTime 88;
BA_ "DDI" SG_ 2362179326 AccumulatedYieldAsVolume 89;
BA_ "DDI" SG_ 2362179326 AccumulatedYieldAsMass 90;
BA_ "DDI" SG_ 2362179326 AccumulatedYieldAsCount 91;
BA_ "DDI" SG_ 2362179326 CropYieldLossVolumePerArea 92;
BA_ "DDI" SG_ 2362179326 CropYieldLossMassPerArea 93;
BA_ "DDI" SG_ 2362179326 CropYieldLossCountPerArea 94;
BA_ "DDI" SG_ 2362179326 CropYieldLossVolumePerTime 95;
BA_ "DDI" SG_ 2362179326 CropYieldLossMassPerTime 96;
BA_ "DDI" SG_ 2362179326 CropYieldLossCountPerTime 97;
BA_ "DDI" SG_ 2362179326 CropYieldLoss 98;
BA_ "DDI" SG_ 2362179326 MoistureInCropYield 99;
BA_ "DDI" SG_ 2362179326 DirtMaterialInCropYield 100;
BA_ "DDI" SG_ 2362179326 BaleWidth_Set 101;
BA_ "DDI" SG_ 2362179326 BaleWidth_Act 102;
BA_ "DDI" SG_ 2362179326 BaleWidth_Def 103;
BA_ "DDI" SG_ 2362179326 BaleWidth_Min 104;
BA_ "DDI" SG_ 2362179326 BaleWidth_Max 105;
BA_ "DDI" SG_ 2362179326 BaleHeight_Set 106;
BA_ "DDI" SG_ 2362179326 BaleHeight_Act 107;
BA_ "DDI" SG_ 2362179326 BaleHeight_Def 108;
BA_ "DDI" SG_ 2362179326 BaleHeight_Min 109;
BA_ "DDI" SG_ 2362179326 BaleHeight_Max 110;
BA_ "DDI" SG_ 2362179326 BaleSize_Set 111;
BA_ "DDI" SG_ 2362179326 BaleSize_Act 112;
BA_ "DDI" SG_ 2362179326 BaleSize_Def 113;
BA_ "DDI" SG_ 2362179326 BaleSize_Min 114;
BA_ "DDI" SG_ 2362179326 BaleSize_Max 115;
BA_ "DDI" SG_ 2362179326 AccumulatedArea 116;
BA_ "DDI" SG_ 2362179326 AccumulatedDistanceInWork 117;
BA_ "DDI" SG_ 2362179326 AccumulatedDistanceOutWork 118;
BA_ "DDI" SG_ 2362179326 AccumulatedTimeInWork 119;
BA_ "DDI" SG_ 2362179326 AccumulatedTimeOutWork 120;
BA_ "DDI" SG_ 2362179326 PrdoucDensityMassPerArea 121;
BA_ "DDI" SG_ 2362179326 PrdoucDensityMassPerCount 122;
BA_ "DDI" SG_ 2362179326 PrdoucDensityVolumePerCount 123;
BA_ "SPN" SG_ 2565406462 ParameterGroupNumber 2574;
BA_ "SigType" SG_ 2565406462 ParameterGroupNumber 6;
BA_ "SPN" SG_ 2565406462 GroupFunctionValue 2542;
BA_ "SPN" SG_ 2565406462 ControlByte 2541;
BA_ "SPN" SG_ 2566734590 CertLaboratoryType_FirstDef 4315;
BA_ "SPN" SG_ 2566734590 MessageRevision 7446;
BA_ "SPN" SG_ 2566734590 CertLaboratoryType_SecondDef 4315;
BA_ "SPN" SG_ 2566734590 TestProtocolRevision 4314;
BA_ "SPN" SG_ 2566734590 TestProtocolPublicationYear 4313;
BA_ "SPN" SG_ 2566734590 CertificationLaboratoryID 4316;
BA_ "SPN" SG_ 2566734590 CertTypeVTWorkingSetMember 4324;
BA_ "SPN" SG_ 2566734590 CertTypeVTWorkingSetMaster 4323;
BA_ "SPN" SG_ 2566734590 CertTypeVirtualTerminal 4322;
BA_ "SPN" SG_ 2566734590 CertTypeClass3ECU 4321;
BA_ "SPN" SG_ 2566734590 CertTypeTECUClass3 4320;
BA_ "SPN" SG_ 2566734590 CertTypeTECUClass2 4319;
BA_ "SPN" SG_ 2566734590 CertTypeTECUClass1 4318;
BA_ "SPN" SG_ 2566734590 CertTypeMinimumECU 4317;
BA_ "SPN" SG_ 2566734590 CertTypeGPSReceiver 4329;
BA_ "SPN" SG_ 2566734590 CertTypeFileServer 4328;
BA_ "SPN" SG_ 2566734590 CertTypeTCWorkingSetMember 4327;
BA_ "SPN" SG_ 2566734590 CertTypeTCWorkingSetMaster 4326;
BA_ "SPN" SG_ 2566734590 CertTypeTaskController 4325;
BA_ "SPN" SG_ 2566734590 CertificationReferenceNumber 4330;
BA_ "GenSigStartValue" SG_ 2633895296 NumberOfMembersInWorkingSet 1;
BA_ "SigType" SG_ 2633895296 NumberOfMembersInWorkingSet 1;
BA_ "SPN" SG_ 2566786854 LanguageCodeCmd 2410;
BA_ "SigType" SG_ 2566786854 LanguageCodeCmd 3;
BA_ "SigType" SG_ 2566786854 TimeFormatCmd 4;
BA_ "SigType" SG_ 2566786854 DecimalSymbolCmd 4;
BA_ "SigType" SG_ 2566786854 DateFormatCmd 1;
BA_ "SigType" SG_ 2566786854 MassUnitCmd 4;
BA_ "SigType" SG_ 2566786854 VolumeUnitCmd 4;
BA_ "SigType" SG_ 2566786854 AreaUnitCmd 4;
BA_ "SigType" SG_ 2566786854 DistanceUnitCmd 4;
BA_ "SigType" SG_ 2566786854 UnitsSystem 4;
BA_ "SigType" SG_ 2566786854 ForceUnits 4;
BA_ "SigType" SG_ 2566786854 PressureUnits 4;
BA_ "SigType" SG_ 2566786854 TemperatureUnits 4;
BA_ "SigType" SG_ 2565799462 IndustryGroup 4;
BA_ "SigType" SG_ 2565799462 Function 1;
BA_ "SigType" SG_ 2565799462 FunctionInstance 1;
BA_ "SigType" SG_ 2565799462 ECUInstance 4;
BA_ "SigType" SG_ 2565799462 ManufacturerCode 1;
BA_ "SigType" SG_ 2565799462 IdentityNumber 1;
BA_ "SigType" SG_ 2565799664 IndustryGroup 4;
BA_ "SigType" SG_ 2565799664 Function 1;
BA_ "SigType" SG_ 2565799664 FunctionInstance 1;
BA_ "SigType" SG_ 2565799664 ECUInstance 4;
BA_ "SigType" SG_ 2565799664 ManufacturerCode 1;
BA_ "SigType" SG_ 2565799664 IdentityNumber 1;
BA_ "SigType" SG_ 2565799671 IndustryGroup 4;
BA_ "SigType" SG_ 2565799671 Function 1;
BA_ "SigType" SG_ 2565799671 FunctionInstance 1;
BA_ "SigType" SG_ 2565799671 ECUInstance 4;
BA_ "SigType" SG_ 2565799671 ManufacturerCode 1;
BA_ "SigType" SG_ 2565799671 IdentityNumber 1;
BA_ "SigType" SG_ 2565799552 IndustryGroup 4;
BA_ "SigType" SG_ 2565799552 Function 1;
BA_ "SigType" SG_ 2565799552 FunctionInstance 1;
BA_ "SigType" SG_ 2565799552 ECUInstance 4;
BA_ "SigType" SG_ 2565799552 ManufacturerCode 1;
BA_ "SigType" SG_ 2565799552 IdentityNumber 1;
BA_ "SigType" SG_ 2565799452 IndustryGroup 4;
BA_ "SigType" SG_ 2565799452 Function 1;
BA_ "SigType" SG_ 2565799452 FunctionInstance 1;
BA_ "SigType" SG_ 2565799452 ECUInstance 4;
BA_ "SigType" SG_ 2565799452 ManufacturerCode 1;
BA_ "SigType" SG_ 2565799452 IdentityNumber 1;
BA_ "SigType" SG_ 2566835198 DTC5 7;
BA_ "SigType" SG_ 2566835198 DTC4 7;
BA_ "SigType" SG_ 2566835198 DTC3 7;
BA_ "SigType" SG_ 2566835198 DTC2 7;
BA_ "SigType" SG_ 2566835198 DTC1 7;
BA_ "SPN" SG_ 2566835198 MalfunctionIndicatorLampStatus 1213;
BA_ "SigType" SG_ 2566835198 MalfunctionIndicatorLampStatus 4;
BA_ "SPN" SG_ 2566835198 RedStopLampState 623;
BA_ "SigType" SG_ 2566835198 RedStopLampState 4;
BA_ "SPN" SG_ 2566835198 AmberWarningLampStatus 624;
BA_ "SigType" SG_ 2566835198 AmberWarningLampStatus 4;
BA_ "SPN" SG_ 2566835198 ProtectLampStatus 987;
BA_ "SigType" SG_ 2566835198 ProtectLampStatus 4;
BA_ "SPN" SG_ 2566835198 FlashRedStopLamp 3039;
BA_ "SPN" SG_ 2566835198 FlashProtectLamp 3041;
BA_ "SPN" SG_ 2566835198 FlashMalfuncIndicatorLamp 3038;
BA_ "SigType" SG_ 2566835198 FlashMalfuncIndicatorLamp 4;
BA_ "SPN" SG_ 2566835198 FlashAmberWarningLamp 3040;
BA_ "SigType" SG_ 2566834942 DTC5 7;
BA_ "SigType" SG_ 2566834942 DTC4 7;
BA_ "SigType" SG_ 2566834942 DTC3 7;
BA_ "SigType" SG_ 2566834942 DTC2 7;
BA_ "SigType" SG_ 2566834942 DTC1 7;
BA_ "SPN" SG_ 2566834942 FlashRedStopLamp 3039;
BA_ "SPN" SG_ 2566834942 FlashProtectLamp 3041;
BA_ "SPN" SG_ 2566834942 FlashMalfuncIndicatorLamp 3038;
BA_ "SigType" SG_ 2566834942 FlashMalfuncIndicatorLamp 4;
BA_ "SPN" SG_ 2566834942 FlashAmberWarningLamp 3040;
BA_ "SPN" SG_ 2566834942 MalfunctionIndicatorLampStatus 1213;
BA_ "SigType" SG_ 2566834942 MalfunctionIndicatorLampStatus 4;
BA_ "SPN" SG_ 2566834942 AmberWarningLampStatus 624;
BA_ "SigType" SG_ 2566834942 AmberWarningLampStatus 4;
BA_ "SPN" SG_ 2566834942 RedStopLampState 623;
BA_ "SigType" SG_ 2566834942 RedStopLampState 4;
BA_ "SPN" SG_ 2566834942 ProtectLampStatus 987;
BA_ "SigType" SG_ 2566834942 ProtectLampStatus 4;
BA_ "SPN" SG_ 2566839038 SoftwareID3 234;
BA_ "SigType" SG_ 2566839038 SoftwareID3 8;
BA_ "SPN" SG_ 2566839038 SoftwareID2 234;
BA_ "SigType" SG_ 2566839038 SoftwareID2 8;
BA_ "SPN" SG_ 2566839038 SoftwareID1 234;
BA_ "SigType" SG_ 2566839038 SoftwareID1 8;
BA_ "SPN" SG_ 2566839038 NmbrOfSftwrIdentificationFields 965;
BA_ "SigType" SG_ 2566839038 NmbrOfSftwrIdentificationFields 1;
BA_ "SigType" SG_ 2566768126 ECUHardwareID 8;
BA_ "SPN" SG_ 2566768126 ECUManufacturerName 4304;
BA_ "SigType" SG_ 2566768126 ECUManufacturerName 8;
BA_ "SPN" SG_ 2566768126 ECUType 2904;
BA_ "SigType" SG_ 2566768126 ECUType 8;
BA_ "SPN" SG_ 2566768126 ECULocation 2903;
BA_ "SigType" SG_ 2566768126 ECULocation 8;
BA_ "SPN" SG_ 2566768126 ECUSerialNumber 2902;
BA_ "SigType" SG_ 2566768126 ECUSerialNumber 8;
BA_ "SPN" SG_ 2566768126 ECUPartNumber 2901;
BA_ "SigType" SG_ 2566768126 ECUPartNumber 8;
BA_ "SPN" SG_ 2566838526 AddressAssignment 2847;
BA_ "SigType" SG_ 2566838526 AddressAssignment 1;
BA_ "SigType" SG_ 2566838526 Function 1;
BA_ "SigType" SG_ 2566838526 ManufacturerCode 1;
BA_ "SigType" SG_ 2566838526 IdentityNumber 1;
BA_ "SigType" SG_ 2565799678 Function 1;
BA_ "SigType" SG_ 2565799678 ManufacturerCode 1;
BA_ "SigType" SG_ 2565799678 IdentityNumber 1;
VAL_ 2362179326 ErrorCodeProcessData6 0 "NoError" 1 "InvalidIntervalOrThreshold" ;
VAL_ 2362179326 ErrorCodeProcessData5 0 "NoError" 1 "ProcessDataNotSetable" ;
VAL_ 2362179326 ErrorCodeProcessData4 0 "NoError" 1 "TriggerMethodNotSupported" ;
VAL_ 2362179326 ErrorCodeProcessData3 0 "NoError" 1 "DDINotSupportedByElement" ;
VAL_ 2362179326 ErrorCodeProcessData2 0 "NoError" 1 "InvalidElementNumber" ;
VAL_ 2362179326 ErrorCodeProcessData1 0 "NoError" 1 "CommandNotSupported" ;
VAL_ 2362179326 ErrorCodeChangeDesignator 1 "Error" 0 "Success" ;
VAL_ 2362179326 ErrorCodeObjectPoolDelete 1 "Error" 0 "Success" ;
VAL_ 2362179326 ErrorCodeObjPool4 1 "ObjectPoolWasDeleted" 0 "NoError" ;
VAL_ 2362179326 ErrorCodeObjPool3 1 "GeneralError" 0 "NoError" ;
VAL_ 2362179326 ErrorCodeObjPool2 1 "UnknownObjectReference" 0 "NoError" ;
VAL_ 2362179326 ErrorCodeObjPool1 1 "MethodOrAttributeNotSupported" 0 "NoError" ;
VAL_ 2362179326 ErrorCodeObjPoolActiveResp3 1 "GeneralError" 0 "NoError" ;
VAL_ 2362179326 ErrorCodeObjPoolActiveResp2 1 "TaskControllerRanOutOfMemory" 0 "NoError" ;
VAL_ 2362179326 ErrorCodeObjPoolActiveResp1 1 "ErrorsInTheObjectPool" 0 "NoError" ;
VAL_ 2362179326 ErrorCodeObjPoolTransfer 2 "GeneralError" 1 "TaskControllerRanOutOfMemory" 0 "NoError" ;
VAL_ 2362179326 Status 1 "NotEnoughMemoryAvailable" 0 "EnoughMemoryAvailable" ;
VAL_ 2362179326 TemperatureUnits 0 "Metric" 1 "Imperial" 2 "Reserved" 3 "NoAction" ;
VAL_ 2362179326 PressureUnits 0 "Metric" 1 "Imperial" 2 "Reserved" 3 "NoAction" ;
VAL_ 2362179326 ForceUnits 0 "Metric" 1 "Imperial" 2 "Reserved" 3 "NoAction" ;
VAL_ 2362179326 UnitsSystem 0 "Metric" 1 "Imperial" 2 "US" 3 "NoAction" ;
VAL_ 2362179326 DistanceUnitCmd 0 "Metric" 1 "Imperial" 3 "NoAction" ;
VAL_ 2362179326 AreaUnitCmd 0 "Metric" 1 "Imperial" 3 "NoAction" ;
VAL_ 2362179326 VolumeUnitCmd 0 "Metric" 1 "Imperial" 2 "US" 3 "NoAction" ;
VAL_ 2362179326 MassUnitCmd 0 "Metric" 1 "Imperial" 2 "TonsPounds" 3 "NoAction" ;
VAL_ 2362179326 DateFormatCmd 0 "ddmmyyyy" 1 "ddyyyymm" 2 "mmyyyydd" 3 "mmddyyyy" 4 "yyyymmdd" 5 "yyyyddmm" ;
VAL_ 2362179326 DecimalSymbolCmd 0 "CommaIsUsed" 1 "PointIsUsed" 3 "NoAction" ;
VAL_ 2362179326 TimeFormatCmd 0 "Hour24" 1 "Hour12" 3 "NoAction" ;
VAL_ 2362179326 DeviceDescriptionMsgType 13 "ChangeDesignatorResponse" 12 "ChangeDesignator" 11 "ObjectPoolDeleteResponse" 10 "ObjectPoolDelete" 9 "ObjectPoolActivateResponse" 8 "ObjectPoolActivate" 7 "ObjectPoolTransferResponse" 6 "ObjectPoolTransfer" 5 "RequestObjectPoolTransferResp" 4 "RequestObjectPoolTransfer" 3 "LocalizationLabel" 2 "RequestLocalizationLabel" 1 "StructureLabel" 0 "RequestStructureLabel" ;
VAL_ 2362179326 TechnicalDataMsgType 1 "ParameterVersion" 0 "ParameterRequestVersion" ;
VAL_ 2362179326 Command 0 "TechnicalData" 1 "DeviceDescription" 2 "RequestValue" 3 "ValueCommand" 4 "TimeInterval" 5 "DistanceInterval" 6 "MinWithinThreshold" 7 "MaxWithinThreshold" 8 "ChangeThreshold" 13 "PDNACK" 14 "TaskControllerStatus" 15 "WorkingSetTask" ;
VAL_ 2565406462 ControlByte 3 "CannotRespond" 2 "AccessDenied" 1 "NACK" 0 "ACK" ;
VAL_ 2566734590 CertLaboratoryType_FirstDef 7 "Not available (not certified) " 0 "Non-certified laboratory/self-test" 1 "AEF certified laboratory " 2 "Reserved " ;
VAL_ 2566734590 MessageRevision 1 "Third and later edition message revision" 0 "Format of message in second edition." ;
VAL_ 2566734590 CertLaboratoryType_SecondDef 3 "Not available (not certified) " 0 "Non-certified Laboratory/self-certification" 1 "AEF certified laboratory " 2 "Reserved " ;
VAL_ 2566734590 TestProtocolRevision 0 "FirstRevision" 1 "SecondRevision" 2 "ThirdRevision" 3 "NotAvailable" ;
VAL_ 2566734590 CertTypeVTWorkingSetMember 0 "NotCertified" 1 "CertificationTestPerformed" ;
VAL_ 2566734590 CertTypeVTWorkingSetMaster 0 "NotCertified" 1 "CertificationTestPerformed" ;
VAL_ 2566734590 CertTypeVirtualTerminal 0 "NotCertified" 1 "CertificationTestPerformed" ;
VAL_ 2566734590 CertTypeClass3ECU 0 "NotCertified" 1 "CertificationTestPerformed" ;
VAL_ 2566734590 CertTypeTECUClass3 0 "NotCertified" 1 "CertificationTestPerformed" ;
VAL_ 2566734590 CertTypeTECUClass2 0 "NotCertified" 1 "CertificationTestPerformed" ;
VAL_ 2566734590 CertTypeTECUClass1 0 "NotCertified" 1 "CertificationTestPerformed" ;
VAL_ 2566734590 CertTypeMinimumECU 0 "NotCertified" 1 "CertificationTestPerformed" ;
VAL_ 2566734590 CertTypeGPSReceiver 0 "NotCertified" 1 "CertificationTestPerformed" ;
VAL_ 2566734590 CertTypeFileServer 0 "NotCertified" 1 "CertificationTestPerformed" ;
VAL_ 2566734590 CertTypeTCWorkingSetMember 0 "NotCertified" 1 "CertificationTestPerformed" ;
VAL_ 2566734590 CertTypeTCWorkingSetMaster 0 "NotCertified" 1 "CertificationTestPerformed" ;
VAL_ 2566734590 CertTypeTaskController 0 "NotCertified" 1 "CertificationTestPerformed" ;
VAL_ 2566734590 CertificationReferenceNumber 0 "NotCertified" 1 "CertificationTestPerformed" ;
VAL_ 2566786854 TimeFormatCmd 0 "Hour24" 1 "Hour12" 3 "NoAction" ;
VAL_ 2566786854 DecimalSymbolCmd 0 "CommaIsUsed" 1 "PointIsUsed" 3 "NoAction" ;
VAL_ 2566786854 DateFormatCmd 0 "ddmmyyyy" 1 "ddyyyymm" 2 "mmyyyydd" 3 "mmddyyyy" 4 "yyyymmdd" 5 "yyyyddmm" ;
VAL_ 2566786854 MassUnitCmd 0 "Metric" 1 "Imperial" 2 "TonsPounds" 3 "NoAction" ;
VAL_ 2566786854 VolumeUnitCmd 0 "Metric" 1 "Imperial" 2 "US" 3 "NoAction" ;
VAL_ 2566786854 AreaUnitCmd 0 "Metric" 1 "Imperial" 3 "NoAction" ;
VAL_ 2566786854 DistanceUnitCmd 0 "Metric" 1 "Imperial" 3 "NoAction" ;
VAL_ 2566786854 UnitsSystem 0 "Metric" 1 "Imperial" 2 "US" 3 "NoAction" ;
VAL_ 2566786854 ForceUnits 0 "Metric" 1 "Imperial" 2 "Reserved" 3 "NoAction" ;
VAL_ 2566786854 PressureUnits 0 "Metric" 1 "Imperial" 2 "Reserved" 3 "NoAction" ;
VAL_ 2566786854 TemperatureUnits 0 "Metric" 1 "Imperial" 2 "Reserved" 3 "NoAction" ;
VAL_ 2565799462 IndustryGroup 0 "Global" 1 "OnHighway" 2 "AgriculturalAndForestry" 3 "Construction" 4 "Marine" 5 "Reserved" 7 "NotAvailable" ;
VAL_ 2565799462 Function 43 "Transmission Display" 44 "Exhaust Emission Control" 45 "Vehicle Dynamic Stability Control" 46 "Oil Sensor Unit" 47 "Information System Controller" 48 "Ramp Control" 49 "Clutch/Converter Control" 50 "Auxiliary Heater" 51 "Forward-Looking Collision Warning System" 52 "Chassis Controller" 53 "Alternator/Charging System" 54 "Communications Unit, Cellular" 55 "Communications Unit, Satellite" 56 "Communications Unit, Radio" 57 "Steering Column Unit" 58 "Fan Drive Control" 59 "Starter" 60 "Cab Display" 61 "File Server/Printer" 62 "On-Board Diagnostic Unit" 63 "Engine Valve Controller" 64 "Endurance Braking" 65 "Gas Flow Measurement" 66 "I/O Controller" 67 "Electrical System Controller" 68 "Aftertreatment system gas measurement" 69 "Engine Emission Aftertreatement System" 70 "Auxiliary Regeneration Device" 71 "Transfer Case Control" 72 "Coolant Valve Controller" 73 "Rollover Detection Control" 74 "Lubrication System" 75 "Supplemental Fan" 76 "Temperature Sensor" 77 "Fuel Properties Sensor" 78 "Fire Suppression System" 79 "Power Systems Manager" 80 "Electric Powertrain" 81 "Hydraulic Powertrain" 82 "File Server" 83 "Printer" 84 "Start Aid Device" 85 "Engine Injection Control Module" 86 "Reserved" 87 "Reserved" 88 "Reserved" 89 "Reserved" 90 "Reserved" 91 "Reserved" 92 "Reserved" 93 "Reserved" 94 "Reserved" 95 "Reserved" 96 "Reserved" 97 "Reserved" 98 "Reserved" 99 "Reserved" 100 "Reserved" 0 "Engine" 1 "Auxiliary Power Unit (APU)" 2 "Electric Propulsion Control" 3 "Transmission" 4 "Battery Pack Monitor" 5 "Shift Control/Console" 6 "Power TakeOff - (Main or Rear)" 7 "Axle - Steering" 8 "Axle - Drive" 9 "Brakes - System Controller" 10 "Brakes - Steer Axle" 11 "Brakes - Drive Axle" 12 "Retarder - Engine" 13 "Retarder - Driveline" 14 "Cruise Control" 15 "Fuel System" 16 "Steering Controller" 17 "Suspension - Steer Axle" 18 "Suspension - Drive Axle" 19 "Instrument Cluster" 20 "Trip Recorder" 21 "Cab Climate Control" 22 "Aerodynamic Control" 23 "Vehicle Navigation" 24 "Vehicle Security" 25 "Network Interconnect ECU" 26 "Body Controller" 27 "Power TakeOff (Secondary or Front)" 28 "Off Vehicle Gateway" 29 "Virtual Terminal (in cab)" 30 "Management Computer" 31 "Propulsion Battery Charger" 32 "Headway Controller" 33 "System Monitor" 34 "Hydraulic Pump Controller" 35 "Suspension - System Controller" 36 "Pneumatic - System Controller" 37 "Cab Controller" 38 "Tire Pressure Control" 39 "Ignition Control Module" 40 "Seat Control" 41 "Lighting - Operator Controls" 42 "Water Pump Control" 101 "Reserved" 102 "Reserved" 103 "Reserved" 104 "Reserved" 105 "Reserved" 106 "Reserved" 107 "Reserved" 108 "Reserved" 109 "Reserved" 110 "Reserved" 111 "Reserved" 112 "Reserved" 113 "Reserved" 114 "Reserved" 115 "Reserved" 116 "Reserved" 117 "Reserved" 118 "Reserved" 119 "Reserved" 120 "Reserved" 121 "Reserved" 122 "Reserved" 123 "Reserved" 124 "Reserved" 125 "Reserved" 126 "Reserved" 127 "Reserved" 255 "Not Available" ;
VAL_ 2565799462 ManufacturerCode 1863 "Thomas G. Faria Co." 1862 "Sanshin" 1861 "Vector North America" 1860 "MMP" 1859 "Kvasar AB" 1858 "Litton" 1857 "Simrad" 1856 "Trimble" 1855 "Furuno USA" 1854 "Northstar Technologies" 1853 "Japan Radio Co." 1852 "Navionics" 1851 "Raymarine" 1850 "Teleflex" 222 "Generac Power Systems, Inc." 221 "SiE" 220 "Beede Electrical Instrument Company, Inc." 219 "Cat OEM Solutions" 218 "Gits Manufacturing Company" 217 "RM Michaelides Software & Elektronik GmbH" 216 "Paneltronics Inc." 215 "Aetna Engineering/Fireboy-Xintex" 214 "MC elettronica Srl" 213 "CNH Belgium N.V." 212 "Sure Power Industries, Inc." 211 "DNA Group" 210 "Iteris, Inc." 209 "Bell Equip. Co. SA (PTY) LTD" 208 "Drew Technologies, Inc." 207 "Otto Engineering" 206 "port GmbH" 205 "SmarTire Systems Inc" 204 "The Morey Corporation" 203 "MILtronik GmbH" 202 "Curtis Instruments, Inc." 201 "Disenos y Tecnologia S.A." 200 "MGM Brakes" 199 "Actia Corp." 198 "Mystic Valley Communications" 197 "Mechron Power Systems" 196 "LEMKEN GmbH & Co. KG" 195 "General Engine Products" 194 "TriMark Corporation" 193 "Jeppesen Marine" 192 "Floscan" 191 "XATA Corporation" 190 "Hella KGaA Hueck & Co." 189 "QUALCOMM" 188 "EMP Corp." 187 "Air-Weigh" 186 "Altronic, Inc." 185 "Beede Electrical Instrument Company" 184 "EIA Electronics" 183 "KDS Controls, Inc." 182 "Vehicle Systems Engineering B.V." 181 "Coretronics, Inc." 180 "Smart Power Systems" 179 "Midwest Technologies Illinois, LLC" 178 "Siemens VDO Automotive AG" 177 "Diagnostic System Associates" 176 "Moritz Aerospace" 175 "Veris Technologies, Inc." 174 "AB Volvo Penta" 173 "Ryeso, Inc." 172 "Yanmar Marine USA" 171 "Wachendorff Elektronik GmbH & Co. KG" 170 "Computronics Corporation Ltd." 169 "Marlin Technologies Inc." 168 "Xantrex" 167 "JLG Industries Inc." 166 "Phoenix International" 165 "CPAC Systems AB" 164 "DaimlerChrysler Off-Highway" 163 "BRP Inc." 162 "Axiomatic Technologies" 161 "Offshore Systems (UK) Limited" 160 "Nido" 159 "NTech Industries Inc." 158 "Firestone Industrial Products Company" 157 "ISSPRO Inc." 156 "ITT Industries - Cannon" 155 "Vetronix Corporation" 154 "Westerbeke Corporation" 153 "Woodward, Industrial Controls Division" 152 "Elobau Elektrobauelemente GmbH & Co. KG" 151 "Raven Industries Inc. - Flow Controls Division" 150 "Fleetguard" 149 "Holset" 148 "Blue Water Data, Inc." 147 "Nautibus Electronic GmbH" 146 "Maxima Technologies" 145 "MurCal Controls" 144 "Mercury Marine" 143 "W. Gmeiner GmbH & Co." 142 "TRW Automotive (Commercial Steering Systems)" 141 "Thales Navigation Ltd." 140 "Lowrance Electronics, Inc." 139 "Caterpillar Trimble Control Technologies (CTCT), LLC" 138 "Georg Fritzmeier GmbH & Co. KG" 137 "Maretron" 136 "Komatsu Ltd." 135 "Airmar Technology Corporation" 134 "Iris Technology Ltd." 133 "Bucher Schoerling GmbH" 132 "Mulag-Fahrzeugwerk" 131 "ITT Industries" 130 "Nido - Universal Machines B.V." 129 "OMNEX Control Systems, Inc." 128 "Gerhard Duecker GmbH & Co. KG" 127 "Holland USA" 126 "Driver Tech" 125 "Nevada Automotive Test Center" 124 "Hydac Electronic" 123 "Basler Electric" 122 "FG Wilson (Engineering) Limited" 121 "HED (Hydro Electronic Devices, Inc.)" 120 "RDS Technology Ltd." 119 "IntegriNautics" 118 "Intron GmbH" 117 "HUSCO International" 116 "BEELINE Technologies" 115 "NACCO Materials Handling Group, Inc." 114 "EControls, Inc." 113 "Stress-Tek, Inc." 112 "MECALAC" 111 "Maschinenfabrik Bernhard Krone GmbH" 110 "EPIQ Sensor-Nite" 109 "LH Technologies ApS" 108 "WTK-Elecktronik GmbH" 107 "Grimme Landmaschinen GmbH & Co. KG" 106 "BAE Systems Controls, Inc." 105 "Kiepe Elektrik GmbH & Co. KG" 104 "Claas Selbstfahrende Erntemaschinen GmbH" 103 "Agrocom GmbH & Co. Agrarsystem KG" 102 "AGCO GmbH & Co." 101 "Sensoria" 100 "VDO Technik AG" 99 "International Transmissions Ltd (ITL)" 98 "Mueller-Elektronik GmbH & Co." 97 "Ag Leader Technology, Inc." 96 "Mech@tronic IT GmbH" 95 "Pacific Insight Electronics Corp." 94 "CNH Global N.V." 93 "Perkins Engines Company Ltd." 92 "Ag-Chem Equipment Co., Inc." 91 "BSG Bodensee Steuergeraete GmbH" 90 "Knorr-Bremse SfN GmbH" 89 "Kverneland Group, Electronics Division" 88 "Satloc Precision GPS" 87 "J.C. Bamford Excavators Ltd (JCB)" 86 "C.E. Niehoff & Company" 85 "Kohler Co." 84 "New Holland UK Limited" 83 "Eaton VORAD Technologies" 82 "Bobcat/Ingersoll-Rand" 81 "Fire Research Corp" 80 "Twin Disc, Inc." 79 "Daimler Benz AG - Engine Division (PBM)" 78 "Frank W. Murphy Manufacturing, Inc." 77 "Deere Power Systems Group" 76 "unused" 75 "Deere & Co. Agricultural Division" 74 "Eaton Axle-Brake Division" 73 "LeTourneau, Inc." 72 "Sisu Corporation" 71 "Vansco Electronics Ltd." 70 "Flex-Coil Limited" 69 "Trimble Navigation" 68 "Scania" 67 "Funk Manufacturing Company" 66 "John Deere Construction Equipment Division" 65 "MAN Nutzfahrzeuge AG" 64 "unused" 63 "ZF Industries Inc." 62 "Wabco" 61 "Volvo Truck Corp." 60 "Volvo Trucks North America Inc." 59 "VES Inc." 58 "SPX Corporation, OTC Division" 57 "Sauer-Danfoss Co." 56 "SAIC" 55 "Ryder System Inc." 54 "Meritor Wabco" 53 "Rockwell Land Transportation" 52 "Meritor Automotive, Inc." 51 "Robert Bosch GmbH" 50 "Robert Bosch Corp" 49 "RE America Inc." 48 "Pollak Alphabet" 47 "Phillips Semiconductor" 46 "Parasoft Computing Solutions" 45 "PACCAR" 44 "Nippondenso Co. Ltd." 43 "International Truck and Engine Corp. Vehicle Electronics" 42 "International Truck and Engine Corp. Engine Electronics" 41 "Motorola Inc." 40 "Motorola AIEG Inc." 39 "Microfirm Inc." 38 "Micro Processor Systems Inc." 37 "Mack Trucks Inc." 36 "Lucas Ltd." 35 "Kenworth Truck Co." 34 "Kelsey Hayes Co." 33 "John Deere" 32 "Jacobs Vehicle Systems" 31 "J Pollak Corp." 30 "Isuzu Motors Ltd." 29 "Hino Motors Ltd." 28 "Grote Ind. Inc." 27 "GMC" 26 "General Motors Corp., Service Technology Group" 25 "Freightliner LLC" 24 "Ford Motor Co., Vehicle Controls" 23 "Ford Motor Co., Heavy Truck" 22 "Ford Motor Co., Electronic Concepts $ Systems" 21 "Echilin Inc., Midland Brake Inc." 20 "Eaton Ltd" 19 "Eaton Corp. Trucking Info Services" 18 "Eaton Corp, Transmission Division" 17 "Eaton Corp. Res & Dev" 16 "Eaton Corp." 15 "Dickey-John Corp." 14 "Detroit Diesel Corporation" 13 "Delco Electronics" 12 "Deere & Company, Precision Farming" 11 "Dearborn Group Inc." 10 "Cummins Engine Co." 9 "Chrysler Corp." 8 "Caterpillar Inc." 7 "Case Corp." 6 "Berifors Electronics AB" 5 "AMP Inc." 4 "Ametek-Dixson" 3 "Ametek, US Gauge Division" 2 "Allison Transmission, GMC" 1 "Allied Signal Inc." 0 "Reserved" ;
VAL_ 2565799462 VehicleSystem 0 "Non-specific System" 127 "Not Available" ;
VAL_ 2565799462 VehicleSystem5 127 "Not Available" 0 "Ind. Process Control Stationary" ;
VAL_ 2565799462 VehicleSystem4 100 "Deck/Cargo/Fishing equip. sys" 90 "Environmental (HVAC) Systems" 80 "Instrumentation/General Systems" 70 "Communications Systems" 60 "Navigation Systems" 50 "Propulsion Systems" 40 "Steering Systems" 30 "Power Mgmt and lighting systems" 25 "Gateway" 20 "Safety Systems" 10 "System Tools" 127 "Not Available" 0 "Non-specific System" ;
VAL_ 2565799462 VehicleSystem3 8 "Grader" 7 "Four Wheel Drive Loader" 6 "Forklift" 5 "Excavator" 4 "Crawler" 3 "Backhoe" 2 "Articulated Dump Truck" 1 "Skid Steer Loader" 127 "Not Available" 0 "Non-specific System" ;
VAL_ 2565799462 VehicleSystem2 16 "Skidder" 15 "Earth Work" 14 "Special Crops" 13 "Powered Auxiliary Device" 12 "Farm Yard Operations" 11 "Transport/Trailer" 10 "Irrigation" 9 "Forage" 8 "Root Harvesters" 7 "Harvesters" 6 "Sprayers" 5 "Fertilizers" 4 "Planters/Seeders" 3 "Secondary Tillage" 2 "Tillage" 1 "Tractor" 127 "Not Available" 0 "Non-specific System" ;
VAL_ 2565799462 VehicleSystem1 2 "Trailer" 1 "Tractor" 127 "Not Available" 0 "Non-specific System" ;
VAL_ 2565799664 IndustryGroup 0 "Global" 1 "OnHighway" 2 "AgriculturalAndForestry" 3 "Construction" 4 "Marine" 5 "Reserved" 7 "NotAvailable" ;
VAL_ 2565799664 Function 43 "Transmission Display" 44 "Exhaust Emission Control" 45 "Vehicle Dynamic Stability Control" 46 "Oil Sensor Unit" 47 "Information System Controller" 48 "Ramp Control" 49 "Clutch/Converter Control" 50 "Auxiliary Heater" 51 "Forward-Looking Collision Warning System" 52 "Chassis Controller" 53 "Alternator/Charging System" 54 "Communications Unit, Cellular" 55 "Communications Unit, Satellite" 56 "Communications Unit, Radio" 57 "Steering Column Unit" 58 "Fan Drive Control" 59 "Starter" 60 "Cab Display" 61 "File Server/Printer" 62 "On-Board Diagnostic Unit" 63 "Engine Valve Controller" 64 "Endurance Braking" 65 "Gas Flow Measurement" 66 "I/O Controller" 67 "Electrical System Controller" 68 "Aftertreatment system gas measurement" 69 "Engine Emission Aftertreatement System" 70 "Auxiliary Regeneration Device" 71 "Transfer Case Control" 72 "Coolant Valve Controller" 73 "Rollover Detection Control" 74 "Lubrication System" 75 "Supplemental Fan" 76 "Temperature Sensor" 77 "Fuel Properties Sensor" 78 "Fire Suppression System" 79 "Power Systems Manager" 80 "Electric Powertrain" 81 "Hydraulic Powertrain" 82 "File Server" 83 "Printer" 84 "Start Aid Device" 85 "Engine Injection Control Module" 86 "Reserved" 87 "Reserved" 88 "Reserved" 89 "Reserved" 90 "Reserved" 91 "Reserved" 92 "Reserved" 93 "Reserved" 94 "Reserved" 95 "Reserved" 96 "Reserved" 97 "Reserved" 98 "Reserved" 99 "Reserved" 100 "Reserved" 0 "Engine" 1 "Auxiliary Power Unit (APU)" 2 "Electric Propulsion Control" 3 "Transmission" 4 "Battery Pack Monitor" 5 "Shift Control/Console" 6 "Power TakeOff - (Main or Rear)" 7 "Axle - Steering" 8 "Axle - Drive" 9 "Brakes - System Controller" 10 "Brakes - Steer Axle" 11 "Brakes - Drive Axle" 12 "Retarder - Engine" 13 "Retarder - Driveline" 14 "Cruise Control" 15 "Fuel System" 16 "Steering Controller" 17 "Suspension - Steer Axle" 18 "Suspension - Drive Axle" 19 "Instrument Cluster" 20 "Trip Recorder" 21 "Cab Climate Control" 22 "Aerodynamic Control" 23 "Vehicle Navigation" 24 "Vehicle Security" 25 "Network Interconnect ECU" 26 "Body Controller" 27 "Power TakeOff (Secondary or Front)" 28 "Off Vehicle Gateway" 29 "Virtual Terminal (in cab)" 30 "Management Computer" 31 "Propulsion Battery Charger" 32 "Headway Controller" 33 "System Monitor" 34 "Hydraulic Pump Controller" 35 "Suspension - System Controller" 36 "Pneumatic - System Controller" 37 "Cab Controller" 38 "Tire Pressure Control" 39 "Ignition Control Module" 40 "Seat Control" 41 "Lighting - Operator Controls" 42 "Water Pump Control" 101 "Reserved" 102 "Reserved" 103 "Reserved" 104 "Reserved" 105 "Reserved" 106 "Reserved" 107 "Reserved" 108 "Reserved" 109 "Reserved" 110 "Reserved" 111 "Reserved" 112 "Reserved" 113 "Reserved" 114 "Reserved" 115 "Reserved" 116 "Reserved" 117 "Reserved" 118 "Reserved" 119 "Reserved" 120 "Reserved" 121 "Reserved" 122 "Reserved" 123 "Reserved" 124 "Reserved" 125 "Reserved" 126 "Reserved" 127 "Reserved" 255 "Not Available" ;
VAL_ 2565799664 ManufacturerCode 1863 "Thomas G. Faria Co." 1862 "Sanshin" 1861 "Vector North America" 1860 "MMP" 1859 "Kvasar AB" 1858 "Litton" 1857 "Simrad" 1856 "Trimble" 1855 "Furuno USA" 1854 "Northstar Technologies" 1853 "Japan Radio Co." 1852 "Navionics" 1851 "Raymarine" 1850 "Teleflex" 222 "Generac Power Systems, Inc." 221 "SiE" 220 "Beede Electrical Instrument Company, Inc." 219 "Cat OEM Solutions" 218 "Gits Manufacturing Company" 217 "RM Michaelides Software & Elektronik GmbH" 216 "Paneltronics Inc." 215 "Aetna Engineering/Fireboy-Xintex" 214 "MC elettronica Srl" 213 "CNH Belgium N.V." 212 "Sure Power Industries, Inc." 211 "DNA Group" 210 "Iteris, Inc." 209 "Bell Equip. Co. SA (PTY) LTD" 208 "Drew Technologies, Inc." 207 "Otto Engineering" 206 "port GmbH" 205 "SmarTire Systems Inc" 204 "The Morey Corporation" 203 "MILtronik GmbH" 202 "Curtis Instruments, Inc." 201 "Disenos y Tecnologia S.A." 200 "MGM Brakes" 199 "Actia Corp." 198 "Mystic Valley Communications" 197 "Mechron Power Systems" 196 "LEMKEN GmbH & Co. KG" 195 "General Engine Products" 194 "TriMark Corporation" 193 "Jeppesen Marine" 192 "Floscan" 191 "XATA Corporation" 190 "Hella KGaA Hueck & Co." 189 "QUALCOMM" 188 "EMP Corp." 187 "Air-Weigh" 186 "Altronic, Inc." 185 "Beede Electrical Instrument Company" 184 "EIA Electronics" 183 "KDS Controls, Inc." 182 "Vehicle Systems Engineering B.V." 181 "Coretronics, Inc." 180 "Smart Power Systems" 179 "Midwest Technologies Illinois, LLC" 178 "Siemens VDO Automotive AG" 177 "Diagnostic System Associates" 176 "Moritz Aerospace" 175 "Veris Technologies, Inc." 174 "AB Volvo Penta" 173 "Ryeso, Inc." 172 "Yanmar Marine USA" 171 "Wachendorff Elektronik GmbH & Co. KG" 170 "Computronics Corporation Ltd." 169 "Marlin Technologies Inc." 168 "Xantrex" 167 "JLG Industries Inc." 166 "Phoenix International" 165 "CPAC Systems AB" 164 "DaimlerChrysler Off-Highway" 163 "BRP Inc." 162 "Axiomatic Technologies" 161 "Offshore Systems (UK) Limited" 160 "Nido" 159 "NTech Industries Inc." 158 "Firestone Industrial Products Company" 157 "ISSPRO Inc." 156 "ITT Industries - Cannon" 155 "Vetronix Corporation" 154 "Westerbeke Corporation" 153 "Woodward, Industrial Controls Division" 152 "Elobau Elektrobauelemente GmbH & Co. KG" 151 "Raven Industries Inc. - Flow Controls Division" 150 "Fleetguard" 149 "Holset" 148 "Blue Water Data, Inc." 147 "Nautibus Electronic GmbH" 146 "Maxima Technologies" 145 "MurCal Controls" 144 "Mercury Marine" 143 "W. Gmeiner GmbH & Co." 142 "TRW Automotive (Commercial Steering Systems)" 141 "Thales Navigation Ltd." 140 "Lowrance Electronics, Inc." 139 "Caterpillar Trimble Control Technologies (CTCT), LLC" 138 "Georg Fritzmeier GmbH & Co. KG" 137 "Maretron" 136 "Komatsu Ltd." 135 "Airmar Technology Corporation" 134 "Iris Technology Ltd." 133 "Bucher Schoerling GmbH" 132 "Mulag-Fahrzeugwerk" 131 "ITT Industries" 130 "Nido - Universal Machines B.V." 129 "OMNEX Control Systems, Inc." 128 "Gerhard Duecker GmbH & Co. KG" 127 "Holland USA" 126 "Driver Tech" 125 "Nevada Automotive Test Center" 124 "Hydac Electronic" 123 "Basler Electric" 122 "FG Wilson (Engineering) Limited" 121 "HED (Hydro Electronic Devices, Inc.)" 120 "RDS Technology Ltd." 119 "IntegriNautics" 118 "Intron GmbH" 117 "HUSCO International" 116 "BEELINE Technologies" 115 "NACCO Materials Handling Group, Inc." 114 "EControls, Inc." 113 "Stress-Tek, Inc." 112 "MECALAC" 111 "Maschinenfabrik Bernhard Krone GmbH" 110 "EPIQ Sensor-Nite" 109 "LH Technologies ApS" 108 "WTK-Elecktronik GmbH" 107 "Grimme Landmaschinen GmbH & Co. KG" 106 "BAE Systems Controls, Inc." 105 "Kiepe Elektrik GmbH & Co. KG" 104 "Claas Selbstfahrende Erntemaschinen GmbH" 103 "Agrocom GmbH & Co. Agrarsystem KG" 102 "AGCO GmbH & Co." 101 "Sensoria" 100 "VDO Technik AG" 99 "International Transmissions Ltd (ITL)" 98 "Mueller-Elektronik GmbH & Co." 97 "Ag Leader Technology, Inc." 96 "Mech@tronic IT GmbH" 95 "Pacific Insight Electronics Corp." 94 "CNH Global N.V." 93 "Perkins Engines Company Ltd." 92 "Ag-Chem Equipment Co., Inc." 91 "BSG Bodensee Steuergeraete GmbH" 90 "Knorr-Bremse SfN GmbH" 89 "Kverneland Group, Electronics Division" 88 "Satloc Precision GPS" 87 "J.C. Bamford Excavators Ltd (JCB)" 86 "C.E. Niehoff & Company" 85 "Kohler Co." 84 "New Holland UK Limited" 83 "Eaton VORAD Technologies" 82 "Bobcat/Ingersoll-Rand" 81 "Fire Research Corp" 80 "Twin Disc, Inc." 79 "Daimler Benz AG - Engine Division (PBM)" 78 "Frank W. Murphy Manufacturing, Inc." 77 "Deere Power Systems Group" 76 "unused" 75 "Deere & Co. Agricultural Division" 74 "Eaton Axle-Brake Division" 73 "LeTourneau, Inc." 72 "Sisu Corporation" 71 "Vansco Electronics Ltd." 70 "Flex-Coil Limited" 69 "Trimble Navigation" 68 "Scania" 67 "Funk Manufacturing Company" 66 "John Deere Construction Equipment Division" 65 "MAN Nutzfahrzeuge AG" 64 "unused" 63 "ZF Industries Inc." 62 "Wabco" 61 "Volvo Truck Corp." 60 "Volvo Trucks North America Inc." 59 "VES Inc." 58 "SPX Corporation, OTC Division" 57 "Sauer-Danfoss Co." 56 "SAIC" 55 "Ryder System Inc." 54 "Meritor Wabco" 53 "Rockwell Land Transportation" 52 "Meritor Automotive, Inc." 51 "Robert Bosch GmbH" 50 "Robert Bosch Corp" 49 "RE America Inc." 48 "Pollak Alphabet" 47 "Phillips Semiconductor" 46 "Parasoft Computing Solutions" 45 "PACCAR" 44 "Nippondenso Co. Ltd." 43 "International Truck and Engine Corp. Vehicle Electronics" 42 "International Truck and Engine Corp. Engine Electronics" 41 "Motorola Inc." 40 "Motorola AIEG Inc." 39 "Microfirm Inc." 38 "Micro Processor Systems Inc." 37 "Mack Trucks Inc." 36 "Lucas Ltd." 35 "Kenworth Truck Co." 34 "Kelsey Hayes Co." 33 "John Deere" 32 "Jacobs Vehicle Systems" 31 "J Pollak Corp." 30 "Isuzu Motors Ltd." 29 "Hino Motors Ltd." 28 "Grote Ind. Inc." 27 "GMC" 26 "General Motors Corp., Service Technology Group" 25 "Freightliner LLC" 24 "Ford Motor Co., Vehicle Controls" 23 "Ford Motor Co., Heavy Truck" 22 "Ford Motor Co., Electronic Concepts $ Systems" 21 "Echilin Inc., Midland Brake Inc." 20 "Eaton Ltd" 19 "Eaton Corp. Trucking Info Services" 18 "Eaton Corp, Transmission Division" 17 "Eaton Corp. Res & Dev" 16 "Eaton Corp." 15 "Dickey-John Corp." 14 "Detroit Diesel Corporation" 13 "Delco Electronics" 12 "Deere & Company, Precision Farming" 11 "Dearborn Group Inc." 10 "Cummins Engine Co." 9 "Chrysler Corp." 8 "Caterpillar Inc." 7 "Case Corp." 6 "Berifors Electronics AB" 5 "AMP Inc." 4 "Ametek-Dixson" 3 "Ametek, US Gauge Division" 2 "Allison Transmission, GMC" 1 "Allied Signal Inc." 0 "Reserved" ;
VAL_ 2565799664 VehicleSystem 0 "Non-specific System" 127 "Not Available" ;
VAL_ 2565799664 VehicleSystem5 127 "Not Available" 0 "Ind. Process Control Stationary" ;
VAL_ 2565799664 VehicleSystem4 100 "Deck/Cargo/Fishing equip. sys" 90 "Environmental (HVAC) Systems" 80 "Instrumentation/General Systems" 70 "Communications Systems" 60 "Navigation Systems" 50 "Propulsion Systems" 40 "Steering Systems" 30 "Power Mgmt and lighting systems" 25 "Gateway" 20 "Safety Systems" 10 "System Tools" 127 "Not Available" 0 "Non-specific System" ;
VAL_ 2565799664 VehicleSystem3 8 "Grader" 7 "Four Wheel Drive Loader" 6 "Forklift" 5 "Excavator" 4 "Crawler" 3 "Backhoe" 2 "Articulated Dump Truck" 1 "Skid Steer Loader" 127 "Not Available" 0 "Non-specific System" ;
VAL_ 2565799664 VehicleSystem2 16 "Skidder" 15 "Earth Work" 14 "Special Crops" 13 "Powered Auxiliary Device" 12 "Farm Yard Operations" 11 "Transport/Trailer" 10 "Irrigation" 9 "Forage" 8 "Root Harvesters" 7 "Harvesters" 6 "Sprayers" 5 "Fertilizers" 4 "Planters/Seeders" 3 "Secondary Tillage" 2 "Tillage" 1 "Tractor" 127 "Not Available" 0 "Non-specific System" ;
VAL_ 2565799664 VehicleSystem1 2 "Trailer" 1 "Tractor" 127 "Not Available" 0 "Non-specific System" ;
VAL_ 2565799671 IndustryGroup 0 "Global" 1 "OnHighway" 2 "AgriculturalAndForestry" 3 "Construction" 4 "Marine" 5 "Reserved" 7 "NotAvailable" ;
VAL_ 2565799671 Function 43 "Transmission Display" 44 "Exhaust Emission Control" 45 "Vehicle Dynamic Stability Control" 46 "Oil Sensor Unit" 47 "Information System Controller" 48 "Ramp Control" 49 "Clutch/Converter Control" 50 "Auxiliary Heater" 51 "Forward-Looking Collision Warning System" 52 "Chassis Controller" 53 "Alternator/Charging System" 54 "Communications Unit, Cellular" 55 "Communications Unit, Satellite" 56 "Communications Unit, Radio" 57 "Steering Column Unit" 58 "Fan Drive Control" 59 "Starter" 60 "Cab Display" 61 "File Server/Printer" 62 "On-Board Diagnostic Unit" 63 "Engine Valve Controller" 64 "Endurance Braking" 65 "Gas Flow Measurement" 66 "I/O Controller" 67 "Electrical System Controller" 68 "Aftertreatment system gas measurement" 69 "Engine Emission Aftertreatement System" 70 "Auxiliary Regeneration Device" 71 "Transfer Case Control" 72 "Coolant Valve Controller" 73 "Rollover Detection Control" 74 "Lubrication System" 75 "Supplemental Fan" 76 "Temperature Sensor" 77 "Fuel Properties Sensor" 78 "Fire Suppression System" 79 "Power Systems Manager" 80 "Electric Powertrain" 81 "Hydraulic Powertrain" 82 "File Server" 83 "Printer" 84 "Start Aid Device" 85 "Engine Injection Control Module" 86 "Reserved" 87 "Reserved" 88 "Reserved" 89 "Reserved" 90 "Reserved" 91 "Reserved" 92 "Reserved" 93 "Reserved" 94 "Reserved" 95 "Reserved" 96 "Reserved" 97 "Reserved" 98 "Reserved" 99 "Reserved" 100 "Reserved" 0 "Engine" 1 "Auxiliary Power Unit (APU)" 2 "Electric Propulsion Control" 3 "Transmission" 4 "Battery Pack Monitor" 5 "Shift Control/Console" 6 "Power TakeOff - (Main or Rear)" 7 "Axle - Steering" 8 "Axle - Drive" 9 "Brakes - System Controller" 10 "Brakes - Steer Axle" 11 "Brakes - Drive Axle" 12 "Retarder - Engine" 13 "Retarder - Driveline" 14 "Cruise Control" 15 "Fuel System" 16 "Steering Controller" 17 "Suspension - Steer Axle" 18 "Suspension - Drive Axle" 19 "Instrument Cluster" 20 "Trip Recorder" 21 "Cab Climate Control" 22 "Aerodynamic Control" 23 "Vehicle Navigation" 24 "Vehicle Security" 25 "Network Interconnect ECU" 26 "Body Controller" 27 "Power TakeOff (Secondary or Front)" 28 "Off Vehicle Gateway" 29 "Virtual Terminal (in cab)" 30 "Management Computer" 31 "Propulsion Battery Charger" 32 "Headway Controller" 33 "System Monitor" 34 "Hydraulic Pump Controller" 35 "Suspension - System Controller" 36 "Pneumatic - System Controller" 37 "Cab Controller" 38 "Tire Pressure Control" 39 "Ignition Control Module" 40 "Seat Control" 41 "Lighting - Operator Controls" 42 "Water Pump Control" 101 "Reserved" 102 "Reserved" 103 "Reserved" 104 "Reserved" 105 "Reserved" 106 "Reserved" 107 "Reserved" 108 "Reserved" 109 "Reserved" 110 "Reserved" 111 "Reserved" 112 "Reserved" 113 "Reserved" 114 "Reserved" 115 "Reserved" 116 "Reserved" 117 "Reserved" 118 "Reserved" 119 "Reserved" 120 "Reserved" 121 "Reserved" 122 "Reserved" 123 "Reserved" 124 "Reserved" 125 "Reserved" 126 "Reserved" 127 "Reserved" 255 "Not Available" ;
VAL_ 2565799671 ManufacturerCode 1863 "Thomas G. Faria Co." 1862 "Sanshin" 1861 "Vector North America" 1860 "MMP" 1859 "Kvasar AB" 1858 "Litton" 1857 "Simrad" 1856 "Trimble" 1855 "Furuno USA" 1854 "Northstar Technologies" 1853 "Japan Radio Co." 1852 "Navionics" 1851 "Raymarine" 1850 "Teleflex" 222 "Generac Power Systems, Inc." 221 "SiE" 220 "Beede Electrical Instrument Company, Inc." 219 "Cat OEM Solutions" 218 "Gits Manufacturing Company" 217 "RM Michaelides Software & Elektronik GmbH" 216 "Paneltronics Inc." 215 "Aetna Engineering/Fireboy-Xintex" 214 "MC elettronica Srl" 213 "CNH Belgium N.V." 212 "Sure Power Industries, Inc." 211 "DNA Group" 210 "Iteris, Inc." 209 "Bell Equip. Co. SA (PTY) LTD" 208 "Drew Technologies, Inc." 207 "Otto Engineering" 206 "port GmbH" 205 "SmarTire Systems Inc" 204 "The Morey Corporation" 203 "MILtronik GmbH" 202 "Curtis Instruments, Inc." 201 "Disenos y Tecnologia S.A." 200 "MGM Brakes" 199 "Actia Corp." 198 "Mystic Valley Communications" 197 "Mechron Power Systems" 196 "LEMKEN GmbH & Co. KG" 195 "General Engine Products" 194 "TriMark Corporation" 193 "Jeppesen Marine" 192 "Floscan" 191 "XATA Corporation" 190 "Hella KGaA Hueck & Co." 189 "QUALCOMM" 188 "EMP Corp." 187 "Air-Weigh" 186 "Altronic, Inc." 185 "Beede Electrical Instrument Company" 184 "EIA Electronics" 183 "KDS Controls, Inc." 182 "Vehicle Systems Engineering B.V." 181 "Coretronics, Inc." 180 "Smart Power Systems" 179 "Midwest Technologies Illinois, LLC" 178 "Siemens VDO Automotive AG" 177 "Diagnostic System Associates" 176 "Moritz Aerospace" 175 "Veris Technologies, Inc." 174 "AB Volvo Penta" 173 "Ryeso, Inc." 172 "Yanmar Marine USA" 171 "Wachendorff Elektronik GmbH & Co. KG" 170 "Computronics Corporation Ltd." 169 "Marlin Technologies Inc." 168 "Xantrex" 167 "JLG Industries Inc." 166 "Phoenix International" 165 "CPAC Systems AB" 164 "DaimlerChrysler Off-Highway" 163 "BRP Inc." 162 "Axiomatic Technologies" 161 "Offshore Systems (UK) Limited" 160 "Nido" 159 "NTech Industries Inc." 158 "Firestone Industrial Products Company" 157 "ISSPRO Inc." 156 "ITT Industries - Cannon" 155 "Vetronix Corporation" 154 "Westerbeke Corporation" 153 "Woodward, Industrial Controls Division" 152 "Elobau Elektrobauelemente GmbH & Co. KG" 151 "Raven Industries Inc. - Flow Controls Division" 150 "Fleetguard" 149 "Holset" 148 "Blue Water Data, Inc." 147 "Nautibus Electronic GmbH" 146 "Maxima Technologies" 145 "MurCal Controls" 144 "Mercury Marine" 143 "W. Gmeiner GmbH & Co." 142 "TRW Automotive (Commercial Steering Systems)" 141 "Thales Navigation Ltd." 140 "Lowrance Electronics, Inc." 139 "Caterpillar Trimble Control Technologies (CTCT), LLC" 138 "Georg Fritzmeier GmbH & Co. KG" 137 "Maretron" 136 "Komatsu Ltd." 135 "Airmar Technology Corporation" 134 "Iris Technology Ltd." 133 "Bucher Schoerling GmbH" 132 "Mulag-Fahrzeugwerk" 131 "ITT Industries" 130 "Nido - Universal Machines B.V." 129 "OMNEX Control Systems, Inc." 128 "Gerhard Duecker GmbH & Co. KG" 127 "Holland USA" 126 "Driver Tech" 125 "Nevada Automotive Test Center" 124 "Hydac Electronic" 123 "Basler Electric" 122 "FG Wilson (Engineering) Limited" 121 "HED (Hydro Electronic Devices, Inc.)" 120 "RDS Technology Ltd." 119 "IntegriNautics" 118 "Intron GmbH" 117 "HUSCO International" 116 "BEELINE Technologies" 115 "NACCO Materials Handling Group, Inc." 114 "EControls, Inc." 113 "Stress-Tek, Inc." 112 "MECALAC" 111 "Maschinenfabrik Bernhard Krone GmbH" 110 "EPIQ Sensor-Nite" 109 "LH Technologies ApS" 108 "WTK-Elecktronik GmbH" 107 "Grimme Landmaschinen GmbH & Co. KG" 106 "BAE Systems Controls, Inc." 105 "Kiepe Elektrik GmbH & Co. KG" 104 "Claas Selbstfahrende Erntemaschinen GmbH" 103 "Agrocom GmbH & Co. Agrarsystem KG" 102 "AGCO GmbH & Co." 101 "Sensoria" 100 "VDO Technik AG" 99 "International Transmissions Ltd (ITL)" 98 "Mueller-Elektronik GmbH & Co." 97 "Ag Leader Technology, Inc." 96 "Mech@tronic IT GmbH" 95 "Pacific Insight Electronics Corp." 94 "CNH Global N.V." 93 "Perkins Engines Company Ltd." 92 "Ag-Chem Equipment Co., Inc." 91 "BSG Bodensee Steuergeraete GmbH" 90 "Knorr-Bremse SfN GmbH" 89 "Kverneland Group, Electronics Division" 88 "Satloc Precision GPS" 87 "J.C. Bamford Excavators Ltd (JCB)" 86 "C.E. Niehoff & Company" 85 "Kohler Co." 84 "New Holland UK Limited" 83 "Eaton VORAD Technologies" 82 "Bobcat/Ingersoll-Rand" 81 "Fire Research Corp" 80 "Twin Disc, Inc." 79 "Daimler Benz AG - Engine Division (PBM)" 78 "Frank W. Murphy Manufacturing, Inc." 77 "Deere Power Systems Group" 76 "unused" 75 "Deere & Co. Agricultural Division" 74 "Eaton Axle-Brake Division" 73 "LeTourneau, Inc." 72 "Sisu Corporation" 71 "Vansco Electronics Ltd." 70 "Flex-Coil Limited" 69 "Trimble Navigation" 68 "Scania" 67 "Funk Manufacturing Company" 66 "John Deere Construction Equipment Division" 65 "MAN Nutzfahrzeuge AG" 64 "unused" 63 "ZF Industries Inc." 62 "Wabco" 61 "Volvo Truck Corp." 60 "Volvo Trucks North America Inc." 59 "VES Inc." 58 "SPX Corporation, OTC Division" 57 "Sauer-Danfoss Co." 56 "SAIC" 55 "Ryder System Inc." 54 "Meritor Wabco" 53 "Rockwell Land Transportation" 52 "Meritor Automotive, Inc." 51 "Robert Bosch GmbH" 50 "Robert Bosch Corp" 49 "RE America Inc." 48 "Pollak Alphabet" 47 "Phillips Semiconductor" 46 "Parasoft Computing Solutions" 45 "PACCAR" 44 "Nippondenso Co. Ltd." 43 "International Truck and Engine Corp. Vehicle Electronics" 42 "International Truck and Engine Corp. Engine Electronics" 41 "Motorola Inc." 40 "Motorola AIEG Inc." 39 "Microfirm Inc." 38 "Micro Processor Systems Inc." 37 "Mack Trucks Inc." 36 "Lucas Ltd." 35 "Kenworth Truck Co." 34 "Kelsey Hayes Co." 33 "John Deere" 32 "Jacobs Vehicle Systems" 31 "J Pollak Corp." 30 "Isuzu Motors Ltd." 29 "Hino Motors Ltd." 28 "Grote Ind. Inc." 27 "GMC" 26 "General Motors Corp., Service Technology Group" 25 "Freightliner LLC" 24 "Ford Motor Co., Vehicle Controls" 23 "Ford Motor Co., Heavy Truck" 22 "Ford Motor Co., Electronic Concepts $ Systems" 21 "Echilin Inc., Midland Brake Inc." 20 "Eaton Ltd" 19 "Eaton Corp. Trucking Info Services" 18 "Eaton Corp, Transmission Division" 17 "Eaton Corp. Res & Dev" 16 "Eaton Corp." 15 "Dickey-John Corp." 14 "Detroit Diesel Corporation" 13 "Delco Electronics" 12 "Deere & Company, Precision Farming" 11 "Dearborn Group Inc." 10 "Cummins Engine Co." 9 "Chrysler Corp." 8 "Caterpillar Inc." 7 "Case Corp." 6 "Berifors Electronics AB" 5 "AMP Inc." 4 "Ametek-Dixson" 3 "Ametek, US Gauge Division" 2 "Allison Transmission, GMC" 1 "Allied Signal Inc." 0 "Reserved" ;
VAL_ 2565799671 VehicleSystem 0 "Non-specific System" 127 "Not Available" ;
VAL_ 2565799671 VehicleSystem5 127 "Not Available" 0 "Ind. Process Control Stationary" ;
VAL_ 2565799671 VehicleSystem4 100 "Deck/Cargo/Fishing equip. sys" 90 "Environmental (HVAC) Systems" 80 "Instrumentation/General Systems" 70 "Communications Systems" 60 "Navigation Systems" 50 "Propulsion Systems" 40 "Steering Systems" 30 "Power Mgmt and lighting systems" 25 "Gateway" 20 "Safety Systems" 10 "System Tools" 127 "Not Available" 0 "Non-specific System" ;
VAL_ 2565799671 VehicleSystem3 8 "Grader" 7 "Four Wheel Drive Loader" 6 "Forklift" 5 "Excavator" 4 "Crawler" 3 "Backhoe" 2 "Articulated Dump Truck" 1 "Skid Steer Loader" 127 "Not Available" 0 "Non-specific System" ;
VAL_ 2565799671 VehicleSystem2 16 "Skidder" 15 "Earth Work" 14 "Special Crops" 13 "Powered Auxiliary Device" 12 "Farm Yard Operations" 11 "Transport/Trailer" 10 "Irrigation" 9 "Forage" 8 "Root Harvesters" 7 "Harvesters" 6 "Sprayers" 5 "Fertilizers" 4 "Planters/Seeders" 3 "Secondary Tillage" 2 "Tillage" 1 "Tractor" 127 "Not Available" 0 "Non-specific System" ;
VAL_ 2565799671 VehicleSystem1 2 "Trailer" 1 "Tractor" 127 "Not Available" 0 "Non-specific System" ;
VAL_ 2565799552 IndustryGroup 0 "Global" 1 "OnHighway" 2 "AgriculturalAndForestry" 3 "Construction" 4 "Marine" 5 "Reserved" 7 "NotAvailable" ;
VAL_ 2565799552 Function 43 "Transmission Display" 44 "Exhaust Emission Control" 45 "Vehicle Dynamic Stability Control" 46 "Oil Sensor Unit" 47 "Information System Controller" 48 "Ramp Control" 49 "Clutch/Converter Control" 50 "Auxiliary Heater" 51 "Forward-Looking Collision Warning System" 52 "Chassis Controller" 53 "Alternator/Charging System" 54 "Communications Unit, Cellular" 55 "Communications Unit, Satellite" 56 "Communications Unit, Radio" 57 "Steering Column Unit" 58 "Fan Drive Control" 59 "Starter" 60 "Cab Display" 61 "File Server/Printer" 62 "On-Board Diagnostic Unit" 63 "Engine Valve Controller" 64 "Endurance Braking" 65 "Gas Flow Measurement" 66 "I/O Controller" 67 "Electrical System Controller" 68 "Aftertreatment system gas measurement" 69 "Engine Emission Aftertreatement System" 70 "Auxiliary Regeneration Device" 71 "Transfer Case Control" 72 "Coolant Valve Controller" 73 "Rollover Detection Control" 74 "Lubrication System" 75 "Supplemental Fan" 76 "Temperature Sensor" 77 "Fuel Properties Sensor" 78 "Fire Suppression System" 79 "Power Systems Manager" 80 "Electric Powertrain" 81 "Hydraulic Powertrain" 82 "File Server" 83 "Printer" 84 "Start Aid Device" 85 "Engine Injection Control Module" 86 "Reserved" 87 "Reserved" 88 "Reserved" 89 "Reserved" 90 "Reserved" 91 "Reserved" 92 "Reserved" 93 "Reserved" 94 "Reserved" 95 "Reserved" 96 "Reserved" 97 "Reserved" 98 "Reserved" 99 "Reserved" 100 "Reserved" 0 "Engine" 1 "Auxiliary Power Unit (APU)" 2 "Electric Propulsion Control" 3 "Transmission" 4 "Battery Pack Monitor" 5 "Shift Control/Console" 6 "Power TakeOff - (Main or Rear)" 7 "Axle - Steering" 8 "Axle - Drive" 9 "Brakes - System Controller" 10 "Brakes - Steer Axle" 11 "Brakes - Drive Axle" 12 "Retarder - Engine" 13 "Retarder - Driveline" 14 "Cruise Control" 15 "Fuel System" 16 "Steering Controller" 17 "Suspension - Steer Axle" 18 "Suspension - Drive Axle" 19 "Instrument Cluster" 20 "Trip Recorder" 21 "Cab Climate Control" 22 "Aerodynamic Control" 23 "Vehicle Navigation" 24 "Vehicle Security" 25 "Network Interconnect ECU" 26 "Body Controller" 27 "Power TakeOff (Secondary or Front)" 28 "Off Vehicle Gateway" 29 "Virtual Terminal (in cab)" 30 "Management Computer" 31 "Propulsion Battery Charger" 32 "Headway Controller" 33 "System Monitor" 34 "Hydraulic Pump Controller" 35 "Suspension - System Controller" 36 "Pneumatic - System Controller" 37 "Cab Controller" 38 "Tire Pressure Control" 39 "Ignition Control Module" 40 "Seat Control" 41 "Lighting - Operator Controls" 42 "Water Pump Control" 101 "Reserved" 102 "Reserved" 103 "Reserved" 104 "Reserved" 105 "Reserved" 106 "Reserved" 107 "Reserved" 108 "Reserved" 109 "Reserved" 110 "Reserved" 111 "Reserved" 112 "Reserved" 113 "Reserved" 114 "Reserved" 115 "Reserved" 116 "Reserved" 117 "Reserved" 118 "Reserved" 119 "Reserved" 120 "Reserved" 121 "Reserved" 122 "Reserved" 123 "Reserved" 124 "Reserved" 125 "Reserved" 126 "Reserved" 127 "Reserved" 255 "Not Available" ;
VAL_ 2565799552 ManufacturerCode 1863 "Thomas G. Faria Co." 1862 "Sanshin" 1861 "Vector North America" 1860 "MMP" 1859 "Kvasar AB" 1858 "Litton" 1857 "Simrad" 1856 "Trimble" 1855 "Furuno USA" 1854 "Northstar Technologies" 1853 "Japan Radio Co." 1852 "Navionics" 1851 "Raymarine" 1850 "Teleflex" 222 "Generac Power Systems, Inc." 221 "SiE" 220 "Beede Electrical Instrument Company, Inc." 219 "Cat OEM Solutions" 218 "Gits Manufacturing Company" 217 "RM Michaelides Software & Elektronik GmbH" 216 "Paneltronics Inc." 215 "Aetna Engineering/Fireboy-Xintex" 214 "MC elettronica Srl" 213 "CNH Belgium N.V." 212 "Sure Power Industries, Inc." 211 "DNA Group" 210 "Iteris, Inc." 209 "Bell Equip. Co. SA (PTY) LTD" 208 "Drew Technologies, Inc." 207 "Otto Engineering" 206 "port GmbH" 205 "SmarTire Systems Inc" 204 "The Morey Corporation" 203 "MILtronik GmbH" 202 "Curtis Instruments, Inc." 201 "Disenos y Tecnologia S.A." 200 "MGM Brakes" 199 "Actia Corp." 198 "Mystic Valley Communications" 197 "Mechron Power Systems" 196 "LEMKEN GmbH & Co. KG" 195 "General Engine Products" 194 "TriMark Corporation" 193 "Jeppesen Marine" 192 "Floscan" 191 "XATA Corporation" 190 "Hella KGaA Hueck & Co." 189 "QUALCOMM" 188 "EMP Corp." 187 "Air-Weigh" 186 "Altronic, Inc." 185 "Beede Electrical Instrument Company" 184 "EIA Electronics" 183 "KDS Controls, Inc." 182 "Vehicle Systems Engineering B.V." 181 "Coretronics, Inc." 180 "Smart Power Systems" 179 "Midwest Technologies Illinois, LLC" 178 "Siemens VDO Automotive AG" 177 "Diagnostic System Associates" 176 "Moritz Aerospace" 175 "Veris Technologies, Inc." 174 "AB Volvo Penta" 173 "Ryeso, Inc." 172 "Yanmar Marine USA" 171 "Wachendorff Elektronik GmbH & Co. KG" 170 "Computronics Corporation Ltd." 169 "Marlin Technologies Inc." 168 "Xantrex" 167 "JLG Industries Inc." 166 "Phoenix International" 165 "CPAC Systems AB" 164 "DaimlerChrysler Off-Highway" 163 "BRP Inc." 162 "Axiomatic Technologies" 161 "Offshore Systems (UK) Limited" 160 "Nido" 159 "NTech Industries Inc." 158 "Firestone Industrial Products Company" 157 "ISSPRO Inc." 156 "ITT Industries - Cannon" 155 "Vetronix Corporation" 154 "Westerbeke Corporation" 153 "Woodward, Industrial Controls Division" 152 "Elobau Elektrobauelemente GmbH & Co. KG" 151 "Raven Industries Inc. - Flow Controls Division" 150 "Fleetguard" 149 "Holset" 148 "Blue Water Data, Inc." 147 "Nautibus Electronic GmbH" 146 "Maxima Technologies" 145 "MurCal Controls" 144 "Mercury Marine" 143 "W. Gmeiner GmbH & Co." 142 "TRW Automotive (Commercial Steering Systems)" 141 "Thales Navigation Ltd." 140 "Lowrance Electronics, Inc." 139 "Caterpillar Trimble Control Technologies (CTCT), LLC" 138 "Georg Fritzmeier GmbH & Co. KG" 137 "Maretron" 136 "Komatsu Ltd." 135 "Airmar Technology Corporation" 134 "Iris Technology Ltd." 133 "Bucher Schoerling GmbH" 132 "Mulag-Fahrzeugwerk" 131 "ITT Industries" 130 "Nido - Universal Machines B.V." 129 "OMNEX Control Systems, Inc." 128 "Gerhard Duecker GmbH & Co. KG" 127 "Holland USA" 126 "Driver Tech" 125 "Nevada Automotive Test Center" 124 "Hydac Electronic" 123 "Basler Electric" 122 "FG Wilson (Engineering) Limited" 121 "HED (Hydro Electronic Devices, Inc.)" 120 "RDS Technology Ltd." 119 "IntegriNautics" 118 "Intron GmbH" 117 "HUSCO International" 116 "BEELINE Technologies" 115 "NACCO Materials Handling Group, Inc." 114 "EControls, Inc." 113 "Stress-Tek, Inc." 112 "MECALAC" 111 "Maschinenfabrik Bernhard Krone GmbH" 110 "EPIQ Sensor-Nite" 109 "LH Technologies ApS" 108 "WTK-Elecktronik GmbH" 107 "Grimme Landmaschinen GmbH & Co. KG" 106 "BAE Systems Controls, Inc." 105 "Kiepe Elektrik GmbH & Co. KG" 104 "Claas Selbstfahrende Erntemaschinen GmbH" 103 "Agrocom GmbH & Co. Agrarsystem KG" 102 "AGCO GmbH & Co." 101 "Sensoria" 100 "VDO Technik AG" 99 "International Transmissions Ltd (ITL)" 98 "Mueller-Elektronik GmbH & Co." 97 "Ag Leader Technology, Inc." 96 "Mech@tronic IT GmbH" 95 "Pacific Insight Electronics Corp." 94 "CNH Global N.V." 93 "Perkins Engines Company Ltd." 92 "Ag-Chem Equipment Co., Inc." 91 "BSG Bodensee Steuergeraete GmbH" 90 "Knorr-Bremse SfN GmbH" 89 "Kverneland Group, Electronics Division" 88 "Satloc Precision GPS" 87 "J.C. Bamford Excavators Ltd (JCB)" 86 "C.E. Niehoff & Company" 85 "Kohler Co." 84 "New Holland UK Limited" 83 "Eaton VORAD Technologies" 82 "Bobcat/Ingersoll-Rand" 81 "Fire Research Corp" 80 "Twin Disc, Inc." 79 "Daimler Benz AG - Engine Division (PBM)" 78 "Frank W. Murphy Manufacturing, Inc." 77 "Deere Power Systems Group" 76 "unused" 75 "Deere & Co. Agricultural Division" 74 "Eaton Axle-Brake Division" 73 "LeTourneau, Inc." 72 "Sisu Corporation" 71 "Vansco Electronics Ltd." 70 "Flex-Coil Limited" 69 "Trimble Navigation" 68 "Scania" 67 "Funk Manufacturing Company" 66 "John Deere Construction Equipment Division" 65 "MAN Nutzfahrzeuge AG" 64 "unused" 63 "ZF Industries Inc." 62 "Wabco" 61 "Volvo Truck Corp." 60 "Volvo Trucks North America Inc." 59 "VES Inc." 58 "SPX Corporation, OTC Division" 57 "Sauer-Danfoss Co." 56 "SAIC" 55 "Ryder System Inc." 54 "Meritor Wabco" 53 "Rockwell Land Transportation" 52 "Meritor Automotive, Inc." 51 "Robert Bosch GmbH" 50 "Robert Bosch Corp" 49 "RE America Inc." 48 "Pollak Alphabet" 47 "Phillips Semiconductor" 46 "Parasoft Computing Solutions" 45 "PACCAR" 44 "Nippondenso Co. Ltd." 43 "International Truck and Engine Corp. Vehicle Electronics" 42 "International Truck and Engine Corp. Engine Electronics" 41 "Motorola Inc." 40 "Motorola AIEG Inc." 39 "Microfirm Inc." 38 "Micro Processor Systems Inc." 37 "Mack Trucks Inc." 36 "Lucas Ltd." 35 "Kenworth Truck Co." 34 "Kelsey Hayes Co." 33 "John Deere" 32 "Jacobs Vehicle Systems" 31 "J Pollak Corp." 30 "Isuzu Motors Ltd." 29 "Hino Motors Ltd." 28 "Grote Ind. Inc." 27 "GMC" 26 "General Motors Corp., Service Technology Group" 25 "Freightliner LLC" 24 "Ford Motor Co., Vehicle Controls" 23 "Ford Motor Co., Heavy Truck" 22 "Ford Motor Co., Electronic Concepts $ Systems" 21 "Echilin Inc., Midland Brake Inc." 20 "Eaton Ltd" 19 "Eaton Corp. Trucking Info Services" 18 "Eaton Corp, Transmission Division" 17 "Eaton Corp. Res & Dev" 16 "Eaton Corp." 15 "Dickey-John Corp." 14 "Detroit Diesel Corporation" 13 "Delco Electronics" 12 "Deere & Company, Precision Farming" 11 "Dearborn Group Inc." 10 "Cummins Engine Co." 9 "Chrysler Corp." 8 "Caterpillar Inc." 7 "Case Corp." 6 "Berifors Electronics AB" 5 "AMP Inc." 4 "Ametek-Dixson" 3 "Ametek, US Gauge Division" 2 "Allison Transmission, GMC" 1 "Allied Signal Inc." 0 "Reserved" ;
VAL_ 2565799552 VehicleSystem 0 "Non-specific System" 127 "Not Available" ;
VAL_ 2565799552 VehicleSystem5 127 "Not Available" 0 "Ind. Process Control Stationary" ;
VAL_ 2565799552 VehicleSystem4 100 "Deck/Cargo/Fishing equip. sys" 90 "Environmental (HVAC) Systems" 80 "Instrumentation/General Systems" 70 "Communications Systems" 60 "Navigation Systems" 50 "Propulsion Systems" 40 "Steering Systems" 30 "Power Mgmt and lighting systems" 25 "Gateway" 20 "Safety Systems" 10 "System Tools" 127 "Not Available" 0 "Non-specific System" ;
VAL_ 2565799552 VehicleSystem3 8 "Grader" 7 "Four Wheel Drive Loader" 6 "Forklift" 5 "Excavator" 4 "Crawler" 3 "Backhoe" 2 "Articulated Dump Truck" 1 "Skid Steer Loader" 127 "Not Available" 0 "Non-specific System" ;
VAL_ 2565799552 VehicleSystem2 16 "Skidder" 15 "Earth Work" 14 "Special Crops" 13 "Powered Auxiliary Device" 12 "Farm Yard Operations" 11 "Transport/Trailer" 10 "Irrigation" 9 "Forage" 8 "Root Harvesters" 7 "Harvesters" 6 "Sprayers" 5 "Fertilizers" 4 "Planters/Seeders" 3 "Secondary Tillage" 2 "Tillage" 1 "Tractor" 127 "Not Available" 0 "Non-specific System" ;
VAL_ 2565799552 VehicleSystem1 2 "Trailer" 1 "Tractor" 127 "Not Available" 0 "Non-specific System" ;
VAL_ 2565799452 IndustryGroup 0 "Global" 1 "OnHighway" 2 "AgriculturalAndForestry" 3 "Construction" 4 "Marine" 5 "Reserved" 7 "NotAvailable" ;
VAL_ 2565799452 Function 43 "Transmission Display" 44 "Exhaust Emission Control" 45 "Vehicle Dynamic Stability Control" 46 "Oil Sensor Unit" 47 "Information System Controller" 48 "Ramp Control" 49 "Clutch/Converter Control" 50 "Auxiliary Heater" 51 "Forward-Looking Collision Warning System" 52 "Chassis Controller" 53 "Alternator/Charging System" 54 "Communications Unit, Cellular" 55 "Communications Unit, Satellite" 56 "Communications Unit, Radio" 57 "Steering Column Unit" 58 "Fan Drive Control" 59 "Starter" 60 "Cab Display" 61 "File Server/Printer" 62 "On-Board Diagnostic Unit" 63 "Engine Valve Controller" 64 "Endurance Braking" 65 "Gas Flow Measurement" 66 "I/O Controller" 67 "Electrical System Controller" 68 "Aftertreatment system gas measurement" 69 "Engine Emission Aftertreatement System" 70 "Auxiliary Regeneration Device" 71 "Transfer Case Control" 72 "Coolant Valve Controller" 73 "Rollover Detection Control" 74 "Lubrication System" 75 "Supplemental Fan" 76 "Temperature Sensor" 77 "Fuel Properties Sensor" 78 "Fire Suppression System" 79 "Power Systems Manager" 80 "Electric Powertrain" 81 "Hydraulic Powertrain" 82 "File Server" 83 "Printer" 84 "Start Aid Device" 85 "Engine Injection Control Module" 86 "Reserved" 87 "Reserved" 88 "Reserved" 89 "Reserved" 90 "Reserved" 91 "Reserved" 92 "Reserved" 93 "Reserved" 94 "Reserved" 95 "Reserved" 96 "Reserved" 97 "Reserved" 98 "Reserved" 99 "Reserved" 100 "Reserved" 0 "Engine" 1 "Auxiliary Power Unit (APU)" 2 "Electric Propulsion Control" 3 "Transmission" 4 "Battery Pack Monitor" 5 "Shift Control/Console" 6 "Power TakeOff - (Main or Rear)" 7 "Axle - Steering" 8 "Axle - Drive" 9 "Brakes - System Controller" 10 "Brakes - Steer Axle" 11 "Brakes - Drive Axle" 12 "Retarder - Engine" 13 "Retarder - Driveline" 14 "Cruise Control" 15 "Fuel System" 16 "Steering Controller" 17 "Suspension - Steer Axle" 18 "Suspension - Drive Axle" 19 "Instrument Cluster" 20 "Trip Recorder" 21 "Cab Climate Control" 22 "Aerodynamic Control" 23 "Vehicle Navigation" 24 "Vehicle Security" 25 "Network Interconnect ECU" 26 "Body Controller" 27 "Power TakeOff (Secondary or Front)" 28 "Off Vehicle Gateway" 29 "Virtual Terminal (in cab)" 30 "Management Computer" 31 "Propulsion Battery Charger" 32 "Headway Controller" 33 "System Monitor" 34 "Hydraulic Pump Controller" 35 "Suspension - System Controller" 36 "Pneumatic - System Controller" 37 "Cab Controller" 38 "Tire Pressure Control" 39 "Ignition Control Module" 40 "Seat Control" 41 "Lighting - Operator Controls" 42 "Water Pump Control" 101 "Reserved" 102 "Reserved" 103 "Reserved" 104 "Reserved" 105 "Reserved" 106 "Reserved" 107 "Reserved" 108 "Reserved" 109 "Reserved" 110 "Reserved" 111 "Reserved" 112 "Reserved" 113 "Reserved" 114 "Reserved" 115 "Reserved" 116 "Reserved" 117 "Reserved" 118 "Reserved" 119 "Reserved" 120 "Reserved" 121 "Reserved" 122 "Reserved" 123 "Reserved" 124 "Reserved" 125 "Reserved" 126 "Reserved" 127 "Reserved" 255 "Not Available" ;
VAL_ 2565799452 ManufacturerCode 1863 "Thomas G. Faria Co." 1862 "Sanshin" 1861 "Vector North America" 1860 "MMP" 1859 "Kvasar AB" 1858 "Litton" 1857 "Simrad" 1856 "Trimble" 1855 "Furuno USA" 1854 "Northstar Technologies" 1853 "Japan Radio Co." 1852 "Navionics" 1851 "Raymarine" 1850 "Teleflex" 222 "Generac Power Systems, Inc." 221 "SiE" 220 "Beede Electrical Instrument Company, Inc." 219 "Cat OEM Solutions" 218 "Gits Manufacturing Company" 217 "RM Michaelides Software & Elektronik GmbH" 216 "Paneltronics Inc." 215 "Aetna Engineering/Fireboy-Xintex" 214 "MC elettronica Srl" 213 "CNH Belgium N.V." 212 "Sure Power Industries, Inc." 211 "DNA Group" 210 "Iteris, Inc." 209 "Bell Equip. Co. SA (PTY) LTD" 208 "Drew Technologies, Inc." 207 "Otto Engineering" 206 "port GmbH" 205 "SmarTire Systems Inc" 204 "The Morey Corporation" 203 "MILtronik GmbH" 202 "Curtis Instruments, Inc." 201 "Disenos y Tecnologia S.A." 200 "MGM Brakes" 199 "Actia Corp." 198 "Mystic Valley Communications" 197 "Mechron Power Systems" 196 "LEMKEN GmbH & Co. KG" 195 "General Engine Products" 194 "TriMark Corporation" 193 "Jeppesen Marine" 192 "Floscan" 191 "XATA Corporation" 190 "Hella KGaA Hueck & Co." 189 "QUALCOMM" 188 "EMP Corp." 187 "Air-Weigh" 186 "Altronic, Inc." 185 "Beede Electrical Instrument Company" 184 "EIA Electronics" 183 "KDS Controls, Inc." 182 "Vehicle Systems Engineering B.V." 181 "Coretronics, Inc." 180 "Smart Power Systems" 179 "Midwest Technologies Illinois, LLC" 178 "Siemens VDO Automotive AG" 177 "Diagnostic System Associates" 176 "Moritz Aerospace" 175 "Veris Technologies, Inc." 174 "AB Volvo Penta" 173 "Ryeso, Inc." 172 "Yanmar Marine USA" 171 "Wachendorff Elektronik GmbH & Co. KG" 170 "Computronics Corporation Ltd." 169 "Marlin Technologies Inc." 168 "Xantrex" 167 "JLG Industries Inc." 166 "Phoenix International" 165 "CPAC Systems AB" 164 "DaimlerChrysler Off-Highway" 163 "BRP Inc." 162 "Axiomatic Technologies" 161 "Offshore Systems (UK) Limited" 160 "Nido" 159 "NTech Industries Inc." 158 "Firestone Industrial Products Company" 157 "ISSPRO Inc." 156 "ITT Industries - Cannon" 155 "Vetronix Corporation" 154 "Westerbeke Corporation" 153 "Woodward, Industrial Controls Division" 152 "Elobau Elektrobauelemente GmbH & Co. KG" 151 "Raven Industries Inc. - Flow Controls Division" 150 "Fleetguard" 149 "Holset" 148 "Blue Water Data, Inc." 147 "Nautibus Electronic GmbH" 146 "Maxima Technologies" 145 "MurCal Controls" 144 "Mercury Marine" 143 "W. Gmeiner GmbH & Co." 142 "TRW Automotive (Commercial Steering Systems)" 141 "Thales Navigation Ltd." 140 "Lowrance Electronics, Inc." 139 "Caterpillar Trimble Control Technologies (CTCT), LLC" 138 "Georg Fritzmeier GmbH & Co. KG" 137 "Maretron" 136 "Komatsu Ltd." 135 "Airmar Technology Corporation" 134 "Iris Technology Ltd." 133 "Bucher Schoerling GmbH" 132 "Mulag-Fahrzeugwerk" 131 "ITT Industries" 130 "Nido - Universal Machines B.V." 129 "OMNEX Control Systems, Inc." 128 "Gerhard Duecker GmbH & Co. KG" 127 "Holland USA" 126 "Driver Tech" 125 "Nevada Automotive Test Center" 124 "Hydac Electronic" 123 "Basler Electric" 122 "FG Wilson (Engineering) Limited" 121 "HED (Hydro Electronic Devices, Inc.)" 120 "RDS Technology Ltd." 119 "IntegriNautics" 118 "Intron GmbH" 117 "HUSCO International" 116 "BEELINE Technologies" 115 "NACCO Materials Handling Group, Inc." 114 "EControls, Inc." 113 "Stress-Tek, Inc." 112 "MECALAC" 111 "Maschinenfabrik Bernhard Krone GmbH" 110 "EPIQ Sensor-Nite" 109 "LH Technologies ApS" 108 "WTK-Elecktronik GmbH" 107 "Grimme Landmaschinen GmbH & Co. KG" 106 "BAE Systems Controls, Inc." 105 "Kiepe Elektrik GmbH & Co. KG" 104 "Claas Selbstfahrende Erntemaschinen GmbH" 103 "Agrocom GmbH & Co. Agrarsystem KG" 102 "AGCO GmbH & Co." 101 "Sensoria" 100 "VDO Technik AG" 99 "International Transmissions Ltd (ITL)" 98 "Mueller-Elektronik GmbH & Co." 97 "Ag Leader Technology, Inc." 96 "Mech@tronic IT GmbH" 95 "Pacific Insight Electronics Corp." 94 "CNH Global N.V." 93 "Perkins Engines Company Ltd." 92 "Ag-Chem Equipment Co., Inc." 91 "BSG Bodensee Steuergeraete GmbH" 90 "Knorr-Bremse SfN GmbH" 89 "Kverneland Group, Electronics Division" 88 "Satloc Precision GPS" 87 "J.C. Bamford Excavators Ltd (JCB)" 86 "C.E. Niehoff & Company" 85 "Kohler Co." 84 "New Holland UK Limited" 83 "Eaton VORAD Technologies" 82 "Bobcat/Ingersoll-Rand" 81 "Fire Research Corp" 80 "Twin Disc, Inc." 79 "Daimler Benz AG - Engine Division (PBM)" 78 "Frank W. Murphy Manufacturing, Inc." 77 "Deere Power Systems Group" 76 "unused" 75 "Deere & Co. Agricultural Division" 74 "Eaton Axle-Brake Division" 73 "LeTourneau, Inc." 72 "Sisu Corporation" 71 "Vansco Electronics Ltd." 70 "Flex-Coil Limited" 69 "Trimble Navigation" 68 "Scania" 67 "Funk Manufacturing Company" 66 "John Deere Construction Equipment Division" 65 "MAN Nutzfahrzeuge AG" 64 "unused" 63 "ZF Industries Inc." 62 "Wabco" 61 "Volvo Truck Corp." 60 "Volvo Trucks North America Inc." 59 "VES Inc." 58 "SPX Corporation, OTC Division" 57 "Sauer-Danfoss Co." 56 "SAIC" 55 "Ryder System Inc." 54 "Meritor Wabco" 53 "Rockwell Land Transportation" 52 "Meritor Automotive, Inc." 51 "Robert Bosch GmbH" 50 "Robert Bosch Corp" 49 "RE America Inc." 48 "Pollak Alphabet" 47 "Phillips Semiconductor" 46 "Parasoft Computing Solutions" 45 "PACCAR" 44 "Nippondenso Co. Ltd." 43 "International Truck and Engine Corp. Vehicle Electronics" 42 "International Truck and Engine Corp. Engine Electronics" 41 "Motorola Inc." 40 "Motorola AIEG Inc." 39 "Microfirm Inc." 38 "Micro Processor Systems Inc." 37 "Mack Trucks Inc." 36 "Lucas Ltd." 35 "Kenworth Truck Co." 34 "Kelsey Hayes Co." 33 "John Deere" 32 "Jacobs Vehicle Systems" 31 "J Pollak Corp." 30 "Isuzu Motors Ltd." 29 "Hino Motors Ltd." 28 "Grote Ind. Inc." 27 "GMC" 26 "General Motors Corp., Service Technology Group" 25 "Freightliner LLC" 24 "Ford Motor Co., Vehicle Controls" 23 "Ford Motor Co., Heavy Truck" 22 "Ford Motor Co., Electronic Concepts $ Systems" 21 "Echilin Inc., Midland Brake Inc." 20 "Eaton Ltd" 19 "Eaton Corp. Trucking Info Services" 18 "Eaton Corp, Transmission Division" 17 "Eaton Corp. Res & Dev" 16 "Eaton Corp." 15 "Dickey-John Corp." 14 "Detroit Diesel Corporation" 13 "Delco Electronics" 12 "Deere & Company, Precision Farming" 11 "Dearborn Group Inc." 10 "Cummins Engine Co." 9 "Chrysler Corp." 8 "Caterpillar Inc." 7 "Case Corp." 6 "Berifors Electronics AB" 5 "AMP Inc." 4 "Ametek-Dixson" 3 "Ametek, US Gauge Division" 2 "Allison Transmission, GMC" 1 "Allied Signal Inc." 0 "Reserved" ;
VAL_ 2565799452 VehicleSystem 0 "Non-specific System" 127 "Not Available" ;
VAL_ 2565799452 VehicleSystem5 127 "Not Available" 0 "Ind. Process Control Stationary" ;
VAL_ 2565799452 VehicleSystem4 100 "Deck/Cargo/Fishing equip. sys" 90 "Environmental (HVAC) Systems" 80 "Instrumentation/General Systems" 70 "Communications Systems" 60 "Navigation Systems" 50 "Propulsion Systems" 40 "Steering Systems" 30 "Power Mgmt and lighting systems" 25 "Gateway" 20 "Safety Systems" 10 "System Tools" 127 "Not Available" 0 "Non-specific System" ;
VAL_ 2565799452 VehicleSystem3 8 "Grader" 7 "Four Wheel Drive Loader" 6 "Forklift" 5 "Excavator" 4 "Crawler" 3 "Backhoe" 2 "Articulated Dump Truck" 1 "Skid Steer Loader" 127 "Not Available" 0 "Non-specific System" ;
VAL_ 2565799452 VehicleSystem2 16 "Skidder" 15 "Earth Work" 14 "Special Crops" 13 "Powered Auxiliary Device" 12 "Farm Yard Operations" 11 "Transport/Trailer" 10 "Irrigation" 9 "Forage" 8 "Root Harvesters" 7 "Harvesters" 6 "Sprayers" 5 "Fertilizers" 4 "Planters/Seeders" 3 "Secondary Tillage" 2 "Tillage" 1 "Tractor" 127 "Not Available" 0 "Non-specific System" ;
VAL_ 2565799452 VehicleSystem1 2 "Trailer" 1 "Tractor" 127 "Not Available" 0 "Non-specific System" ;
VAL_ 2566835198 MalfunctionIndicatorLampStatus 3 "Not available" 2 "Reserved" 1 "Lamp on" 0 "Lamp off" ;
VAL_ 2566835198 RedStopLampState 3 "Not available" 2 "Reserved" 1 "Lamp on" 0 "Lamp off" ;
VAL_ 2566835198 AmberWarningLampStatus 3 "Not available" 2 "Reserved" 1 "Lamp on" 0 "Lamp off" ;
VAL_ 2566835198 ProtectLampStatus 3 "Not available" 2 "Reserved" 1 "Lamp on" 0 "Lamp off" ;
VAL_ 2566835198 FlashRedStopLamp 3 "Unavailable / Do Not Flash" 2 "Reserved" 1 "Fast Flash" 0 "Slow Flash" ;
VAL_ 2566835198 FlashProtectLamp 3 "Unavailable / Do Not Flash" 2 "Reserved" 1 "Fast Flash" 0 "Slow Flash" ;
VAL_ 2566835198 FlashMalfuncIndicatorLamp 3 "Unavailable / Do Not Flash" 2 "Reserved" 1 "Fast Flash" 0 "Slow Flash" ;
VAL_ 2566835198 FlashAmberWarningLamp 3 "Unavailable / Do Not Flash" 2 "Reserved" 1 "Fast Flash" 0 "Slow Flash" ;
VAL_ 2566834942 FlashRedStopLamp 3 "Unavailable / Do Not Flash" 2 "Reserved" 1 "Fast Flash" 0 "Slow Flash" ;
VAL_ 2566834942 FlashProtectLamp 3 "Unavailable / Do Not Flash" 2 "Reserved" 1 "Fast Flash" 0 "Slow Flash" ;
VAL_ 2566834942 FlashMalfuncIndicatorLamp 3 "Unavailable / Do Not Flash" 2 "Reserved" 1 "Fast Flash" 0 "Slow Flash" ;
VAL_ 2566834942 FlashAmberWarningLamp 3 "Unavailable / Do Not Flash" 2 "Reserved" 1 "Fast Flash" 0 "Slow Flash" ;
VAL_ 2566834942 MalfunctionIndicatorLampStatus 3 "Not available" 2 "Reserved" 1 "Lamp on" 0 "Lamp off" ;
VAL_ 2566834942 AmberWarningLampStatus 3 "Not available" 2 "Reserved" 1 "Lamp on" 0 "Lamp off" ;
VAL_ 2566834942 RedStopLampState 3 "Not available" 2 "Reserved" 1 "Lamp on" 0 "Lamp off" ;
VAL_ 2566834942 ProtectLampStatus 3 "Not available" 2 "Reserved" 1 "Lamp on" 0 "Lamp off" ;
VAL_ 2566838526 IndustryGroup 0 "Global" 1 "OnHighway" 2 "AgriculturalAndForestry" 3 "Construction" 4 "Marine" 5 "Reserved" 7 "NotAvailable" ;
VAL_ 2566838526 Function 43 "Transmission Display" 44 "Exhaust Emission Control" 45 "Vehicle Dynamic Stability Control" 46 "Oil Sensor Unit" 47 "Information System Controller" 48 "Ramp Control" 49 "Clutch/Converter Control" 50 "Auxiliary Heater" 51 "Forward-Looking Collision Warning System" 52 "Chassis Controller" 53 "Alternator/Charging System" 54 "Communications Unit, Cellular" 55 "Communications Unit, Satellite" 56 "Communications Unit, Radio" 57 "Steering Column Unit" 58 "Fan Drive Control" 59 "Starter" 60 "Cab Display" 61 "File Server/Printer" 62 "On-Board Diagnostic Unit" 63 "Engine Valve Controller" 64 "Endurance Braking" 65 "Gas Flow Measurement" 66 "I/O Controller" 67 "Electrical System Controller" 68 "Aftertreatment system gas measurement" 69 "Engine Emission Aftertreatement System" 70 "Auxiliary Regeneration Device" 71 "Transfer Case Control" 72 "Coolant Valve Controller" 73 "Rollover Detection Control" 74 "Lubrication System" 75 "Supplemental Fan" 76 "Temperature Sensor" 77 "Fuel Properties Sensor" 78 "Fire Suppression System" 79 "Power Systems Manager" 80 "Electric Powertrain" 81 "Hydraulic Powertrain" 82 "File Server" 83 "Printer" 84 "Start Aid Device" 85 "Engine Injection Control Module" 86 "Reserved" 87 "Reserved" 88 "Reserved" 89 "Reserved" 90 "Reserved" 91 "Reserved" 92 "Reserved" 93 "Reserved" 94 "Reserved" 95 "Reserved" 96 "Reserved" 97 "Reserved" 98 "Reserved" 99 "Reserved" 100 "Reserved" 0 "Engine" 1 "Auxiliary Power Unit (APU)" 2 "Electric Propulsion Control" 3 "Transmission" 4 "Battery Pack Monitor" 5 "Shift Control/Console" 6 "Power TakeOff - (Main or Rear)" 7 "Axle - Steering" 8 "Axle - Drive" 9 "Brakes - System Controller" 10 "Brakes - Steer Axle" 11 "Brakes - Drive Axle" 12 "Retarder - Engine" 13 "Retarder - Driveline" 14 "Cruise Control" 15 "Fuel System" 16 "Steering Controller" 17 "Suspension - Steer Axle" 18 "Suspension - Drive Axle" 19 "Instrument Cluster" 20 "Trip Recorder" 21 "Cab Climate Control" 22 "Aerodynamic Control" 23 "Vehicle Navigation" 24 "Vehicle Security" 25 "Network Interconnect ECU" 26 "Body Controller" 27 "Power TakeOff (Secondary or Front)" 28 "Off Vehicle Gateway" 29 "Virtual Terminal (in cab)" 30 "Management Computer" 31 "Propulsion Battery Charger" 32 "Headway Controller" 33 "System Monitor" 34 "Hydraulic Pump Controller" 35 "Suspension - System Controller" 36 "Pneumatic - System Controller" 37 "Cab Controller" 38 "Tire Pressure Control" 39 "Ignition Control Module" 40 "Seat Control" 41 "Lighting - Operator Controls" 42 "Water Pump Control" 101 "Reserved" 102 "Reserved" 103 "Reserved" 104 "Reserved" 105 "Reserved" 106 "Reserved" 107 "Reserved" 108 "Reserved" 109 "Reserved" 110 "Reserved" 111 "Reserved" 112 "Reserved" 113 "Reserved" 114 "Reserved" 115 "Reserved" 116 "Reserved" 117 "Reserved" 118 "Reserved" 119 "Reserved" 120 "Reserved" 121 "Reserved" 122 "Reserved" 123 "Reserved" 124 "Reserved" 125 "Reserved" 126 "Reserved" 127 "Reserved" 255 "Not Available" ;
VAL_ 2566838526 VehicleSystem 0 "Non-specific System" 127 "Not Available" ;
VAL_ 2566838526 ManufacturerCode 1863 "Thomas G. Faria Co." 1862 "Sanshin" 1861 "Vector North America" 1860 "MMP" 1859 "Kvasar AB" 1858 "Litton" 1857 "Simrad" 1856 "Trimble" 1855 "Furuno USA" 1854 "Northstar Technologies" 1853 "Japan Radio Co." 1852 "Navionics" 1851 "Raymarine" 1850 "Teleflex" 222 "Generac Power Systems, Inc." 221 "SiE" 220 "Beede Electrical Instrument Company, Inc." 219 "Cat OEM Solutions" 218 "Gits Manufacturing Company" 217 "RM Michaelides Software & Elektronik GmbH" 216 "Paneltronics Inc." 215 "Aetna Engineering/Fireboy-Xintex" 214 "MC elettronica Srl" 213 "CNH Belgium N.V." 212 "Sure Power Industries, Inc." 211 "DNA Group" 210 "Iteris, Inc." 209 "Bell Equip. Co. SA (PTY) LTD" 208 "Drew Technologies, Inc." 207 "Otto Engineering" 206 "port GmbH" 205 "SmarTire Systems Inc" 204 "The Morey Corporation" 203 "MILtronik GmbH" 202 "Curtis Instruments, Inc." 201 "Disenos y Tecnologia S.A." 200 "MGM Brakes" 199 "Actia Corp." 198 "Mystic Valley Communications" 197 "Mechron Power Systems" 196 "LEMKEN GmbH & Co. KG" 195 "General Engine Products" 194 "TriMark Corporation" 193 "Jeppesen Marine" 192 "Floscan" 191 "XATA Corporation" 190 "Hella KGaA Hueck & Co." 189 "QUALCOMM" 188 "EMP Corp." 187 "Air-Weigh" 186 "Altronic, Inc." 185 "Beede Electrical Instrument Company" 184 "EIA Electronics" 183 "KDS Controls, Inc." 182 "Vehicle Systems Engineering B.V." 181 "Coretronics, Inc." 180 "Smart Power Systems" 179 "TeeJet Technologies Denmark" 178 "Siemens VDO Automotive AG" 177 "Diagnostic System Associates" 176 "Moritz Aerospace" 175 "Veris Technologies, Inc." 174 "AB Volvo Penta" 173 "Ryeso, Inc." 172 "Yanmar Marine USA" 171 "Wachendorff Elektronik GmbH & Co. KG" 170 "Computronics Corporation Ltd." 169 "Marlin Technologies Inc." 168 "Xantrex" 167 "JLG Industries Inc." 166 "Phoenix International" 165 "CPAC Systems AB" 164 "DaimlerChrysler Off-Highway" 163 "BRP Inc." 162 "Axiomatic Technologies" 161 "Offshore Systems (UK) Limited" 160 "Nido" 159 "NTech Industries Inc." 158 "Firestone Industrial Products Company" 157 "ISSPRO Inc." 156 "ITT Industries - Cannon" 155 "Vetronix Corporation" 154 "Westerbeke Corporation" 153 "Woodward, Industrial Controls Division" 152 "Elobau Elektrobauelemente GmbH & Co. KG" 151 "Raven Industries Inc. - Flow Controls Division" 150 "Fleetguard" 149 "Holset" 148 "Blue Water Data, Inc." 147 "Nautibus Electronic GmbH" 146 "Maxima Technologies" 145 "MurCal Controls" 144 "Mercury Marine" 143 "W. Gmeiner GmbH & Co." 142 "TRW Automotive (Commercial Steering Systems)" 141 "Thales Navigation Ltd." 140 "Lowrance Electronics, Inc." 139 "Caterpillar Trimble Control Technologies (CTCT), LLC" 138 "Georg Fritzmeier GmbH & Co. KG" 137 "Maretron" 136 "Komatsu Ltd." 135 "Airmar Technology Corporation" 134 "Iris Technology Ltd." 133 "Bucher Schoerling GmbH" 132 "Mulag-Fahrzeugwerk" 131 "ITT Industries" 130 "Nido - Universal Machines B.V." 129 "OMNEX Control Systems, Inc." 128 "Gerhard Duecker GmbH & Co. KG" 127 "Holland USA" 126 "Driver Tech" 125 "Nevada Automotive Test Center" 124 "Hydac Electronic" 123 "Basler Electric" 122 "FG Wilson (Engineering) Limited" 121 "HED (Hydro Electronic Devices, Inc.)" 120 "RDS Technology Ltd." 119 "IntegriNautics" 118 "Intron GmbH" 117 "HUSCO International" 116 "BEELINE Technologies" 115 "NACCO Materials Handling Group, Inc." 114 "EControls, Inc." 113 "Stress-Tek, Inc." 112 "MECALAC" 111 "Maschinenfabrik Bernhard Krone GmbH" 110 "EPIQ Sensor-Nite" 109 "TeeJet Technologies Denmark" 108 "WTK-Elecktronik GmbH" 107 "Grimme Landmaschinen GmbH & Co. KG" 106 "BAE Systems Controls, Inc." 105 "Kiepe Elektrik GmbH & Co. KG" 104 "Claas Selbstfahrende Erntemaschinen GmbH" 103 "Agrocom GmbH & Co. Agrarsystem KG" 102 "AGCO GmbH & Co." 101 "Sensoria" 100 "VDO Technik AG" 99 "International Transmissions Ltd (ITL)" 98 "Mueller-Elektronik GmbH & Co." 97 "Ag Leader Technology, Inc." 96 "Mech@tronic IT GmbH" 95 "Pacific Insight Electronics Corp." 94 "CNH Global N.V." 93 "Perkins Engines Company Ltd." 92 "Ag-Chem Equipment Co., Inc." 91 "BSG Bodensee Steuergeraete GmbH" 90 "Knorr-Bremse SfN GmbH" 89 "Kverneland Group, Electronics Division" 88 "Satloc Precision GPS" 87 "J.C. Bamford Excavators Ltd (JCB)" 86 "C.E. Niehoff & Company" 85 "Kohler Co." 84 "New Holland UK Limited" 83 "Eaton VORAD Technologies" 82 "Bobcat/Ingersoll-Rand" 81 "Fire Research Corp" 80 "Twin Disc, Inc." 79 "Daimler Benz AG - Engine Division (PBM)" 78 "Frank W. Murphy Manufacturing, Inc." 77 "Deere Power Systems Group" 76 "unused" 75 "Deere & Co. Agricultural Division" 74 "Eaton Axle-Brake Division" 73 "LeTourneau, Inc." 72 "Sisu Corporation" 71 "Vansco Electronics Ltd." 70 "Flex-Coil Limited" 69 "Trimble Navigation" 68 "Scania" 67 "Funk Manufacturing Company" 66 "John Deere Construction Equipment Division" 65 "MAN Nutzfahrzeuge AG" 64 "unused" 63 "ZF Industries Inc." 62 "Wabco" 61 "Volvo Truck Corp." 60 "Volvo Trucks North America Inc." 59 "VES Inc." 58 "SPX Corporation, OTC Division" 57 "Sauer-Danfoss Co." 56 "SAIC" 55 "Ryder System Inc." 54 "Meritor Wabco" 53 "Rockwell Land Transportation" 52 "Meritor Automotive, Inc." 51 "Robert Bosch GmbH" 50 "Robert Bosch Corp" 49 "RE America Inc." 48 "Pollak Alphabet" 47 "Phillips Semiconductor" 46 "Parasoft Computing Solutions" 45 "PACCAR" 44 "Nippondenso Co. Ltd." 43 "International Truck and Engine Corp. Vehicle Electronics" 42 "International Truck and Engine Corp. Engine Electronics" 41 "Motorola Inc." 40 "Motorola AIEG Inc." 39 "Microfirm Inc." 38 "Micro Processor Systems Inc." 37 "Mack Trucks Inc." 36 "Lucas Ltd." 35 "Kenworth Truck Co." 34 "Kelsey Hayes Co." 33 "John Deere" 32 "Jacobs Vehicle Systems" 31 "J Pollak Corp." 30 "Isuzu Motors Ltd." 29 "Hino Motors Ltd." 28 "Grote Ind. Inc." 27 "GMC" 26 "General Motors Corp., Service Technology Group" 25 "Freightliner LLC" 24 "Ford Motor Co., Vehicle Controls" 23 "Ford Motor Co., Heavy Truck" 22 "Ford Motor Co., Electronic Concepts $ Systems" 21 "Echilin Inc., Midland Brake Inc." 20 "Eaton Ltd" 19 "Eaton Corp. Trucking Info Services" 18 "Eaton Corp, Transmission Division" 17 "Eaton Corp. Res & Dev" 16 "Eaton Corp." 15 "Dickey-John Corp." 14 "Detroit Diesel Corporation" 13 "Delco Electronics" 12 "Deere & Company, Precision Farming" 11 "Dearborn Group Inc." 10 "Cummins Engine Co." 9 "Chrysler Corp." 8 "Caterpillar Inc." 7 "Case Corp." 6 "Berifors Electronics AB" 5 "AMP Inc." 4 "Ametek-Dixson" 3 "Ametek, US Gauge Division" 2 "Allison Transmission, GMC" 1 "Allied Signal Inc." 0 "Reserved" ;
VAL_ 2566838526 VehicleSystem5 127 "Not Available" 0 "Ind. Process Control Stationary" ;
VAL_ 2566838526 VehicleSystem4 100 "Deck/Cargo/Fishing equip. sys" 90 "Environmental (HVAC) Systems" 80 "Instrumentation/General Systems" 70 "Communications Systems" 60 "Navigation Systems" 50 "Propulsion Systems" 40 "Steering Systems" 30 "Power Mgmt and lighting systems" 25 "Gateway" 20 "Safety Systems" 10 "System Tools" 127 "Not Available" 0 "Non-specific System" ;
VAL_ 2566838526 VehicleSystem3 8 "Grader" 7 "Four Wheel Drive Loader" 6 "Forklift" 5 "Excavator" 4 "Crawler" 3 "Backhoe" 2 "Articulated Dump Truck" 1 "Skid Steer Loader" 127 "Not Available" 0 "Non-specific System" ;
VAL_ 2566838526 VehicleSystem2 16 "Skidder" 15 "Earth Work" 14 "Special Crops" 13 "Powered Auxiliary Device" 12 "Farm Yard Operations" 11 "Transport/Trailer" 10 "Irrigation" 9 "Forage" 8 "Root Harvesters" 7 "Harvesters" 6 "Sprayers" 5 "Fertilizers" 4 "Planters/Seeders" 3 "Secondary Tillage" 2 "Tillage" 1 "Tractor" 127 "Not Available" 0 "Non-specific System" ;
VAL_ 2566838526 VehicleSystem1 2 "Trailer" 1 "Tractor" 127 "Not Available" 0 "Non-specific System" ;
VAL_ 2565799678 IndustryGroup 0 "Global" 1 "OnHighway" 2 "AgriculturalAndForestry" 3 "Construction" 4 "Marine" 5 "Reserved" 7 "NotAvailable" ;
VAL_ 2565799678 Function 43 "Transmission Display" 44 "Exhaust Emission Control" 45 "Vehicle Dynamic Stability Control" 46 "Oil Sensor Unit" 47 "Information System Controller" 48 "Ramp Control" 49 "Clutch/Converter Control" 50 "Auxiliary Heater" 51 "Forward-Looking Collision Warning System" 52 "Chassis Controller" 53 "Alternator/Charging System" 54 "Communications Unit, Cellular" 55 "Communications Unit, Satellite" 56 "Communications Unit, Radio" 57 "Steering Column Unit" 58 "Fan Drive Control" 59 "Starter" 60 "Cab Display" 61 "File Server/Printer" 62 "On-Board Diagnostic Unit" 63 "Engine Valve Controller" 64 "Endurance Braking" 65 "Gas Flow Measurement" 66 "I/O Controller" 67 "Electrical System Controller" 68 "Aftertreatment system gas measurement" 69 "Engine Emission Aftertreatement System" 70 "Auxiliary Regeneration Device" 71 "Transfer Case Control" 72 "Coolant Valve Controller" 73 "Rollover Detection Control" 74 "Lubrication System" 75 "Supplemental Fan" 76 "Temperature Sensor" 77 "Fuel Properties Sensor" 78 "Fire Suppression System" 79 "Power Systems Manager" 80 "Electric Powertrain" 81 "Hydraulic Powertrain" 82 "File Server" 83 "Printer" 84 "Start Aid Device" 85 "Engine Injection Control Module" 86 "Reserved" 87 "Reserved" 88 "Reserved" 89 "Reserved" 90 "Reserved" 91 "Reserved" 92 "Reserved" 93 "Reserved" 94 "Reserved" 95 "Reserved" 96 "Reserved" 97 "Reserved" 98 "Reserved" 99 "Reserved" 100 "Reserved" 0 "Engine" 1 "Auxiliary Power Unit (APU)" 2 "Electric Propulsion Control" 3 "Transmission" 4 "Battery Pack Monitor" 5 "Shift Control/Console" 6 "Power TakeOff - (Main or Rear)" 7 "Axle - Steering" 8 "Axle - Drive" 9 "Brakes - System Controller" 10 "Brakes - Steer Axle" 11 "Brakes - Drive Axle" 12 "Retarder - Engine" 13 "Retarder - Driveline" 14 "Cruise Control" 15 "Fuel System" 16 "Steering Controller" 17 "Suspension - Steer Axle" 18 "Suspension - Drive Axle" 19 "Instrument Cluster" 20 "Trip Recorder" 21 "Cab Climate Control" 22 "Aerodynamic Control" 23 "Vehicle Navigation" 24 "Vehicle Security" 25 "Network Interconnect ECU" 26 "Body Controller" 27 "Power TakeOff (Secondary or Front)" 28 "Off Vehicle Gateway" 29 "Virtual Terminal (in cab)" 30 "Management Computer" 31 "Propulsion Battery Charger" 32 "Headway Controller" 33 "System Monitor" 34 "Hydraulic Pump Controller" 35 "Suspension - System Controller" 36 "Pneumatic - System Controller" 37 "Cab Controller" 38 "Tire Pressure Control" 39 "Ignition Control Module" 40 "Seat Control" 41 "Lighting - Operator Controls" 42 "Water Pump Control" 101 "Reserved" 102 "Reserved" 103 "Reserved" 104 "Reserved" 105 "Reserved" 106 "Reserved" 107 "Reserved" 108 "Reserved" 109 "Reserved" 110 "Reserved" 111 "Reserved" 112 "Reserved" 113 "Reserved" 114 "Reserved" 115 "Reserved" 116 "Reserved" 117 "Reserved" 118 "Reserved" 119 "Reserved" 120 "Reserved" 121 "Reserved" 122 "Reserved" 123 "Reserved" 124 "Reserved" 125 "Reserved" 126 "Reserved" 127 "Reserved" 255 "Not Available" ;
VAL_ 2565799678 ManufacturerCode 1863 "Thomas G. Faria Co." 1862 "Sanshin" 1861 "Vector North America" 1860 "MMP" 1859 "Kvasar AB" 1858 "Litton" 1857 "Simrad" 1856 "Trimble" 1855 "Furuno USA" 1854 "Northstar Technologies" 1853 "Japan Radio Co." 1852 "Navionics" 1851 "Raymarine" 1850 "Teleflex" 222 "Generac Power Systems, Inc." 221 "SiE" 220 "Beede Electrical Instrument Company, Inc." 219 "Cat OEM Solutions" 218 "Gits Manufacturing Company" 217 "RM Michaelides Software & Elektronik GmbH" 216 "Paneltronics Inc." 215 "Aetna Engineering/Fireboy-Xintex" 214 "MC elettronica Srl" 213 "CNH Belgium N.V." 212 "Sure Power Industries, Inc." 211 "DNA Group" 210 "Iteris, Inc." 209 "Bell Equip. Co. SA (PTY) LTD" 208 "Drew Technologies, Inc." 207 "Otto Engineering" 206 "port GmbH" 205 "SmarTire Systems Inc" 204 "The Morey Corporation" 203 "MILtronik GmbH" 202 "Curtis Instruments, Inc." 201 "Disenos y Tecnologia S.A." 200 "MGM Brakes" 199 "Actia Corp." 198 "Mystic Valley Communications" 197 "Mechron Power Systems" 196 "LEMKEN GmbH & Co. KG" 195 "General Engine Products" 194 "TriMark Corporation" 193 "Jeppesen Marine" 192 "Floscan" 191 "XATA Corporation" 190 "Hella KGaA Hueck & Co." 189 "QUALCOMM" 188 "EMP Corp." 187 "Air-Weigh" 186 "Altronic, Inc." 185 "Beede Electrical Instrument Company" 184 "EIA Electronics" 183 "KDS Controls, Inc." 182 "Vehicle Systems Engineering B.V." 181 "Coretronics, Inc." 180 "Smart Power Systems" 179 "TeeJet Technologies Denmark" 178 "Siemens VDO Automotive AG" 177 "Diagnostic System Associates" 176 "Moritz Aerospace" 175 "Veris Technologies, Inc." 174 "AB Volvo Penta" 173 "Ryeso, Inc." 172 "Yanmar Marine USA" 171 "Wachendorff Elektronik GmbH & Co. KG" 170 "Computronics Corporation Ltd." 169 "Marlin Technologies Inc." 168 "Xantrex" 167 "JLG Industries Inc." 166 "Phoenix International" 165 "CPAC Systems AB" 164 "DaimlerChrysler Off-Highway" 163 "BRP Inc." 162 "Axiomatic Technologies" 161 "Offshore Systems (UK) Limited" 160 "Nido" 159 "NTech Industries Inc." 158 "Firestone Industrial Products Company" 157 "ISSPRO Inc." 156 "ITT Industries - Cannon" 155 "Vetronix Corporation" 154 "Westerbeke Corporation" 153 "Woodward, Industrial Controls Division" 152 "Elobau Elektrobauelemente GmbH & Co. KG" 151 "Raven Industries Inc. - Flow Controls Division" 150 "Fleetguard" 149 "Holset" 148 "Blue Water Data, Inc." 147 "Nautibus Electronic GmbH" 146 "Maxima Technologies" 145 "MurCal Controls" 144 "Mercury Marine" 143 "W. Gmeiner GmbH & Co." 142 "TRW Automotive (Commercial Steering Systems)" 141 "Thales Navigation Ltd." 140 "Lowrance Electronics, Inc." 139 "Caterpillar Trimble Control Technologies (CTCT), LLC" 138 "Georg Fritzmeier GmbH & Co. KG" 137 "Maretron" 136 "Komatsu Ltd." 135 "Airmar Technology Corporation" 134 "Iris Technology Ltd." 133 "Bucher Schoerling GmbH" 132 "Mulag-Fahrzeugwerk" 131 "ITT Industries" 130 "Nido - Universal Machines B.V." 129 "OMNEX Control Systems, Inc." 128 "Gerhard Duecker GmbH & Co. KG" 127 "Holland USA" 126 "Driver Tech" 125 "Nevada Automotive Test Center" 124 "Hydac Electronic" 123 "Basler Electric" 122 "FG Wilson (Engineering) Limited" 121 "HED (Hydro Electronic Devices, Inc.)" 120 "RDS Technology Ltd." 119 "IntegriNautics" 118 "Intron GmbH" 117 "HUSCO International" 116 "BEELINE Technologies" 115 "NACCO Materials Handling Group, Inc." 114 "EControls, Inc." 113 "Stress-Tek, Inc." 112 "MECALAC" 111 "Maschinenfabrik Bernhard Krone GmbH" 110 "EPIQ Sensor-Nite" 109 "TeeJet Technologies Denmark" 108 "WTK-Elecktronik GmbH" 107 "Grimme Landmaschinen GmbH & Co. KG" 106 "BAE Systems Controls, Inc." 105 "Kiepe Elektrik GmbH & Co. KG" 104 "Claas Selbstfahrende Erntemaschinen GmbH" 103 "Agrocom GmbH & Co. Agrarsystem KG" 102 "AGCO GmbH & Co." 101 "Sensoria" 100 "VDO Technik AG" 99 "International Transmissions Ltd (ITL)" 98 "Mueller-Elektronik GmbH & Co." 97 "Ag Leader Technology, Inc." 96 "Mech@tronic IT GmbH" 95 "Pacific Insight Electronics Corp." 94 "CNH Global N.V." 93 "Perkins Engines Company Ltd." 92 "Ag-Chem Equipment Co., Inc." 91 "BSG Bodensee Steuergeraete GmbH" 90 "Knorr-Bremse SfN GmbH" 89 "Kverneland Group, Electronics Division" 88 "Satloc Precision GPS" 87 "J.C. Bamford Excavators Ltd (JCB)" 86 "C.E. Niehoff & Company" 85 "Kohler Co." 84 "New Holland UK Limited" 83 "Eaton VORAD Technologies" 82 "Bobcat/Ingersoll-Rand" 81 "Fire Research Corp" 80 "Twin Disc, Inc." 79 "Daimler Benz AG - Engine Division (PBM)" 78 "Frank W. Murphy Manufacturing, Inc." 77 "Deere Power Systems Group" 76 "unused" 75 "Deere & Co. Agricultural Division" 74 "Eaton Axle-Brake Division" 73 "LeTourneau, Inc." 72 "Sisu Corporation" 71 "Vansco Electronics Ltd." 70 "Flex-Coil Limited" 69 "Trimble Navigation" 68 "Scania" 67 "Funk Manufacturing Company" 66 "John Deere Construction Equipment Division" 65 "MAN Nutzfahrzeuge AG" 64 "unused" 63 "ZF Industries Inc." 62 "Wabco" 61 "Volvo Truck Corp." 60 "Volvo Trucks North America Inc." 59 "VES Inc." 58 "SPX Corporation, OTC Division" 57 "Sauer-Danfoss Co." 56 "SAIC" 55 "Ryder System Inc." 54 "Meritor Wabco" 53 "Continental Automotive Systems US, Inc." 52 "Meritor Automotive, Inc." 51 "Robert Bosch GmbH" 50 "Robert Bosch Corp" 49 "RE America Inc." 48 "Pollak Alphabet" 47 "Phillips Semiconductor" 46 "Parasoft Computing Solutions" 45 "PACCAR" 44 "Nippondenso Co. Ltd." 43 "International Truck and Engine Corp. Vehicle Electronics" 42 "International Truck and Engine Corp. Engine Electronics" 41 "Motorola Inc." 40 "Motorola AIEG Inc." 39 "Microfirm Inc." 38 "Micro Processor Systems Inc." 37 "Mack Trucks Inc." 36 "Lucas Ltd." 35 "Kenworth Truck Co." 34 "Kelsey Hayes Co." 33 "John Deere" 32 "Jacobs Vehicle Systems" 31 "J Pollak Corp." 30 "Isuzu Motors Ltd." 29 "Hino Motors Ltd." 28 "Grote Ind. Inc." 27 "GMC" 26 "General Motors Corp., Service Technology Group" 25 "Daimler Trucks North America LLC" 24 "Ford Motor Co., Vehicle Controls" 23 "Ford Motor Co., Heavy Truck" 22 "Ford Motor Co., Electronic Concepts $ Systems" 21 "Echilin Inc., Midland Brake Inc." 20 "Eaton Ltd" 19 "Eaton Corp. Trucking Info Services" 18 "Eaton Corp, Transmission Division" 17 "Eaton Corp. Res & Dev" 16 "Eaton Corp." 15 "Dickey-John Corp." 14 "Detroit Diesel Corporation" 13 "Delco Electronics" 12 "Deere & Company, Precision Farming" 11 "Dearborn Group Inc." 10 "Cummins Engine Co." 9 "Chrysler Corp." 8 "Caterpillar Inc." 7 "Case Corp." 6 "Berifors Electronics AB" 5 "AMP Inc." 4 "Ametek-Dixson" 3 "Ametek, US Gauge Division" 2 "Allison Transmission, GMC" 1 "Allied Signal Inc." 0 "Reserved" ;
VAL_ 2565799678 VehicleSystem 0 "Non-specific System" 127 "Not Available" ;
VAL_ 2565799678 VehicleSystem5 127 "Not Available" 0 "Ind. Process Control Stationary" ;
VAL_ 2565799678 VehicleSystem4 100 "Deck/Cargo/Fishing equip. sys" 90 "Environmental (HVAC) Systems" 80 "Instrumentation/General Systems" 70 "Communications Systems" 60 "Navigation Systems" 50 "Propulsion Systems" 40 "Steering Systems" 30 "Power Mgmt and lighting systems" 25 "Gateway" 20 "Safety Systems" 10 "System Tools" 127 "Not Available" 0 "Non-specific System" ;
VAL_ 2565799678 VehicleSystem3 8 "Grader" 7 "Four Wheel Drive Loader" 6 "Forklift" 5 "Excavator" 4 "Crawler" 3 "Backhoe" 2 "Articulated Dump Truck" 1 "Skid Steer Loader" 127 "Not Available" 0 "Non-specific System" ;
VAL_ 2565799678 VehicleSystem2 16 "Skidder" 15 "Earth Work" 14 "Special Crops" 13 "Powered Auxiliary Device" 12 "Farm Yard Operations" 11 "Transport/Trailer" 10 "Irrigation" 9 "Forage" 8 "Root Harvesters" 7 "Harvesters" 6 "Sprayers" 5 "Fertilizers" 4 "Planters/Seeders" 3 "Secondary Tillage" 2 "Tillage" 1 "Tractor" 127 "Not Available" 0 "Non-specific System" ;
VAL_ 2565799678 VehicleSystem1 2 "Trailer" 1 "Tractor" 127 "Not Available" 0 "Non-specific System" ;
SG_MUL_VAL_ 2362179326 ErrorElementNumber Command 13-13;
SG_MUL_VAL_ 2362179326 ErrorDDI Command 13-13;
SG_MUL_VAL_ 2362179326 ErrorCodeProcessData6 Command 13-13;
SG_MUL_VAL_ 2362179326 ErrorCodeProcessData5 Command 13-13;
SG_MUL_VAL_ 2362179326 ErrorCodeProcessData4 Command 13-13;
SG_MUL_VAL_ 2362179326 ErrorCodeProcessData3 Command 13-13;
SG_MUL_VAL_ 2362179326 ErrorCodeProcessData2 Command 13-13;
SG_MUL_VAL_ 2362179326 ErrorCodeProcessData1 Command 13-13;
SG_MUL_VAL_ 2362179326 Status_TotalsActive Command 15-15;
SG_MUL_VAL_ 2362179326 ExecutedCommand Command 14-14;
SG_MUL_VAL_ 2362179326 SourceAddressWSM Command 14-14;
SG_MUL_VAL_ 2362179326 StatusBusyExecuting Command 14-14;
SG_MUL_VAL_ 2362179326 StatusBusyReading Command 14-14;
SG_MUL_VAL_ 2362179326 StatusBusySaving Command 14-14;
SG_MUL_VAL_ 2362179326 StatusTotalsActive Command 14-14;
SG_MUL_VAL_ 2362179326 ObjectIdChanged DeviceDescriptionMsgType 13-13;
SG_MUL_VAL_ 2362179326 DesignatorLength DeviceDescriptionMsgType 12-12;
SG_MUL_VAL_ 2362179326 ObjectIdToChange DeviceDescriptionMsgType 12-12;
SG_MUL_VAL_ 2362179326 ErrorCodeChangeDesignator DeviceDescriptionMsgType 13-13;
SG_MUL_VAL_ 2362179326 ErrorCodeObjectPoolDelete DeviceDescriptionMsgType 11-11;
SG_MUL_VAL_ 2362179326 ErrorCodeObjPool4 DeviceDescriptionMsgType 9-9;
SG_MUL_VAL_ 2362179326 ErrorCodeObjPool3 DeviceDescriptionMsgType 9-9;
SG_MUL_VAL_ 2362179326 ErrorCodeObjPool2 DeviceDescriptionMsgType 9-9;
SG_MUL_VAL_ 2362179326 ErrorCodeObjPool1 DeviceDescriptionMsgType 9-9;
SG_MUL_VAL_ 2362179326 ErrorCodeObjPoolActiveResp3 DeviceDescriptionMsgType 9-9;
SG_MUL_VAL_ 2362179326 ErrorCodeObjPoolActiveResp2 DeviceDescriptionMsgType 9-9;
SG_MUL_VAL_ 2362179326 ErrorCodeObjPoolActiveResp1 DeviceDescriptionMsgType 9-9;
SG_MUL_VAL_ 2362179326 ObjectIdOfFaultyObject DeviceDescriptionMsgType 9-9;
SG_MUL_VAL_ 2362179326 ParentObjectIdOfFaultyObject DeviceDescriptionMsgType 9-9;
SG_MUL_VAL_ 2362179326 ReceivedDataSize DeviceDescriptionMsgType 7-7;
SG_MUL_VAL_ 2362179326 ErrorCodeObjPoolTransfer DeviceDescriptionMsgType 7-7;
SG_MUL_VAL_ 2362179326 Status DeviceDescriptionMsgType 5-5;
SG_MUL_VAL_ 2362179326 RequestTransferDataSize DeviceDescriptionMsgType 4-4;
SG_MUL_VAL_ 2362179326 TemperatureUnits DeviceDescriptionMsgType 2-2, 3-3;
SG_MUL_VAL_ 2362179326 PressureUnits DeviceDescriptionMsgType 2-2, 3-3;
SG_MUL_VAL_ 2362179326 ForceUnits DeviceDescriptionMsgType 2-2, 3-3;
SG_MUL_VAL_ 2362179326 UnitsSystem DeviceDescriptionMsgType 2-2, 3-3;
SG_MUL_VAL_ 2362179326 DistanceUnitCmd DeviceDescriptionMsgType 2-2, 3-3;
SG_MUL_VAL_ 2362179326 AreaUnitCmd DeviceDescriptionMsgType 2-2, 3-3;
SG_MUL_VAL_ 2362179326 VolumeUnitCmd DeviceDescriptionMsgType 2-2, 3-3;
SG_MUL_VAL_ 2362179326 MassUnitCmd DeviceDescriptionMsgType 2-2, 3-3;
SG_MUL_VAL_ 2362179326 DateFormatCmd DeviceDescriptionMsgType 2-2, 3-3;
SG_MUL_VAL_ 2362179326 DecimalSymbolCmd DeviceDescriptionMsgType 2-2, 3-3;
SG_MUL_VAL_ 2362179326 TimeFormatCmd DeviceDescriptionMsgType 2-2, 3-3;
SG_MUL_VAL_ 2362179326 LanguageCodeCmd DeviceDescriptionMsgType 2-2, 3-3;
SG_MUL_VAL_ 2362179326 StructureLabel DeviceDescriptionMsgType 1-1;
SG_MUL_VAL_ 2362179326 DeviceDescriptionMsgType Command 1-1;
SG_MUL_VAL_ 2362179326 VersionNumberISO11783Part10 TechnicalDataMsgType 1-1;
SG_MUL_VAL_ 2362179326 TechnicalDataMsgType Command 0-0;
SG_MUL_VAL_ 2362179326 ElementNumber Command 2-8;
SG_MUL_VAL_ 2362179326 DDI Command 2-8;
SG_MUL_VAL_ 2362179326 MinMassPerAreaAppRate DDI 152-152;
SG_MUL_VAL_ 2362179326 DataDictionaryVersion DDI 0-0;
SG_MUL_VAL_ 2362179326 RequestDefaultProcessData DDI 57343-57343;
SG_MUL_VAL_ 2362179326 AreaPerTimeCapacity DDI 151-151;
SG_MUL_VAL_ 2362179326 FuelConsumptionPerArea DDI 150-150;
SG_MUL_VAL_ 2362179326 FuelConsumptionPerTime DDI 149-149;
SG_MUL_VAL_ 2362179326 TotalFuelConsumption DDI 148-148;
SG_MUL_VAL_ 2362179326 LogCount DDI 147-147;
SG_MUL_VAL_ 2362179326 PitchAngle DDI 146-146;
SG_MUL_VAL_ 2362179326 RollAngle DDI 145-145;
SG_MUL_VAL_ 2362179326 YawAngle DDI 144-144;
SG_MUL_VAL_ 2362179326 ActualValueTimeLatency DDI 143-143;
SG_MUL_VAL_ 2362179326 SetpointTimeLatency DDI 142-142;
SG_MUL_VAL_ 2362179326 WorkState DDI 141-141;
SG_MUL_VAL_ 2362179326 PercentageAppRateSetpoint DDI 140-140;
SG_MUL_VAL_ 2362179326 DeviceCountCapacity DDI 139-139;
SG_MUL_VAL_ 2362179326 DeviceMassCapacity DDI 138-138;
SG_MUL_VAL_ 2362179326 DeviceVolumeCapacity DDI 137-137;
SG_MUL_VAL_ 2362179326 DeviceElementOffsetZ DDI 136-136;
SG_MUL_VAL_ 2362179326 DeviceElementOffsetY DDI 135-135;
SG_MUL_VAL_ 2362179326 DeviceElementOffsetX DDI 134-134;
SG_MUL_VAL_ 2362179326 AuxiliaryValveInvertPorts DDI 133-133;
SG_MUL_VAL_ 2362179326 AuxiliaryValveProgressivRetract DDI 132-132;
SG_MUL_VAL_ 2362179326 AuxiliaryValveProgressivExtend DDI 131-131;
SG_MUL_VAL_ 2362179326 AuxiliaryValveFloatThreshold DDI 130-130;
SG_MUL_VAL_ 2362179326 AuxiliaryValveRampRetractDown DDI 129-129;
SG_MUL_VAL_ 2362179326 AuxiliaryValveRampRetractUp DDI 128-128;
SG_MUL_VAL_ 2362179326 AuxiliaryValveRampExtendDown DDI 127-127;
SG_MUL_VAL_ 2362179326 AuxiliaryValveScalingRetract DDI 125-125;
SG_MUL_VAL_ 2362179326 AuxiliaryValveScalingExtend DDI 124-124;
SG_MUL_VAL_ 2362179326 AuxiliaryRampExtendUp DDI 126-126;
SG_MUL_VAL_ 2362179326 AppRateVolumePerArea_Set DDI 1-1;
SG_MUL_VAL_ 2362179326 AppRateVolumePerArea_Act DDI 2-2;
SG_MUL_VAL_ 2362179326 AppRateVolumePerArea_Def DDI 3-3;
SG_MUL_VAL_ 2362179326 AppRateVolumePerArea_Min DDI 4-4;
SG_MUL_VAL_ 2362179326 AppRateVolumePerArea_Max DDI 5-5;
SG_MUL_VAL_ 2362179326 AppRateMassPerArea_Set DDI 6-6;
SG_MUL_VAL_ 2362179326 AppRateMassPerArea_Act DDI 7-7;
SG_MUL_VAL_ 2362179326 AppRateMassPerArea_Def DDI 8-8;
SG_MUL_VAL_ 2362179326 AppRateMassPerArea_Min DDI 9-9;
SG_MUL_VAL_ 2362179326 AppRateMassPerArea_Max DDI 10-10;
SG_MUL_VAL_ 2362179326 AppRateCountPerArea_Set DDI 11-11;
SG_MUL_VAL_ 2362179326 AppRateCountPerArea_Act DDI 12-12;
SG_MUL_VAL_ 2362179326 AppRateCountPerArea_Def DDI 13-13;
SG_MUL_VAL_ 2362179326 AppRateCountPerArea_Min DDI 14-14;
SG_MUL_VAL_ 2362179326 AppRateCountPerArea_Max DDI 15-15;
SG_MUL_VAL_ 2362179326 SetAppRateDistance_Set DDI 16-16;
SG_MUL_VAL_ 2362179326 AppRateDistance_Act DDI 17-17;
SG_MUL_VAL_ 2362179326 AppRateDistance_Def DDI 18-18;
SG_MUL_VAL_ 2362179326 AppRateDistance_Min DDI 19-19;
SG_MUL_VAL_ 2362179326 AppRateDistance_Max DDI 20-20;
SG_MUL_VAL_ 2362179326 AppRateVolumePerVolume_Set DDI 21-21;
SG_MUL_VAL_ 2362179326 AppRateVolumePerVolume_Act DDI 22-22;
SG_MUL_VAL_ 2362179326 AppRateVolumePerVolume_Def DDI 23-23;
SG_MUL_VAL_ 2362179326 AppRateVolumePerVolume_Min DDI 24-24;
SG_MUL_VAL_ 2362179326 AppRateVolumePerVolume_Max DDI 25-25;
SG_MUL_VAL_ 2362179326 AppRateMassPerMass_Set DDI 26-26;
SG_MUL_VAL_ 2362179326 AppRateMassPerMass_Act DDI 27-27;
SG_MUL_VAL_ 2362179326 AppRateMassPerMass_Def DDI 28-28;
SG_MUL_VAL_ 2362179326 AppRateMassPerMass_Min DDI 29-29;
SG_MUL_VAL_ 2362179326 AppRateMassPerMass_Max DDI 30-30;
SG_MUL_VAL_ 2362179326 AppRateVolumePerMass_Set DDI 31-31;
SG_MUL_VAL_ 2362179326 AppRateVolumePerMass_Act DDI 32-32;
SG_MUL_VAL_ 2362179326 AppRateVolumePerMass_Def DDI 33-33;
SG_MUL_VAL_ 2362179326 AppRateVolumePerMass_Min DDI 34-34;
SG_MUL_VAL_ 2362179326 AppRateVolumePerMass_Max DDI 35-35;
SG_MUL_VAL_ 2362179326 AppRateVolumePerTime_Set DDI 36-36;
SG_MUL_VAL_ 2362179326 AppRateVolumePerTime_Act DDI 37-37;
SG_MUL_VAL_ 2362179326 AppRateVolumePerTime_Def DDI 38-38;
SG_MUL_VAL_ 2362179326 AppRateVolumePerTime_Min DDI 39-39;
SG_MUL_VAL_ 2362179326 AppRateVolumePerTime_Max DDI 40-40;
SG_MUL_VAL_ 2362179326 AppRateMassPerTime_Set DDI 41-41;
SG_MUL_VAL_ 2362179326 AppRateMassPerTime_Act DDI 42-42;
SG_MUL_VAL_ 2362179326 AppRateMassPerTime_Def DDI 43-43;
SG_MUL_VAL_ 2362179326 AppRateMassPerTime_Min DDI 44-44;
SG_MUL_VAL_ 2362179326 AppRateMassPerTime_Max DDI 45-45;
SG_MUL_VAL_ 2362179326 AppRateCountPerTime_Set DDI 46-46;
SG_MUL_VAL_ 2362179326 AppRateCountPerTime_Act DDI 47-47;
SG_MUL_VAL_ 2362179326 AppRateCountPerTime_Def DDI 48-48;
SG_MUL_VAL_ 2362179326 AppRateCountPerTime_Min DDI 49-49;
SG_MUL_VAL_ 2362179326 AppRateCountPerTime_Max DDI 50-50;
SG_MUL_VAL_ 2362179326 SetTillageDepth_Set DDI 51-51;
SG_MUL_VAL_ 2362179326 TillageDepth_Act DDI 52-52;
SG_MUL_VAL_ 2362179326 TillageDepth_Def DDI 53-53;
SG_MUL_VAL_ 2362179326 TillageDepth_Min DDI 54-54;
SG_MUL_VAL_ 2362179326 TillageDepth_Max DDI 55-55;
SG_MUL_VAL_ 2362179326 SeedingDeph_Set DDI 56-56;
SG_MUL_VAL_ 2362179326 SeedingDeph_Act DDI 57-57;
SG_MUL_VAL_ 2362179326 SeedingDeph_Def DDI 58-58;
SG_MUL_VAL_ 2362179326 SeedingDeph_Min DDI 59-59;
SG_MUL_VAL_ 2362179326 SeedingDeph_Max DDI 60-60;
SG_MUL_VAL_ 2362179326 WorkingHeight_Set DDI 61-61;
SG_MUL_VAL_ 2362179326 WorkingHeight_Act DDI 62-62;
SG_MUL_VAL_ 2362179326 WorkingHeight_Def DDI 63-63;
SG_MUL_VAL_ 2362179326 WorkingHeight_Min DDI 64-64;
SG_MUL_VAL_ 2362179326 WorkingHeight_Max DDI 65-65;
SG_MUL_VAL_ 2362179326 WorkingWidth_Set DDI 66-66;
SG_MUL_VAL_ 2362179326 WorkingWidth_Act DDI 67-67;
SG_MUL_VAL_ 2362179326 WorkingWidth_Def DDI 68-68;
SG_MUL_VAL_ 2362179326 WorkingWidth_Min DDI 69-69;
SG_MUL_VAL_ 2362179326 WorkingWidth_Max DDI 70-70;
SG_MUL_VAL_ 2362179326 ContentAsVolume_Set DDI 71-71;
SG_MUL_VAL_ 2362179326 ContentAsVolume_Act DDI 72-72;
SG_MUL_VAL_ 2362179326 ContentAsVolume_Max DDI 73-73;
SG_MUL_VAL_ 2362179326 ContentAsMass_Set DDI 74-74;
SG_MUL_VAL_ 2362179326 ContentAsMass_Act DDI 75-75;
SG_MUL_VAL_ 2362179326 ContentAsMass_Max DDI 76-76;
SG_MUL_VAL_ 2362179326 ContentAsCount_Set DDI 77-77;
SG_MUL_VAL_ 2362179326 ContentAsCount_Act DDI 78-78;
SG_MUL_VAL_ 2362179326 ContentAsCount_Max DDI 79-79;
SG_MUL_VAL_ 2362179326 AccumulatedAppAsVolume DDI 80-80;
SG_MUL_VAL_ 2362179326 AccumulatedAppAsMass DDI 81-81;
SG_MUL_VAL_ 2362179326 AccumulatedAppAsCount DDI 82-82;
SG_MUL_VAL_ 2362179326 YieldVolumePerArea DDI 83-83;
SG_MUL_VAL_ 2362179326 YieldMassPerArea DDI 84-84;
SG_MUL_VAL_ 2362179326 YieldCountPerArea DDI 85-85;
SG_MUL_VAL_ 2362179326 YieldVolumePerTime DDI 86-86;
SG_MUL_VAL_ 2362179326 YieldMassPerTime DDI 87-87;
SG_MUL_VAL_ 2362179326 YieldCountPerTime DDI 88-88;
SG_MUL_VAL_ 2362179326 AccumulatedYieldAsVolume DDI 89-89;
SG_MUL_VAL_ 2362179326 AccumulatedYieldAsMass DDI 90-90;
SG_MUL_VAL_ 2362179326 AccumulatedYieldAsCount DDI 91-91;
SG_MUL_VAL_ 2362179326 CropYieldLossVolumePerArea DDI 92-92;
SG_MUL_VAL_ 2362179326 CropYieldLossMassPerArea DDI 93-93;
SG_MUL_VAL_ 2362179326 CropYieldLossCountPerArea DDI 94-94;
SG_MUL_VAL_ 2362179326 CropYieldLossVolumePerTime DDI 95-95;
SG_MUL_VAL_ 2362179326 CropYieldLossMassPerTime DDI 96-96;
SG_MUL_VAL_ 2362179326 CropYieldLossCountPerTime DDI 97-97;
SG_MUL_VAL_ 2362179326 CropYieldLoss DDI 98-98;
SG_MUL_VAL_ 2362179326 MoistureInCropYield DDI 99-99;
SG_MUL_VAL_ 2362179326 DirtMaterialInCropYield DDI 100-100;
SG_MUL_VAL_ 2362179326 BaleWidth_Set DDI 101-101;
SG_MUL_VAL_ 2362179326 BaleWidth_Act DDI 102-102;
SG_MUL_VAL_ 2362179326 BaleWidth_Def DDI 103-103;
SG_MUL_VAL_ 2362179326 BaleWidth_Min DDI 104-104;
SG_MUL_VAL_ 2362179326 BaleWidth_Max DDI 105-105;
SG_MUL_VAL_ 2362179326 BaleHeight_Set DDI 106-106;
SG_MUL_VAL_ 2362179326 BaleHeight_Act DDI 107-107;
SG_MUL_VAL_ 2362179326 BaleHeight_Def DDI 108-108;
SG_MUL_VAL_ 2362179326 BaleHeight_Min DDI 109-109;
SG_MUL_VAL_ 2362179326 BaleHeight_Max DDI 110-110;
SG_MUL_VAL_ 2362179326 BaleSize_Set DDI 111-111;
SG_MUL_VAL_ 2362179326 BaleSize_Act DDI 112-112;
SG_MUL_VAL_ 2362179326 BaleSize_Def DDI 113-113;
SG_MUL_VAL_ 2362179326 BaleSize_Min DDI 114-114;
SG_MUL_VAL_ 2362179326 BaleSize_Max DDI 115-115;
SG_MUL_VAL_ 2362179326 AccumulatedArea DDI 116-116;
SG_MUL_VAL_ 2362179326 AccumulatedDistanceInWork DDI 117-117;
SG_MUL_VAL_ 2362179326 AccumulatedDistanceOutWork DDI 118-118;
SG_MUL_VAL_ 2362179326 AccumulatedTimeInWork DDI 119-119;
SG_MUL_VAL_ 2362179326 AccumulatedTimeOutWork DDI 120-120;
SG_MUL_VAL_ 2362179326 PrdoucDensityMassPerArea DDI 121-121;
SG_MUL_VAL_ 2362179326 PrdoucDensityMassPerCount DDI 122-122;
SG_MUL_VAL_ 2362179326 PrdoucDensityVolumePerCount DDI 123-123;
